VERSION ""

NS_ :

BS_:

BU_: BAP_Tester BedienDisp_vo BedienSG_hi CGS DDA Gateway Gateway_PAG GurtMikrofon OTA_FC ZR_High ZR_LIMU ZR_MIB_TOP_ab_Gen3 ZR_Standard

BO_ 981 Licht_Anf_01: 8 Gateway
 SG_ Licht_Anf_01_CRC : 0|8@1+ (1,0) [0|255] "" Vector__XXX
 SG_ Licht_Anf_01_BZ : 8|4@1+ (1,0) [0|15] "" Vector__XXX
 SG_ BCM1_Kurvenlicht_links_Anf : 12|1@1+ (1,0) [0|1] "" ZR_High
 SG_ BCM1_Kurvenlicht_rechts_Anf : 13|1@1+ (1,0) [0|1] "" ZR_High
 SG_ BCM1_Standlicht_Anf : 14|1@1+ (1,0) [0|1] "" ZR_High
 SG_ BCM1_Abblendlicht_Anf : 15|1@1+ (1,0) [0|1] "" OTA_FC,ZR_High
 SG_ BCM1_Fernlicht_Anf : 16|1@1+ (1,0) [0|1] "" ZR_High
 SG_ BCM1_Nebellicht_Anf : 17|1@1+ (1,0) [0|1] "" ZR_High
 SG_ BCM1_Parklicht_li_Anf : 18|1@1+ (1,0) [0|1] "" ZR_High
 SG_ BCM1_Parklicht_re_Anf : 19|1@1+ (1,0) [0|1] "" ZR_High
 SG_ BCM1_Nebelschluss_Ahg_Anf : 20|1@1+ (1,0) [0|1] "" ZR_High
 SG_ BCM1_Nebelschluss_Fzg_Anf : 21|1@1+ (1,0) [0|1] "" ZR_High
 SG_ BCM1_Schlusslicht_Anf : 22|1@1+ (1,0) [0|1] "" ZR_High
 SG_ BCM_Rueckfahrlicht_Anf : 23|1@1+ (1,0) [0|1] "" ZR_High,ZR_MIB_TOP_ab_Gen3,ZR_Standard
 SG_ BCM1_Signaturlicht_Anf : 24|1@1+ (1,0) [0|1] "" Vector__XXX
 SG_ BCM1_Umfeldleuchten_Anf : 25|1@1+ (1,0) [0|1] "" ZR_High
 SG_ BCM1_Tagfahrlicht_Anf : 26|1@1+ (1,0) [0|1] "" ZR_High
 SG_ BCM1_Regenlicht_Anf : 27|1@1+ (1,0) [0|1] "" ZR_High
 SG_ BCM1_Autobahnlicht_Anf : 28|1@1+ (1,0) [0|1] "" ZR_High
 SG_ BCM1_Touristen_Licht_Anf : 29|1@1+ (1,0) [0|1] "" ZR_High
 SG_ BCM1_CH_aktiv : 30|1@1+ (1,0) [0|1] "" ZR_High
 SG_ BCM1_LH_aktiv : 31|1@1+ (1,0) [0|1] "" ZR_High
 SG_ BCM1_Gleitende_Leuchtw_Anf : 32|1@1+ (1,0) [0|1] "" ZR_High
 SG_ BCM1_GLW_Fernlicht_Anf : 33|1@1+ (1,0) [0|1] "" ZR_High
 SG_ BCM1_Adaptive_Lichtvert_Anf : 34|1@1+ (1,0) [0|1] "" ZR_High
 SG_ BCM1_FoD_Sperrung_WiBli : 35|2@1+ (1,0) [0|3] "" Vector__XXX
 SG_ BCM1_FOD_Sperrung_Animationen_HL : 37|2@1+ (1,0) [0|3] "" Vector__XXX
 SG_ BCM1_Animationssperrung : 39|1@1+ (1,0) [0|1] "" Vector__XXX
 SG_ BCM1_CH_LH_aktiv : 40|1@1+ (1,0) [0|1] "" ZR_High
 SG_ BCM1_Allwetterlicht_Anf : 41|1@1+ (1,0) [0|1] "" ZR_High
 SG_ BCM1_Schlusslicht_Signatur : 60|4@1+ (1,0) [0|15] "" Vector__XXX

BO_ 982 Licht_hinten_01: 8 Gateway
 SG_ BCM2_Bremsl_durch_ECD : 5|1@1+ (1,0) [0|1] "" OTA_FC,ZR_High
 SG_ LH_Aussenlicht_def : 7|1@1+ (1,0) [0|1] "" ZR_High
 SG_ LH_Standlicht_H_aktiv : 8|1@1+ (1,0) [0|1] "" OTA_FC,ZR_High
 SG_ LH_Parklicht_HL_aktiv : 9|1@1+ (1,0) [0|1] "" OTA_FC,ZR_High
 SG_ LH_Parklicht_HR_aktiv : 10|1@1+ (1,0) [0|1] "" OTA_FC,ZR_High
 SG_ LH_Bremslicht_H_aktiv : 11|1@1+ (1,0) [0|1] "" OTA_FC,ZR_High
 SG_ LH_Nebelschluss_aktiv : 12|1@1+ (1,0) [0|1] "" OTA_FC,ZR_High
 SG_ LH_Rueckfahrlicht_aktiv : 13|1@1+ (1,0) [0|1] "" OTA_FC,ZR_High
 SG_ LH_Blinker_HL_akt : 14|1@1+ (1,0) [0|1] "" OTA_FC,ZR_High
 SG_ LH_Blinker_HR_akt : 15|1@1+ (1,0) [0|1] "" OTA_FC,ZR_High
 SG_ LH_Blinker_li_def : 16|1@1+ (1,0) [0|1] "" ZR_High
 SG_ LH_Bremsl_li_def : 17|1@1+ (1,0) [0|1] "" ZR_High
 SG_ LH_Schlusslicht_li_def : 18|1@1+ (1,0) [0|1] "" ZR_High
 SG_ LH_Rueckf_li_def : 19|1@1+ (1,0) [0|1] "" ZR_High
 SG_ LH_Nebel_li_def : 20|1@1+ (1,0) [0|1] "" ZR_High
 SG_ LH_Schluss_Brems_Nebel_li_def : 21|1@1+ (1,0) [0|1] "" ZR_High
 SG_ LH_Schluss_Brems_Nebel_re_def : 22|1@1+ (1,0) [0|1] "" ZR_High
 SG_ LH_Zusatzschlussl_def : 23|1@1+ (1,0) [0|1] "" Vector__XXX
 SG_ LH_Schluss_Brems_li_def : 24|1@1+ (1,0) [0|1] "" ZR_High
 SG_ LH_Schluss_Nebel_li_def : 25|1@1+ (1,0) [0|1] "" ZR_High
 SG_ LH_SL_BRL_BLK_li_def : 26|1@1+ (1,0) [0|1] "" ZR_High
 SG_ LH_Brems_Blk_li_def : 27|1@1+ (1,0) [0|1] "" Vector__XXX
 SG_ LH_Diag_Status_re_def : 28|1@1+ (1,0) [0|1] "" ZR_High
 SG_ LH_Diag_Status_li_def : 29|1@1+ (1,0) [0|1] "" ZR_High
 SG_ LH_Diag_LED_li_def : 30|1@1+ (1,0) [0|1] "" ZR_High
 SG_ LH_Diag_LED_re_def : 31|1@1+ (1,0) [0|1] "" ZR_High
 SG_ LH_Blinker_re_def : 32|1@1+ (1,0) [0|1] "" ZR_High
 SG_ LH_Bremsl_re_def : 33|1@1+ (1,0) [0|1] "" ZR_High
 SG_ LH_Schlusslicht_re_def : 34|1@1+ (1,0) [0|1] "" ZR_High
 SG_ LH_Rueckf_re_def : 35|1@1+ (1,0) [0|1] "" ZR_High
 SG_ LH_Nebel_re_def : 36|1@1+ (1,0) [0|1] "" ZR_High
 SG_ LH_Schluss_Brems_mi_def : 37|1@1+ (1,0) [0|1] "" Vector__XXX
 SG_ LH_Schluss_Brems_re_def : 40|1@1+ (1,0) [0|1] "" ZR_High
 SG_ LH_Schluss_Nebel_re_def : 41|1@1+ (1,0) [0|1] "" ZR_High
 SG_ LH_SL_BRL_BLK_re_def : 42|1@1+ (1,0) [0|1] "" ZR_High
 SG_ LH_Brems_Blk_re_def : 43|1@1+ (1,0) [0|1] "" ZR_High
 SG_ LH_Kennzl_def : 48|1@1+ (1,0) [0|1] "" ZR_High
 SG_ LH_3_Bremsl_def : 49|1@1+ (1,0) [0|1] "" ZR_High
 SG_ LH_Nebel_mi_def : 50|1@1+ (1,0) [0|1] "" ZR_High
 SG_ LH_Rueckf_mi_def : 51|1@1+ (1,0) [0|1] "" ZR_High
 SG_ LH_Schlusslicht_mi_def : 52|1@1+ (1,0) [0|1] "" Vector__XXX
 SG_ LH_Bremsl_mi_def : 53|1@1+ (1,0) [0|1] "" Vector__XXX
 SG_ LH_Bremsl_li_ges_def : 54|1@1+ (1,0) [0|1] "" ZR_High
 SG_ LH_Bremsl_re_ges_def : 55|1@1+ (1,0) [0|1] "" ZR_High

BO_ 987 Gateway_72: 8 Gateway_MQB
 SG_ BCM_01_alt : 0|1@1+ (1,0) [0|1] "" Airbag_MQB
 SG_ SMLS_01_alt : 1|1@1+ (1,0) [0|1] "" Motor_Diesel_MQB,Motor_Otto_MQB
 SG_ ZV_02_alt : 2|1@1+ (1,0) [0|1] "" Getriebe_DQ_Hybrid_MQB,Getriebe_DQ_MQB,Motor_Diesel_MQB,Motor_Hybrid_MQB,Motor_Otto_MQB
 SG_ Wischer_01_alt : 3|1@1+ (1,0) [0|1] "" Motor_Diesel_MQB,Motor_Hybrid_MQB,Motor_Otto_MQB
 SG_ Anhaenger_01_alt : 4|1@1+ (1,0) [0|1] "" Getriebe_DQ_Hybrid_MQB,Getriebe_DQ_MQB
 SG_ Klima_Sensor_02_alt : 5|1@1+ (1,0) [0|1] "" Getriebe_DQ_Hybrid_MQB,Getriebe_DQ_MQB,Motor_Diesel_MQB,Motor_Hybrid_MQB,Motor_Otto_MQB
 SG_ VSG_01_alt : 6|1@1+ (1,0) [0|1] "" Airbag_MQB
 SG_ Klima_01_alt : 7|1@1+ (1,0) [0|1] "" Vector__XXX
 SG_ WFS_01_alt : 8|1@1+ (1,0) [0|1] "" Vector__XXX
 SG_ Licht_Anf_01_alt : 9|1@1+ (1,0) [0|1] "" Vector__XXX
 SG_ ZV_HFS_offen : 20|1@1+ (1,0) [0|1] "" Vector__XXX
 SG_ ZV_HBFS_offen : 21|1@1+ (1,0) [0|1] "" Vector__XXX
 SG_ VS_VD_offen_ver : 22|1@1+ (1,0) [0|1] "" Airbag_MQB
 SG_ VS_VD_zu_ver : 23|1@1+ (1,0) [0|1] "" Vector__XXX
 SG_ ZV_BT_offen : 24|1@1+ (1,0) [0|1] "" Vector__XXX
 SG_ BCM1_Rueckfahrlicht_Schalter : 25|1@1+ (1,0) [0|1] "" Airbag_MQB
 SG_ ZV_FT_offen : 26|1@1+ (1,0) [0|1] "" Getriebe_DQ_Hybrid_MQB,Getriebe_DQ_MQB,Motor_Diesel_MQB,Motor_Hybrid_MQB,Motor_Otto_MQB
 SG_ Wischer_vorne_aktiv : 27|1@1+ (1,0) [0|1] "" Motor_Diesel_MQB,Motor_Hybrid_MQB,Motor_Otto_MQB
 SG_ AAG_Anhaenger_erkannt : 28|1@1+ (1,0) [0|1] "" Getriebe_DQ_Hybrid_MQB,Getriebe_DQ_MQB
 SG_ BCM1_MH_Schalter : 29|1@1+ (1,0) [0|1] "" Vector__XXX
 SG_ ZV_HD_offen : 30|1@1+ (1,0) [0|1] "" Vector__XXX
 SG_ Waschen_vorne_aktiv : 31|1@1+ (1,0) [0|1] "" Vector__XXX
 SG_ KL_Thermomanagement : 32|2@1+ (1,0) [0|3] "" Vector__XXX
 SG_ WFS_Schluessel_Fahrberecht : 34|4@1+ (1,0) [0|15] "" Vector__XXX
 SG_ BCM1_RFahrlicht_Fzg_Anf : 38|1@1+ (1,0) [0|1] "" Vector__XXX
 SG_ BCM1_RFahrlicht_Ahg_Anf : 39|1@1+ (1,0) [0|1] "" Vector__XXX
 SG_ BH_Fernlicht : 49|1@1+ (1,0) [0|1] "" Vector__XXX
 SG_ BH_Blinker_li : 50|1@1+ (1,0) [0|1] "" Motor_Diesel_MQB,Motor_Otto_MQB
 SG_ BH_Blinker_re : 51|1@1+ (1,0) [0|1] "" Motor_Diesel_MQB,Motor_Otto_MQB
 SG_ BCM1_OBD_FStatus_ATemp : 52|4@1+ (1,0) [0|15] "" Getriebe_DQ_Hybrid_MQB,Getriebe_DQ_MQB,Motor_Diesel_MQB,Motor_Hybrid_MQB,Motor_Otto_MQB
 SG_ BCM1_Aussen_Temp_ungef : 56|8@1+ (0.5,-50) [-50|76] "Unit_DegreCelsi" Getriebe_DQ_Hybrid_MQB,Getriebe_DQ_MQB,Motor_Diesel_MQB,Motor_Hybrid_MQB,Motor_Otto_MQB

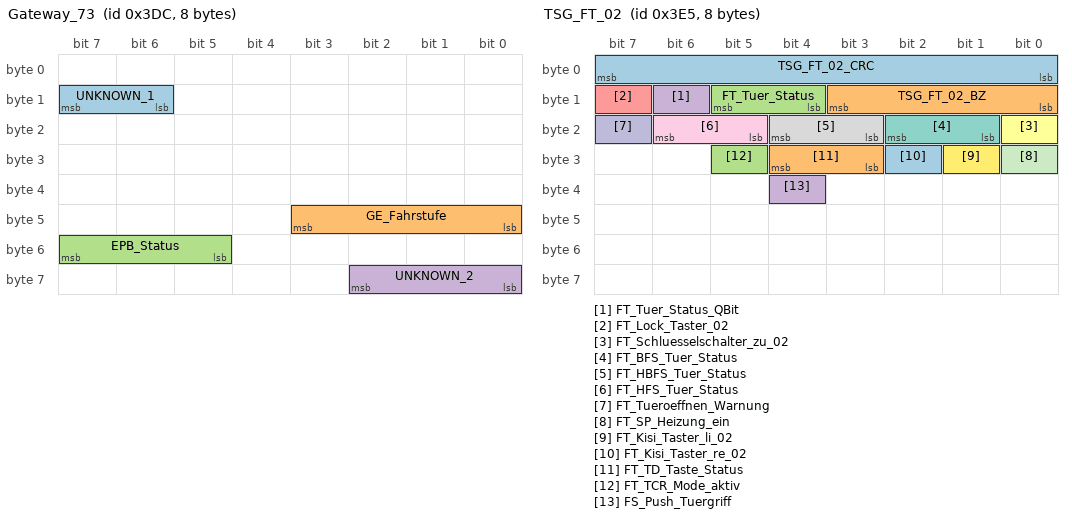
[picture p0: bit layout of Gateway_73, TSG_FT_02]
BO_ 988 Gateway_73: 8 XXX
 SG_ UNKNOWN_1 : 15|2@0+ (1,0) [0|3] "" XXX
 SG_ GE_Fahrstufe : 40|4@1+ (1,0) [0|15] "" XXX
 SG_ EPB_Status : 53|3@1+ (1,0) [0|7] "" XXX
 SG_ UNKNOWN_2 : 58|3@0+ (1,0) [0|7] "" XXX

BO_ 997 TSG_FT_02: 8 Gateway
 SG_ TSG_FT_02_CRC : 0|8@1+ (1,0) [0|255] "" Vector__XXX
 SG_ TSG_FT_02_BZ : 8|4@1+ (1,0) [0|15] "" Vector__XXX
 SG_ FT_Tuer_Status : 12|2@1+ (1,0) [0|3] "" OTA_FC,ZR_High
 SG_ FT_Tuer_Status_QBit : 14|1@1+ (1,0) [0|1] "" ZR_High
 SG_ FT_Lock_Taster_02 : 15|1@1+ (1,0) [0|1] "" ZR_High
 SG_ FT_Schluesselschalter_zu_02 : 16|1@1+ (1,0) [0|1] "" ZR_High
 SG_ FT_BFS_Tuer_Status : 17|2@1+ (1,0) [0|3] "" ZR_High
 SG_ FT_HBFS_Tuer_Status : 19|2@1+ (1,0) [0|3] "" ZR_High
 SG_ FT_HFS_Tuer_Status : 21|2@1+ (1,0) [0|3] "" ZR_High
 SG_ FT_Tueroeffnen_Warnung : 23|1@1+ (1,0) [0|1] "" Vector__XXX
 SG_ FT_SP_Heizung_ein : 24|1@1+ (1,0) [0|1] "" Vector__XXX
 SG_ FT_Kisi_Taster_li_02 : 25|1@1+ (1,0) [0|1] "" ZR_High
 SG_ FT_Kisi_Taster_re_02 : 26|1@1+ (1,0) [0|1] "" ZR_High
 SG_ FT_TD_Taste_Status : 27|2@1+ (1,0) [0|3] "" ZR_High
 SG_ FT_TCR_Mode_aktiv : 29|1@1+ (1,0) [0|1] "" Vector__XXX
 SG_ FS_Push_Tuergriff : 36|1@1+ (1,0) [0|1] "" Vector__XXX

BO_ 1004 MEB_TSK_01: 8 XXX
 SG_ TSK_State : 53|3@1+ (1,0) [0|7] "" XXX

BO_ 1031 PLA_04: 8 XXX

BO_ 1122 PSD_04: 8 ZR_High
 SG_ PSD_Segment_ID : 0|6@1+ (1,0) [2|63] "" Gateway,Gateway_PAG
 SG_ PSD_Vorgaenger_Segment_ID : 6|6@1+ (1,0) [2|63] "" Gateway,Gateway_PAG
 SG_ PSD_Segmentlaenge : 12|7@1+ (2,0) [0|254] "Unit_Meter" Gateway,Gateway_PAG,OTA_FC
 SG_ PSD_Strassenkategorie : 19|3@1+ (1,0) [0|7] "" Gateway,Gateway_PAG,OTA_FC
 SG_ PSD_Endkruemmung : 22|8@1+ (1,0) [0|254] "Unit_None" Gateway,Gateway_PAG
 SG_ PSD_Endkruemmung_Vorz : 30|1@1+ (1,0) [0|1] "" Gateway,Gateway_PAG
 SG_ PSD_Idenditaets_ID : 31|6@1+ (1,0) [2|63] "" Gateway,Gateway_PAG
 SG_ PSD_ADAS_Qualitaet : 37|1@1+ (1,0) [0|1] "" Gateway,Gateway_PAG
 SG_ PSD_wahrscheinlichster_Pfad : 38|1@1+ (1,0) [0|1] "" Gateway,Gateway_PAG
 SG_ PSD_Geradester_Pfad : 39|1@1+ (1,0) [0|1] "" Gateway,Gateway_PAG
 SG_ PSD_Fahrspuren_Anzahl : 40|3@1+ (1,0) [0|7] "" Gateway,Gateway_PAG,OTA_FC
 SG_ PSD_Bebauung : 43|1@1+ (1,0) [0|1] "" Gateway,Gateway_PAG
 SG_ PSD_Segment_Komplett : 44|1@1+ (1,0) [0|1] "" Gateway,Gateway_PAG
 SG_ PSD_Rampe : 45|2@1+ (1,0) [0|3] "" Gateway,Gateway_PAG
 SG_ PSD_Anfangskruemmung : 47|8@1+ (1,0) [0|254] "" Gateway,Gateway_PAG
 SG_ PSD_Anfangskruemmung_Vorz : 55|1@1+ (1,0) [0|1] "" Gateway,Gateway_PAG
 SG_ PSD_Abzweigerichtung : 56|1@1+ (1,0) [0|1] "" Gateway,Gateway_PAG
 SG_ PSD_Abzweigewinkel : 57|7@1+ (1.417323,0) [0|180.000021] "" Gateway,Gateway_PAG

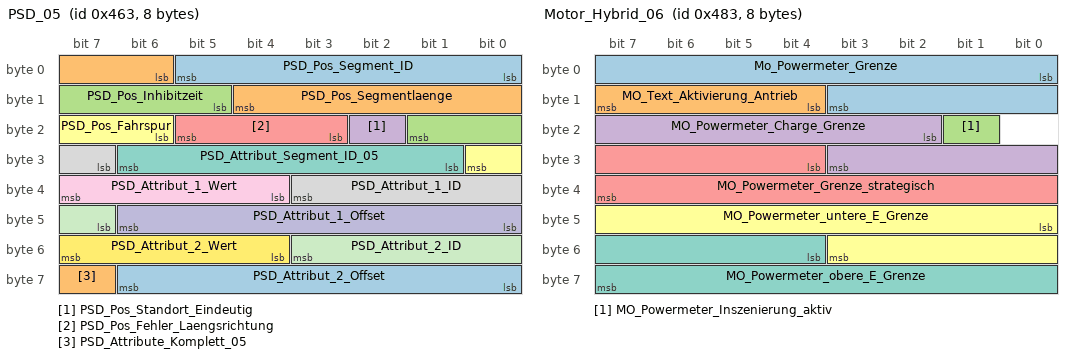
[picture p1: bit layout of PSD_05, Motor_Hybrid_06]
BO_ 1123 PSD_05: 8 ZR_High
 SG_ PSD_Pos_Segment_ID : 0|6@1+ (1,0) [2|63] "" Gateway,Gateway_PAG
 SG_ PSD_Pos_Segmentlaenge : 6|7@1+ (2,0) [0|254] "Unit_Meter" Gateway,Gateway_PAG
 SG_ PSD_Pos_Inhibitzeit : 13|5@1+ (10,0) [0|310] "Unit_MilliSecon" Gateway,Gateway_PAG
 SG_ PSD_Pos_Standort_Eindeutig : 18|1@1+ (1,0) [0|1] "" Gateway,Gateway_PAG
 SG_ PSD_Pos_Fehler_Laengsrichtung : 19|3@1+ (1,0) [0|7] "" Gateway,Gateway_PAG
 SG_ PSD_Pos_Fahrspur : 22|3@1+ (1,0) [0|7] "" Gateway,Gateway_PAG,OTA_FC
 SG_ PSD_Attribut_Segment_ID_05 : 25|6@1+ (1,0) [2|63] "" Gateway,Gateway_PAG
 SG_ PSD_Attribut_1_ID : 31|5@1+ (1,0) [1|31] "" Gateway,Gateway_PAG
 SG_ PSD_Attribut_1_Wert : 36|4@1+ (1,0) [0|15] "" Gateway,Gateway_PAG
 SG_ PSD_Attribut_1_Offset : 40|7@1+ (2,0) [0|254] "Unit_Meter" Gateway,Gateway_PAG
 SG_ PSD_Attribut_2_ID : 47|5@1+ (1,0) [1|31] "" Gateway,Gateway_PAG
 SG_ PSD_Attribut_2_Wert : 52|4@1+ (1,0) [0|15] "" Gateway,Gateway_PAG
 SG_ PSD_Attribut_2_Offset : 56|7@1+ (2,0) [0|254] "Unit_Meter" Gateway,Gateway_PAG
 SG_ PSD_Attribute_Komplett_05 : 63|1@1+ (1,0) [0|1] "" Gateway,Gateway_PAG

BO_ 1124 PSD_06: 8 ZR_High
 SG_ PSD_06_Mux M : 0|3@1+ (1,0) [0|7] "" Gateway,Gateway_PAG
 SG_ PSD_Sys_Segment_ID m0 : 3|6@1+ (1,0) [2|63] "" Gateway,Gateway_PAG
 SG_ PSD_Sys_Laendercode m0 : 9|8@1+ (1,0) [0|255] "" Gateway,Gateway_PAG
 SG_ PSD_Sys_Geschwindigkeit_Einheit m0 : 17|1@1+ (1,0) [0|1] "" Gateway,Gateway_PAG
 SG_ PSD_Sys_Verkehrsrichtung m0 : 18|1@1+ (1,0) [0|1] "" Gateway,Gateway_PAG
 SG_ PSD_Sys_Geometrieguete m0 : 19|2@1+ (1,0) [0|3] "" Gateway,Gateway_PAG
 SG_ PSD_Sys_Mapmatchingguete m0 : 21|2@1+ (1,0) [0|3] "" Gateway,Gateway_PAG
 SG_ PSD_Sys_Alter_Karte m0 : 23|3@1+ (1,0) [0|7] "" Gateway,Gateway_PAG
 SG_ PSD_Sys_Zielfuehrung m0 : 26|1@1+ (1,0) [0|1] "" Gateway,Gateway_PAG,OTA_FC
 SG_ PSD_Sys_US_State m0 : 27|6@1+ (1,0) [0|63] "" Gateway,Gateway_PAG
 SG_ PSD_Sys_Quali_Geometrien m0 : 33|3@1+ (1,0) [0|7] "Unit_None" Gateway,Gateway_PAG
 SG_ PSD_Sys_Quali_Ortsinfo m0 : 36|2@1+ (1,0) [0|3] "Unit_None" Gateway,Gateway_PAG
 SG_ PSD_Sys_Quali_verfuegbar m0 : 38|1@1+ (1,0) [0|1] "" Gateway,Gateway_PAG
 SG_ PSD_Sys_Zielfuehrung_geaendert m0 : 39|1@1+ (1,0) [0|1] "" Gateway,Gateway_PAG
 SG_ PSD_Sys_Geometrieguete_erweitert m0 : 40|8@1+ (1,0) [0|255] "" Gateway,Gateway_PAG
 SG_ PSD_Sys_Quali_sonstige_Attribute m0 : 48|3@1+ (1,0) [0|7] "Unit_None" Gateway,Gateway_PAG
 SG_ PSD_Sys_Quali_Steigungen m0 : 51|3@1+ (1,0) [0|7] "" Gateway,Gateway_PAG
 SG_ PSD_Sys_Quali_Strassenkennz m0 : 54|3@1+ (1,0) [0|7] "Unit_None" Gateway,Gateway_PAG
 SG_ PSD_Sys_Quali_Tempolimits m0 : 57|3@1+ (1,0) [0|7] "Unit_None" Gateway,Gateway_PAG
 SG_ PSD_Sys_Quali_Vorfahrtsregelung m0 : 60|3@1+ (1,0) [0|7] "Unit_None" Gateway,Gateway_PAG
 SG_ PSD_Attribut_Segment_ID m1 : 3|6@1+ (1,0) [2|63] "" Gateway,Gateway_PAG
 SG_ PSD_Attribut_3_ID m1 : 9|5@1+ (1,0) [1|31] "" Gateway,Gateway_PAG
 SG_ PSD_Attribut_3_Offset m1 : 14|7@1+ (2,0) [0|254] "Unit_Meter" Gateway,Gateway_PAG
 SG_ PSD_Attribut_3_Wert m1 : 21|4@1+ (1,0) [0|15] "" Gateway,Gateway_PAG
 SG_ PSD_Attribut_4_ID m1 : 25|5@1+ (1,0) [1|31] "" Gateway,Gateway_PAG
 SG_ PSD_Attribut_4_Wert m1 : 30|4@1+ (1,0) [0|15] "" Gateway,Gateway_PAG
 SG_ PSD_Attribut_4_Offset m1 : 34|7@1+ (2,0) [0|254] "Unit_Meter" Gateway,Gateway_PAG
 SG_ PSD_Attribut_5_ID m1 : 41|5@1+ (1,0) [1|31] "" Gateway,Gateway_PAG
 SG_ PSD_Attribut_5_Offset m1 : 46|7@1+ (2,0) [0|254] "Unit_Meter" Gateway,Gateway_PAG
 SG_ PSD_Attribut_5_Wert m1 : 53|4@1+ (1,0) [0|15] "" Gateway,Gateway_PAG
 SG_ PSD_Attribute_Komplett_06 m1 : 57|1@1+ (1,0) [0|1] "" Gateway,Gateway_PAG
 SG_ PSD_Ges_Segment_ID m2 : 3|6@1+ (1,0) [2|63] "" Gateway,Gateway_PAG
 SG_ PSD_Ges_Offset m2 : 9|7@1+ (2,0) [0|254] "Unit_Meter" Gateway,Gateway_PAG
 SG_ PSD_Ges_Geschwindigkeit m2 : 16|5@1+ (1,0) [0|31] "" Gateway,Gateway_PAG,OTA_FC
 SG_ PSD_Ges_Typ m2 : 21|2@1+ (1,0) [0|3] "" Gateway,Gateway_PAG
 SG_ PSD_Ges_Spur_Geschw_Begrenzung m2 : 23|6@1+ (1,0) [0|63] "" Gateway,Gateway_PAG
 SG_ PSD_Ges_Geschwindigkeit_Gespann m2 : 29|2@1+ (1,0) [0|3] "" Gateway,Gateway_PAG
 SG_ PSD_Ges_Geschwindigkeit_Witter m2 : 31|2@1+ (1,0) [0|3] "" Gateway,Gateway_PAG
 SG_ PSD_Ges_Geschwindigkeit_Tag_Anf m2 : 33|3@1+ (1,0) [0|7] "" Gateway,Gateway_PAG
 SG_ PSD_Ges_Geschwindigkeit_Tag_Ende m2 : 36|3@1+ (1,0) [0|7] "" Gateway,Gateway_PAG
 SG_ PSD_Ges_Geschwindigkeit_Std_Anf m2 : 39|5@1+ (1,0) [0|24] "Unit_Hours" Gateway,Gateway_PAG
 SG_ PSD_Ges_Geschwindigkeit_Std_Ende m2 : 44|5@1+ (1,0) [0|24] "Unit_Hours" Gateway,Gateway_PAG
 SG_ PSD_Ges_Ueberholverbot m2 : 49|2@1+ (1,0) [0|3] "" Gateway,Gateway_PAG
 SG_ PSD_Ges_Wechselverkehrszeichen m2 : 51|3@1+ (1,0) [0|7] "" Gateway,Gateway_PAG
 SG_ PSD_Wechselverkehrszeichen_Typ m2 : 54|2@1+ (1,0) [0|3] "" Gateway,Gateway_PAG
 SG_ PSD_Ges_Gesetzlich_Kategorie m2 : 56|3@1+ (1,0) [0|7] "" Gateway,Gateway_PAG
 SG_ PSD_Ges_Gesetzlich_Zusatz m2 : 59|2@1+ (1,0) [0|3] "" Gateway,Gateway_PAG
 SG_ PSD_Ges_Verkehrszeichen_Quelle m2 : 61|2@1+ (1,0) [0|3] "" Gateway,Gateway_PAG
 SG_ PSD_Ges_Attribute_Komplett m2 : 63|1@1+ (1,0) [0|1] "" Gateway,Gateway_PAG
 SG_ PSD_Baum_Laenge_VZ m3 : 3|1@1+ (1,0) [0|1] "" Gateway,Gateway_PAG
 SG_ PSD_Baum_Laenge m3 : 4|25@1+ (1e-05,0) [0|180] "Unit_DegreOfArc" Gateway,Gateway_PAG
 SG_ PSD_Baum_Breite_VZ m3 : 29|1@1+ (1,0) [0|1] "" Gateway,Gateway_PAG
 SG_ PSD_Baum_Breite m3 : 30|24@1+ (1e-05,0) [0|90] "Unit_DegreOfArc" Gateway,Gateway_PAG
 SG_ PSD_Baum_Ausrichtung m3 : 54|10@1+ (0.3515625,0) [0|359.6484375] "Unit_DegreOfArc" Gateway,Gateway_PAG
 SG_ PSD_Steigung_1_Segment_ID m4 : 3|6@1+ (1,0) [2|63] "" Gateway,Gateway_PAG
 SG_ PSD_Steigung_1_A_Steigung m4 : 9|7@1+ (0.12,0) [0|15] "Unit_PerCent" Gateway,Gateway_PAG
 SG_ PSD_Steigung_1_A_Vorz m4 : 16|1@1+ (1,0) [0|1] "" Gateway,Gateway_PAG
 SG_ PSD_Steigung_1_A_Offset m4 : 17|7@1+ (2,0) [0|254] "Unit_Meter" Gateway,Gateway_PAG
 SG_ PSD_Steigung_1_B_Steigung m4 : 24|7@1+ (0.12,0) [0|15] "Unit_PerCent" Gateway,Gateway_PAG
 SG_ PSD_Steigung_1_B_Vorz m4 : 31|1@1+ (1,0) [0|1] "" Gateway,Gateway_PAG
 SG_ PSD_Steigung_1_B_Offset m4 : 32|7@1+ (2,0) [0|254] "Unit_Meter" Gateway,Gateway_PAG
 SG_ PSD_Steigung_1_Attribute_kompl m4 : 39|1@1+ (1,0) [0|1] "" Gateway,Gateway_PAG
 SG_ PSD_Steigung_2_Segment_ID m4 : 40|6@1+ (1,0) [2|63] "" Gateway,Gateway_PAG
 SG_ PSD_Steigung_2_Steigung m4 : 46|7@1+ (0.12,0) [0|15] "Unit_PerCent" Gateway,Gateway_PAG
 SG_ PSD_Steigung_2_Vorz m4 : 53|1@1+ (1,0) [0|1] "" Gateway,Gateway_PAG
 SG_ PSD_Steigung_2_Offset m4 : 54|7@1+ (2,0) [0|254] "Unit_Meter" Gateway,Gateway_PAG
 SG_ PSD_Steigung_2_Attribute_kompl m4 : 61|1@1+ (1,0) [0|1] "" Gateway,Gateway_PAG

BO_ 1153 MainUnit_01: 8 ZR_High
 SG_ ZR_LoGeWa_Event_Kombiwarnung : 0|4@1+ (1,0) [0|15] "" Gateway,Gateway_PAG
 SG_ Nav_FoD_Status : 4|3@1+ (1,0) [0|7] "" Gateway,Gateway_PAG
 SG_ MIB_Tongenerator_PH_verfuegbar : 9|3@1+ (1,0) [0|7] "" Gateway,Gateway_PAG
 SG_ MMI_Counter_Bedienevent : 12|4@1+ (1,0) [0|15] "" Gateway,Gateway_PAG
 SG_ DSSS_Warning : 16|5@1+ (1,0) [0|31] "" Gateway,Gateway_PAG
 SG_ ZR_Kindersicherung_RSE : 21|1@1+ (1,0) [0|1] "" Gateway,Gateway_PAG
 SG_ ZR_RSE_aktivieren : 22|1@1+ (1,0) [0|1] "" Gateway,Gateway_PAG
 SG_ MMI_SDS_aktiv : 23|1@1+ (1,0) [0|1] "" Gateway,Gateway_PAG
 SG_ MU_SecondDisplay : 24|3@1+ (1,0) [0|7] "" Gateway,Gateway_PAG
 SG_ MMI_Telefon_aktiv : 27|1@1+ (1,0) [0|1] "" Gateway,Gateway_PAG
 SG_ MMI_Gurt_Mic_ref : 28|1@1+ (1,0) [0|1] "" Gateway,Gateway_PAG,GurtMikrofon
 SG_ ZR_Sta_Inszenierung : 29|2@1+ (1,0) [0|3] "" Gateway,Gateway_PAG
 SG_ MMI_Gauges_active : 31|1@1+ (1,0) [0|1] "" BedienDisp_vo,Gateway,Gateway_PAG
 SG_ MU_Update_Time : 32|8@1+ (0.1,0) [0|25.5] "Unit_Hours" Gateway,Gateway_PAG
 SG_ ZR_MXB_Manoever_Ansage : 42|2@1+ (1,0) [0|3] "" Gateway,Gateway_PAG
 SG_ ZR_LAPP_Sondermodus_Status : 44|2@1+ (1,0) [0|3] "" DDA,Gateway,Gateway_PAG
 SG_ MMI_StartStopp_Info : 46|2@1+ (1,0) [0|3] "" Gateway,Gateway_PAG
 SG_ ZR_Parken_Sondermodus : 48|4@1+ (1,0) [0|15] "" DDA,Gateway,Gateway_PAG
 SG_ ZR_Rundenbewertung : 52|4@1+ (1,0) [0|15] "" Gateway,Gateway_PAG
 SG_ ZR_Rundenfortschritt : 56|8@1+ (0.5,0) [0|100] "Unit_PerCent" Gateway,Gateway_PAG

BO_ 1155 Motor_Hybrid_06: 8 Gateway
 SG_ Mo_Powermeter_Grenze : 0|12@1+ (1,0) [0|4092] "" ZR_High,ZR_LIMU,ZR_MIB_TOP_ab_Gen3
 SG_ MO_Text_Aktivierung_Antrieb : 12|4@1+ (1,0) [0|15] "" Vector__XXX
 SG_ MO_Powermeter_Inszenierung_aktiv : 17|1@1+ (1,0) [0|1] "" Vector__XXX
 SG_ MO_Powermeter_Charge_Grenze : 18|10@1+ (1,0) [0|1021] "Unit_None" Vector__XXX
 SG_ MO_Powermeter_Grenze_strategisch : 28|12@1+ (1,0) [0|4093] "Unit_None" Vector__XXX
 SG_ MO_Powermeter_untere_E_Grenze : 40|12@1+ (1,0) [0|4093] "Unit_None" Vector__XXX
 SG_ MO_Powermeter_obere_E_Grenze : 52|12@1+ (1,0) [0|4093] "Unit_None" Vector__XXX

BO_ 1163 BEM_06: 8 XXX
 SG_ CRC : 0|8@1+ (1,0) [0|255] "" XXX
 SG_ CHK : 8|4@1+ (1,0) [0|15] "" XXX

BO_ 1175 Parkhilfe_01: 8 Gateway
 SG_ PH_Visualisierung : 0|3@1+ (1,0) [0|7] "" AWC
 SG_ PDC_Tonausgabe_Front : 4|4@1+ (1,0) [0|15] "" Vector__XXX
 SG_ PDC_Tonausgabe_Heck : 8|4@1+ (1,0) [0|15] "" Vector__XXX
 SG_ PH_nachtr_Stopp_Anf : 12|1@1+ (1,0) [0|1] "" Vector__XXX
 SG_ PH_Abschaltursache : 13|3@1+ (1,0) [0|7] "" AWC
 SG_ PH_Opt_Anzeige_V_ein : 16|1@1+ (1,0) [0|1] "" Vector__XXX
 SG_ PH_Opt_Anzeige_H_ein : 17|1@1+ (1,0) [0|1] "" Vector__XXX
 SG_ PH_Opt_Anz_V_Hindernis : 18|1@1+ (1,0) [0|1] "" Vector__XXX
 SG_ PH_Opt_Anz_H_Hindernis : 19|1@1+ (1,0) [0|1] "" Vector__XXX
 SG_ PH_Tongeber_V_aktiv : 20|1@1+ (1,0) [0|1] "" Vector__XXX
 SG_ PH_Tongeber_H_aktiv : 21|1@1+ (1,0) [0|1] "" Vector__XXX
 SG_ PH_Tongeber_mute : 22|1@1+ (1,0) [0|1] "" Vector__XXX
 SG_ PH_Anf_Audioabsenkung : 23|1@1+ (1,0) [0|1] "" Vector__XXX
 SG_ PH_Tongeber_H_verfuegbar : 24|1@1+ (1,0) [0|1] "" Vector__XXX
 SG_ PLA_Anf_Aufschaltung_RVC : 25|1@1+ (1,0) [0|1] "" Vector__XXX
 SG_ PH_Taster : 28|2@1+ (1,0) [0|3] "" Vector__XXX
 SG_ PH_Anf_Verdeck : 30|2@1+ (1,0) [0|3] "" Vector__XXX
 SG_ PH_Frequenz_hinten : 32|4@1+ (1,0) [0|15] "" Vector__XXX
 SG_ PH_Lautstaerke_hinten : 36|4@1+ (1,0) [0|15] "" Vector__XXX
 SG_ PH_Frequenz_vorn : 40|4@1+ (1,0) [0|15] "" Vector__XXX
 SG_ PH_Lautstaerke_vorn : 44|4@1+ (1,0) [0|15] "" Vector__XXX
 SG_ PH_StartStopp_Info : 49|2@1+ (1,0) [0|3] "" Vector__XXX
 SG_ PH_Stoermeldung : 52|4@1+ (1,0) [0|15] "" Vector__XXX
 SG_ PH_defekt : 56|1@1+ (1,0) [0|1] "" Vector__XXX
 SG_ PH_gestoert : 57|1@1+ (1,0) [0|1] "" Vector__XXX
 SG_ PH_Systemzustand : 58|3@1+ (1,0) [0|7] "" AWC
 SG_ PH_Display_Kundenwunsch : 61|2@1+ (1,0) [0|3] "" Vector__XXX

BO_ 1283 HVK_01: 8 Gateway
 SG_ HVK_01_CRC : 0|8@1+ (1,0) [0|255] "" BMC_MLBevo,DCDC_800V_PAG,DCDC_HV,DCDC_HV_02,FCU_MLBevo_FCEV,Ladegeraet_2,Ladegeraet_Konzern,LE1,LE2,LE_MLBevo,TME
 SG_ HVK_01_BZ : 8|4@1+ (1,0) [0|15] "" BMC_MLBevo,DCDC_800V_PAG,DCDC_HV,DCDC_HV_02,FCU_MLBevo_FCEV,Ladegeraet_2,Ladegeraet_Konzern,LE1,LE2,LE_MLBevo,TME
 SG_ HVK_Istmodus_Anf : 12|1@1+ (1,0) [0|1] "" BMC_MLBevo,DCDC_HV,FCU_MLBevo_FCEV,Ladegeraet_2,Ladegeraet_Konzern,LE1,LE2,LE_MLBevo
 SG_ HVK_TN1_Sollmodus : 13|2@1+ (1,0) [0|3] "" DCDC_HV_02,FCU_MLBevo_FCEV
 SG_ HVK_MO_EmSollzustand : 16|8@1+ (1,0) [0|255] "" FCU_MLBevo_FCEV
 SG_ HVK_BMS_Sollmodus : 24|3@1+ (1,0) [0|7] "" BMC_MLBevo,FCU_MLBevo_FCEV
 SG_ HVK_DCDC_Sollmodus : 27|3@1+ (1,0) [0|7] "" DCDC_800V_PAG,DCDC_HV,FCU_MLBevo_FCEV,LE_MLBevo
 SG_ HVK_EKK_Sollmodus : 30|3@1+ (1,0) [0|7] "" FCU_MLBevo_FCEV,TME
 SG_ HVK_HVPTC_Sollmodus : 33|3@1+ (1,0) [0|7] "" FCU_MLBevo_FCEV,TME
 SG_ HVK_HVLM_Sollmodus : 36|3@1+ (1,0) [0|7] "" DCDC_HV_02,FCU_MLBevo_FCEV,Ladegeraet_Konzern
 SG_ HVK_HV_Netz_Warnungen : 39|2@1+ (1,0) [0|3] "" FCU_MLBevo_FCEV
 SG_ HV_Bordnetz_aktiv : 41|1@1+ (1,0) [0|1] "" DCDC_HV_02,FCU_MLBevo_FCEV,Ladegeraet_Konzern,LE1,LE2,LE_MLBevo
 SG_ HV_Bordnetz_Fehler : 42|1@1+ (1,0) [0|1] "" FCU_MLBevo_FCEV,Ladegeraet_Konzern,TME
 SG_ HVK_Gesamtst_Spgfreiheit : 43|2@1+ (1,0) [0|3] "" FCU_MLBevo_FCEV
 SG_ HVK_AktiveEntladung_Anf : 45|1@1+ (1,0) [0|1] "" DCDC_800V_PAG,DCDC_HV,DCDC_HV_02,FCU_MLBevo_FCEV,LE1,LE2,LE_MLBevo
 SG_ HVK_Iso_Messung_Start : 50|3@1+ (1,0) [0|7] "" BMC_MLBevo,FCU_MLBevo_FCEV
 SG_ HVK_DCDC_EKK_Sollmodus : 62|2@1+ (1,0) [0|3] "" DCDC_800V_PAG,FCU_MLBevo_FCEV

BO_ 1312 Airbag_02: 8 Gateway
 SG_ LoGeWa_Event_Kombiwarnung : 12|4@1+ (1,0) [0|15] "" ZR_High
 SG_ AB_Anforderung_eCall : 16|1@1+ (1,0) [0|1] "" ZR_High
 SG_ AB_Anprall_Seite_Beifahrer : 17|1@1+ (1,0) [0|1] "" Vector__XXX
 SG_ AB_Anprall_Rollover : 18|1@1+ (1,0) [0|1] "" Vector__XXX
 SG_ AB_Anprall_FGS : 19|1@1+ (1,0) [0|1] "" Vector__XXX
 SG_ AB_Anprall_Front_Beifahrer : 20|1@1+ (1,0) [0|1] "" Vector__XXX
 SG_ AB_Anprall_Front_Fahrer : 21|1@1+ (1,0) [0|1] "" Vector__XXX
 SG_ AB_Anprall_Heck_Beifahrer : 22|1@1+ (1,0) [0|1] "" Vector__XXX
 SG_ AB_Anprall_Heck_Fahrer : 23|1@1+ (1,0) [0|1] "" Vector__XXX
 SG_ AB_Wickelklappung_Reihe2_MI : 24|2@1+ (1,0) [0|3] "" Vector__XXX
 SG_ AB_Belegung_VB : 26|2@1+ (1,0) [0|3] "" BedienSG_hi,GurtMikrofon,ZR_High,ZR_LIMU,ZR_MIB_TOP_ab_Gen3
 SG_ AB_Abschaltanf_SIH_BF : 28|1@1+ (1,0) [0|1] "" ZR_High
 SG_ AB_Anprall_Seite_Fahrer : 29|1@1+ (1,0) [0|1] "" Vector__XXX
 SG_ SC_PAO_Schriftzug_Anf : 30|2@1+ (1,0) [0|3] "" ZR_High
 SG_ SC_PAO_ON_Anf : 32|2@1+ (1,0) [0|3] "" ZR_High
 SG_ SC_PAO_OFF_Anf : 34|2@1+ (1,0) [0|3] "" ZR_High
 SG_ AB_Crashschwere : 36|3@1+ (1,0) [0|7] "" Vector__XXX
 SG_ AB_Anforderung_USM : 39|1@1+ (1,0) [0|1] "" ZR_Standard
 SG_ AB_Gurtschloss_FA : 40|2@1+ (1,0) [0|3] "" BedienSG_hi,GurtMikrofon,ZR_High
 SG_ AB_Gurtschloss_BF : 42|2@1+ (1,0) [0|3] "" BedienSG_hi,GurtMikrofon,ZR_High,ZR_LIMU,ZR_MIB_TOP_ab_Gen3
 SG_ AB_Gurtschloss_Reihe2_FA : 44|2@1+ (1,0) [0|3] "" BedienSG_hi,ZR_High,ZR_LIMU,ZR_MIB_TOP_ab_Gen3
 SG_ AB_Gurtschloss_Reihe2_MI : 46|2@1+ (1,0) [0|3] "" BedienSG_hi,ZR_High,ZR_LIMU,ZR_MIB_TOP_ab_Gen3
 SG_ AB_Gurtschloss_Reihe2_BF : 48|2@1+ (1,0) [0|3] "" BedienSG_hi,ZR_High,ZR_LIMU,ZR_MIB_TOP_ab_Gen3
 SG_ AB_Gurtschloss_Reihe3_FA : 50|2@1+ (1,0) [0|3] "" BedienSG_hi,ZR_High
 SG_ AB_Gurtschloss_Reihe3_MI : 52|2@1+ (1,0) [0|3] "" BedienSG_hi,ZR_High
 SG_ AB_Gurtschloss_Reihe3_BF : 54|2@1+ (1,0) [0|3] "" BedienSG_hi,ZR_High
 SG_ AB_Sitzpos_Sens_FA : 56|2@1+ (1,0) [0|3] "" ZR_High
 SG_ AB_Sitzpos_Sens_BF : 58|2@1+ (1,0) [0|3] "" ZR_High
 SG_ AB_Wickelklappung_Reihe2_BF : 60|2@1+ (1,0) [0|3] "" ZR_High
 SG_ AB_Wickelklappung_Reihe2_FA : 62|2@1+ (1,0) [0|3] "" ZR_High

BO_ 1349 Airbag_04: 8 Gateway
 SG_ AB_Gurtwarn_Reihe2_FA : 20|2@1+ (1,0) [0|3] "" Vector__XXX
 SG_ AB_Gurtwarn_Reihe2_BF : 22|2@1+ (1,0) [0|3] "" Vector__XXX
 SG_ AbstWarn_MV_FAS_Fkt_Status : 24|2@1+ (1,0) [0|3] "" ZR_High
 SG_ WarnBrems_Charisma_Status : 26|2@1+ (1,0) [0|3] "" Vector__XXX
 SG_ WarnBrems_Charisma_FahrPr : 28|4@1+ (1,0) [0|15] "" Vector__XXX
 SG_ AB_Gurtwarn_Reihe2_MI : 32|2@1+ (1,0) [0|3] "" Vector__XXX
 SG_ AB_Gurtwarn_Reihe3_FA : 34|2@1+ (1,0) [0|3] "" Vector__XXX
 SG_ AB_Gurtwarn_Reihe3_MI : 36|2@1+ (1,0) [0|3] "" Vector__XXX
 SG_ AB_Gurtwarn_Reihe3_BF : 38|2@1+ (1,0) [0|3] "" Vector__XXX
 SG_ LGI_FAS_Fkt_Status : 40|2@1+ (1,0) [0|3] "" ZR_High
 SG_ PreCrash_FAS_Fkt_Status : 42|3@1+ (1,0) [0|7] "" ZR_High
 SG_ AB_SBR_hinten_verbau : 48|2@1+ (1,0) [0|3] "" Vector__XXX
 SG_ AWV_Einstellung_System_ASG : 51|1@1+ (1,0) [0|1] "" Vector__XXX
 SG_ AWV_Einstellung_Warnung_ASG : 52|3@1+ (1,0) [0|7] "" Vector__XXX
 SG_ SC_PreSense_Modus_Warnung_NV : 55|3@1+ (1,0) [0|7] "" Vector__XXX
 SG_ SC_PreSense_Modus_Warnung_MV : 58|3@1+ (1,0) [0|7] "" Vector__XXX
 SG_ SC_PreSense_Modus_System_MV : 61|1@1+ (1,0) [0|1] "" Vector__XXX
 SG_ SC_PreSense_Modus_System_NV : 62|1@1+ (1,0) [0|1] "" Vector__XXX
 SG_ SC_PreSense_Modus_System_KAS : 63|1@1+ (1,0) [0|1] "" Vector__XXX

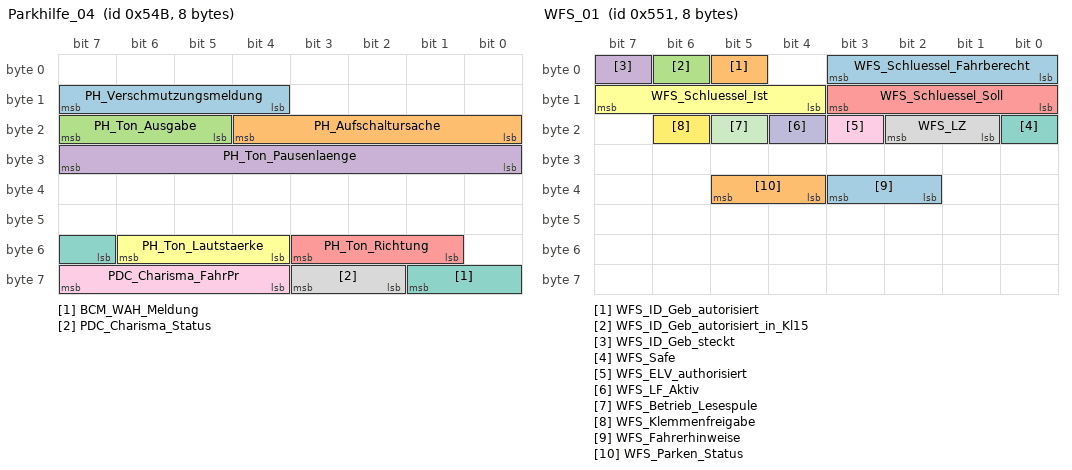
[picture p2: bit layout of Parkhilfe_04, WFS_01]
BO_ 1355 Parkhilfe_04: 8 Gateway
 SG_ PH_Verschmutzungsmeldung : 12|4@1+ (1,0) [0|15] "" Vector__XXX
 SG_ PH_Aufschaltursache : 16|5@1+ (1,0) [0|31] "" AWC
 SG_ PH_Ton_Ausgabe : 21|3@1+ (1,0) [0|7] "" Vector__XXX
 SG_ PH_Ton_Pausenlaenge : 24|8@1+ (1,0) [0|255] "" Vector__XXX
 SG_ PH_Ton_Richtung : 49|3@1+ (1,0) [0|7] "" Vector__XXX
 SG_ PH_Ton_Lautstaerke : 52|3@1+ (1,0) [0|7] "" Vector__XXX
 SG_ BCM_WAH_Meldung : 55|3@1+ (1,0) [0|7] "" Vector__XXX
 SG_ PDC_Charisma_Status : 58|2@1+ (1,0) [0|3] "" Vector__XXX
 SG_ PDC_Charisma_FahrPr : 60|4@1+ (1,0) [0|15] "" Vector__XXX

BO_ 1361 WFS_01: 8 Gateway
 SG_ WFS_Schluessel_Fahrberecht : 0|4@1+ (1,0) [0|15] "" ZR_High,ZR_LIMU,ZR_MIB_TOP_ab_Gen3,ZR_Standard
 SG_ WFS_ID_Geb_autorisiert : 5|1@1+ (1,0) [0|1] "" ZR_High
 SG_ WFS_ID_Geb_autorisiert_in_Kl15 : 6|1@1+ (1,0) [0|1] "" Vector__XXX
 SG_ WFS_ID_Geb_steckt : 7|1@1+ (1,0) [0|1] "" ZR_High
 SG_ WFS_Schluessel_Soll : 8|4@1+ (1,0) [0|15] "" ZR_High,ZR_LIMU,ZR_MIB_TOP_ab_Gen3,ZR_Standard
 SG_ WFS_Schluessel_Ist : 12|4@1+ (1,0) [0|15] "" ZR_High,ZR_LIMU,ZR_MIB_TOP_ab_Gen3,ZR_Standard
 SG_ WFS_Safe : 16|1@1+ (1,0) [0|1] "" Vector__XXX
 SG_ WFS_LZ : 17|2@1+ (1,0) [0|3] "" Vector__XXX
 SG_ WFS_ELV_authorisiert : 19|1@1+ (1,0) [0|1] "" Vector__XXX
 SG_ WFS_LF_Aktiv : 20|1@1+ (1,0) [0|1] "" Vector__XXX
 SG_ WFS_Betrieb_Lesespule : 21|1@1+ (1,0) [0|1] "" Vector__XXX
 SG_ WFS_Klemmenfreigabe : 22|1@1+ (1,0) [0|1] "" Vector__XXX
 SG_ WFS_Fahrerhinweise : 34|2@1+ (1,0) [0|3] "" Vector__XXX
 SG_ WFS_Parken_Status : 36|2@1+ (1,0) [0|3] "" Vector__XXX

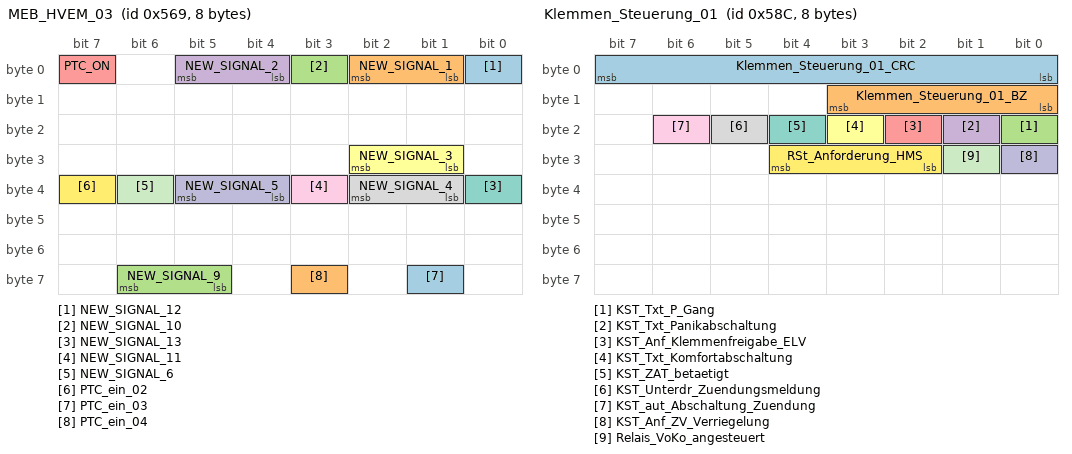
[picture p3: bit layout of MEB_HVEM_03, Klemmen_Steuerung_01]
BO_ 1385 MEB_HVEM_03: 8 XXX
 SG_ NEW_SIGNAL_12 : 0|1@0+ (1,0) [0|1] "" XXX
 SG_ NEW_SIGNAL_1 : 1|2@1+ (1,0) [0|3] "" XXX
 SG_ NEW_SIGNAL_10 : 3|1@0+ (1,0) [0|1] "" XXX
 SG_ NEW_SIGNAL_2 : 4|2@1+ (1,0) [0|3] "" XXX
 SG_ PTC_ON : 7|1@0+ (1,0) [0|1] "" XXX
 SG_ NEW_SIGNAL_3 : 25|2@1+ (1,0) [0|3] "" XXX
 SG_ NEW_SIGNAL_13 : 32|1@0+ (1,0) [0|1] "" XXX
 SG_ NEW_SIGNAL_4 : 33|2@1+ (1,0) [0|3] "" XXX
 SG_ NEW_SIGNAL_11 : 35|1@0+ (1,0) [0|1] "" XXX
 SG_ NEW_SIGNAL_5 : 36|2@1+ (1,0) [0|3] "" XXX
 SG_ NEW_SIGNAL_6 : 38|1@0+ (1,0) [0|1] "" XXX
 SG_ PTC_ein_02 : 39|1@0+ (1,0) [0|1] "" XXX
 SG_ PTC_ein_03 : 57|1@0+ (1,0) [0|1] "" XXX
 SG_ PTC_ein_04 : 59|1@0+ (1,0) [0|1] "" XXX
 SG_ NEW_SIGNAL_9 : 61|2@1+ (1,0) [0|3] "" XXX

BO_ 1411 ZV_02: 8 Gateway
 SG_ BCM_FH_Freigabe : 12|1@1+ (1,0) [0|1] "" BedienDisp_vo
 SG_ BCM_Komfortfkt_Freigabe : 13|1@1+ (1,0) [0|1] "" Vector__XXX
 SG_ BCM_HSK_Freigabe : 14|1@1+ (1,0) [0|1] "" Vector__XXX
 SG_ BCM_Verdeck_Freigabe : 15|1@1+ (1,0) [0|1] "" ZR_High
 SG_ ZV_verriegelt_intern_ist : 16|1@1+ (1,0) [0|1] "" DDA,OTA_FC,ZR_High
 SG_ ZV_verriegelt_extern_ist : 17|1@1+ (1,0) [0|1] "" DDA,OTA_FC,ZR_High
 SG_ ZV_verriegelt_intern_soll : 18|1@1+ (1,0) [0|1] "" ZR_High
 SG_ ZV_verriegelt_extern_soll : 19|1@1+ (1,0) [0|1] "" OTA_FC,ZR_High,ZR_LIMU,ZR_MIB_TOP_ab_Gen3,ZR_Standard
 SG_ ZV_gesafet_extern_ist : 20|1@1+ (1,0) [0|1] "" ZR_High
 SG_ ZV_gesafet_extern_soll : 21|1@1+ (1,0) [0|1] "" ZR_High,ZR_LIMU,ZR_MIB_TOP_ab_Gen3
 SG_ ZV_Einzeltuerentriegelung : 22|1@1+ (1,0) [0|1] "" Vector__XXX
 SG_ ZV_Heckeinzelentriegelung : 23|1@1+ (1,0) [0|1] "" Vector__XXX
 SG_ ZV_FT_offen : 24|1@1+ (1,0) [0|1] "" DDA,OTA_FC,ZR_High,ZR_LIMU,ZR_MIB_TOP_ab_Gen3,ZR_Standard
 SG_ ZV_BT_offen : 25|1@1+ (1,0) [0|1] "" DDA,OTA_FC,ZR_High,ZR_LIMU,ZR_MIB_TOP_ab_Gen3,ZR_Standard
 SG_ ZV_HFS_offen : 26|1@1+ (1,0) [0|1] "" DDA,OTA_FC,ZR_High,ZR_LIMU,ZR_MIB_TOP_ab_Gen3,ZR_Standard
 SG_ ZV_HBFS_offen : 27|1@1+ (1,0) [0|1] "" DDA,OTA_FC,ZR_High,ZR_LIMU,ZR_MIB_TOP_ab_Gen3,ZR_Standard
 SG_ ZV_HD_offen : 28|1@1+ (1,0) [0|1] "" DDA,OTA_FC,ZR_High,ZR_LIMU,ZR_MIB_TOP_ab_Gen3,ZR_Standard
 SG_ ZV_HS_offen : 29|1@1+ (1,0) [0|1] "" OTA_FC,ZR_High
 SG_ IRUE_aktiv : 30|1@1+ (1,0) [0|1] "" ZR_High
 SG_ DWA_aktiv : 31|1@1+ (1,0) [0|1] "" ZR_High
 SG_ HD_Hauptraste : 32|1@1+ (1,0) [0|1] "" OTA_FC,ZR_High
 SG_ HD_Vorraste : 33|1@1+ (1,0) [0|1] "" OTA_FC,ZR_High
 SG_ FFB_CarFinder : 38|1@1+ (1,0) [0|1] "" Vector__XXX
 SG_ FFB_Komfortoeffnen : 39|1@1+ (1,0) [0|1] "" Vector__XXX
 SG_ FFB_Komfortschliessen : 40|1@1+ (1,0) [0|1] "" Vector__XXX
 SG_ ZV_Schluessel_Zugang : 42|4@1+ (1,0) [0|15] "" ZR_High
 SG_ ZV_SafeFunktion_aktiv : 46|1@1+ (1,0) [0|1] "" ZR_High
 SG_ FBS_Warn_Schluessel_Batt : 47|1@1+ (1,0) [0|1] "" ZR_High
 SG_ ZV_Oeffnungsmodus : 48|2@1+ (1,0) [0|3] "" Vector__XXX
 SG_ HFS_verriegelt : 50|1@1+ (1,0) [0|1] "" OTA_FC
 SG_ HFS_gesafet : 51|1@1+ (1,0) [0|1] "" Vector__XXX
 SG_ HBFS_verriegelt : 52|1@1+ (1,0) [0|1] "" OTA_FC
 SG_ HBFS_gesafet : 53|1@1+ (1,0) [0|1] "" Vector__XXX
 SG_ ZV_ist_Zustand_verfuegbar : 54|1@1+ (1,0) [0|1] "" OTA_FC,ZR_High
 SG_ IRUE_Taster_Fkts_LED : 55|1@1+ (1,0) [0|1] "" ZR_High
 SG_ ZV_Tankklappe_offen : 56|1@1+ (1,0) [0|1] "" ZR_High
 SG_ ZV_Rollo_auf : 57|1@1+ (1,0) [0|1] "" ZR_High
 SG_ ZV_Rollo_zu : 58|1@1+ (1,0) [0|1] "" ZR_High
 SG_ ZV_SAD_auf : 59|1@1+ (1,0) [0|1] "" ZR_High
 SG_ ZV_SAD_zu : 60|1@1+ (1,0) [0|1] "" ZR_High
 SG_ BCM_Tankklappensteller_Fehler : 61|1@1+ (1,0) [0|1] "" ZR_High
 SG_ ZV_verriegelt_soll : 62|2@1+ (1,0) [0|3] "" Vector__XXX

BO_ 1413 Systeminfo_01: 8 Gateway
 SG_ SI_Sammel_SG_Fehler : 0|6@1+ (1,0) [0|60] "" ZR_High,ZR_LIMU,ZR_MIB_TOP_ab_Gen3,ZR_Standard
 SG_ SI_Diagnose_Aktiv : 7|1@1+ (1,0) [0|1] "" ZR_High,ZR_LIMU,ZR_MIB_TOP_ab_Gen3,ZR_Standard
 SG_ SI_QRS_Mode : 8|1@1+ (1,0) [0|1] "" BedienSG_hi,ZR_High,ZR_LIMU,ZR_MIB_TOP_ab_Gen3,ZR_Standard
 SG_ SI_T_Mode : 9|1@1+ (1,0) [0|1] "" BedienDisp_vo,BedienSG_hi,DDA,ZR_High,ZR_LIMU,ZR_MIB_TOP_ab_Gen3,ZR_Standard
 SG_ SI_NWDF : 10|1@1+ (1,0) [0|1] "" BedienDisp_vo,BedienSG_hi,DDA,ZR_High,ZR_LIMU,ZR_MIB_TOP_ab_Gen3,ZR_Standard
 SG_ SI_NWDF_gueltig : 11|1@1+ (1,0) [0|1] "" BedienDisp_vo,BedienSG_hi,DDA,ZR_High,ZR_LIMU,ZR_MIB_TOP_ab_Gen3,ZR_Standard
 SG_ SI_Sammelfehler : 12|1@1+ (1,0) [0|1] "" ZR_High,ZR_LIMU,ZR_MIB_TOP_ab_Gen3,ZR_Standard
 SG_ GW_KD_Fehler : 13|1@1+ (1,0) [0|1] "" ZR_High,ZR_MIB_TOP_ab_Gen3,ZR_Standard
 SG_ SI_T_Schutz : 14|1@1+ (1,0) [0|1] "" BedienSG_hi,ZR_High,ZR_LIMU,ZR_MIB_TOP_ab_Gen3,ZR_Standard
 SG_ SI_BUS_01 : 16|1@1+ (1,0) [0|1] "" ZR_High,ZR_LIMU,ZR_MIB_TOP_ab_Gen3,ZR_Standard
 SG_ SI_BUS_02 : 17|1@1+ (1,0) [0|1] "" ZR_High,ZR_LIMU,ZR_MIB_TOP_ab_Gen3,ZR_Standard
 SG_ SI_BUS_03 : 18|1@1+ (1,0) [0|1] "" BedienSG_hi,DDA,ZR_High,ZR_LIMU,ZR_MIB_TOP_ab_Gen3,ZR_Standard
 SG_ SI_BUS_04 : 19|1@1+ (1,0) [0|1] "" BedienSG_hi,ZR_High,ZR_LIMU,ZR_MIB_TOP_ab_Gen3,ZR_Standard
 SG_ SI_BUS_05 : 20|1@1+ (1,0) [0|1] "" ZR_High,ZR_LIMU,ZR_MIB_TOP_ab_Gen3,ZR_Standard
 SG_ SI_BUS_06 : 21|1@1+ (1,0) [0|1] "" ZR_High,ZR_LIMU,ZR_MIB_TOP_ab_Gen3,ZR_Standard
 SG_ SI_BUS_07 : 22|1@1+ (1,0) [0|1] "" ZR_High,ZR_LIMU,ZR_MIB_TOP_ab_Gen3,ZR_Standard
 SG_ SI_BUS_08 : 23|1@1+ (1,0) [0|1] "" ZR_High,ZR_LIMU,ZR_MIB_TOP_ab_Gen3,ZR_Standard
 SG_ SI_BUS_09 : 24|1@1+ (1,0) [0|1] "" ZR_High,ZR_LIMU,ZR_MIB_TOP_ab_Gen3,ZR_Standard
 SG_ SI_BUS_10 : 25|1@1+ (1,0) [0|1] "" BedienSG_hi,DDA,ZR_High,ZR_LIMU,ZR_MIB_TOP_ab_Gen3,ZR_Standard
 SG_ SI_BUS_11 : 26|1@1+ (1,0) [0|1] "" ZR_High,ZR_LIMU,ZR_MIB_TOP_ab_Gen3,ZR_Standard
 SG_ SI_BUS_12 : 27|1@1+ (1,0) [0|1] "" DDA,ZR_High,ZR_LIMU,ZR_MIB_TOP_ab_Gen3,ZR_Standard
 SG_ SI_BUS_13 : 28|1@1+ (1,0) [0|1] "" ZR_High,ZR_LIMU,ZR_MIB_TOP_ab_Gen3,ZR_Standard
 SG_ SI_BUS_14 : 29|1@1+ (1,0) [0|1] "" ZR_High,ZR_LIMU,ZR_MIB_TOP_ab_Gen3,ZR_Standard
 SG_ SI_BUS_15 : 30|1@1+ (1,0) [0|1] "" ZR_High,ZR_LIMU,ZR_MIB_TOP_ab_Gen3,ZR_Standard
 SG_ SI_Bus_Identifikation : 32|8@1+ (1,0) [0|255] "" OTA_FC,ZR_High,ZR_LIMU,ZR_MIB_TOP_ab_Gen3,ZR_Standard
 SG_ SI_CAB : 40|24@1+ (1,0) [0|16777215] "" BedienSG_hi,OTA_FC,ZR_High,ZR_LIMU,ZR_MIB_TOP_ab_Gen3,ZR_Standard

BO_ 1420 Klemmen_Steuerung_01: 8 Gateway
 SG_ Klemmen_Steuerung_01_CRC : 0|8@1+ (1,0) [0|255] "" Vector__XXX
 SG_ Klemmen_Steuerung_01_BZ : 8|4@1+ (1,0) [0|15] "" Vector__XXX
 SG_ KST_Txt_P_Gang : 16|1@1+ (1,0) [0|1] "" Vector__XXX
 SG_ KST_Txt_Panikabschaltung : 17|1@1+ (1,0) [0|1] "" Vector__XXX
 SG_ KST_Anf_Klemmenfreigabe_ELV : 18|1@1+ (1,0) [0|1] "" Vector__XXX
 SG_ KST_Txt_Komfortabschaltung : 19|1@1+ (1,0) [0|1] "" Vector__XXX
 SG_ KST_ZAT_betaetigt : 20|1@1+ (1,0) [0|1] "" ZR_High
 SG_ KST_Unterdr_Zuendungsmeldung : 21|1@1+ (1,0) [0|1] "" Vector__XXX
 SG_ KST_aut_Abschaltung_Zuendung : 22|1@1+ (1,0) [0|1] "" Vector__XXX
 SG_ KST_Anf_ZV_Verriegelung : 24|1@1+ (1,0) [0|1] "" Vector__XXX
 SG_ Relais_VoKo_angesteuert : 25|1@1+ (1,0) [0|1] "" Vector__XXX
 SG_ RSt_Anforderung_HMS : 26|3@1+ (1,0) [0|7] "" Vector__XXX

BO_ 1426 Kessy_04: 8 XXX

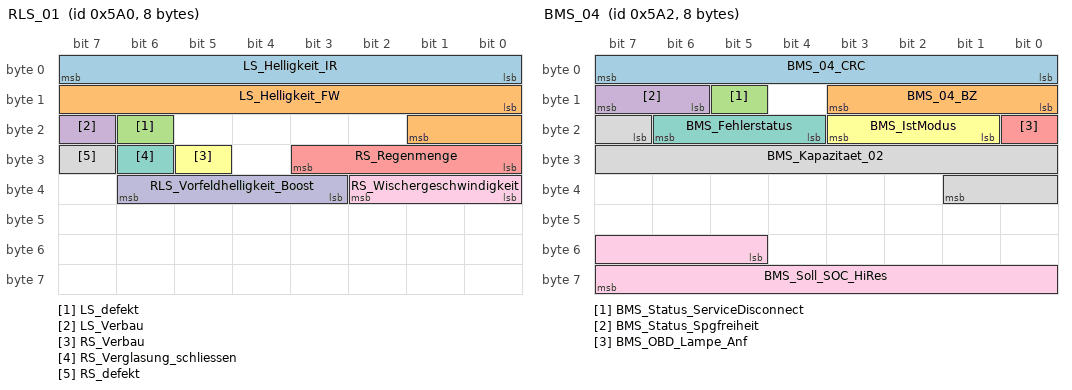
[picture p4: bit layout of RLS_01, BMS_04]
BO_ 1440 RLS_01: 8 Gateway
 SG_ LS_Helligkeit_IR : 0|8@1+ (400,0) [0|101200] "Unit_Lux" ZR_High
 SG_ LS_Helligkeit_FW : 8|10@1+ (6,0) [0|6126] "Unit_Lux" ZR_High
 SG_ LS_defekt : 22|1@1+ (1,0) [0|1] "" ZR_High
 SG_ LS_Verbau : 23|1@1+ (1,0) [0|1] "" ZR_High
 SG_ RS_Regenmenge : 24|4@1+ (10,0) [0|100] "Unit_PerCent" OTA_FC,ZR_High
 SG_ RS_Verbau : 29|1@1+ (1,0) [0|1] "" ZR_High
 SG_ RS_Verglasung_schliessen : 30|1@1+ (1,0) [0|1] "" ZR_High
 SG_ RS_defekt : 31|1@1+ (1,0) [0|1] "" ZR_High
 SG_ RS_Wischergeschwindigkeit : 32|3@1+ (1,0) [0|7] "" OTA_FC,ZR_High
 SG_ RLS_Vorfeldhelligkeit_Boost : 35|4@1+ (1,0) [0|15] "" ZR_High

BO_ 1442 BMS_04: 8 BMC_MLBevo
 SG_ BMS_04_CRC : 0|8@1+ (1,0) [0|255] "" Gateway,Gateway_PAG,Sub_Gateway
 SG_ BMS_04_BZ : 8|4@1+ (1,0) [0|15] "" Gateway,Gateway_PAG,Sub_Gateway
 SG_ BMS_Status_ServiceDisconnect : 13|1@1+ (1,0) [0|1] "" DCDC_800V_PAG,DCDC_HV,Gateway,Gateway_PAG,Sub_Gateway
 SG_ BMS_Status_Spgfreiheit : 14|2@1+ (1,0) [0|3] "" Gateway,Gateway_PAG,Sub_Gateway
 SG_ BMS_OBD_Lampe_Anf : 16|1@1+ (1,0) [0|1] "" Gateway,Gateway_PAG,Sub_Gateway
 SG_ BMS_IstModus : 17|3@1+ (1,0) [0|7] "" AWC,Gateway,Gateway_PAG,Ladegeraet_Konzern,LE1,LE2,LE2_3_MLBevo_LB,Sub_Gateway,TME
 SG_ BMS_Fehlerstatus : 20|3@1+ (1,0) [0|7] "" AWC,DCDC_800V_PAG,DCDC_HV,Gateway,Gateway_PAG,Ladegeraet_Konzern,Sub_Gateway
 SG_ BMS_Kapazitaet_02 : 23|11@1+ (0.2,0) [0|409.2] "Unit_AmperHour" Gateway,Gateway_PAG,Ladegeraet_Konzern,Sub_Gateway
 SG_ BMS_Soll_SOC_HiRes : 53|11@1+ (0.05,0) [0|100] "Unit_PerCent" Gateway,Gateway_PAG,Sub_Gateway

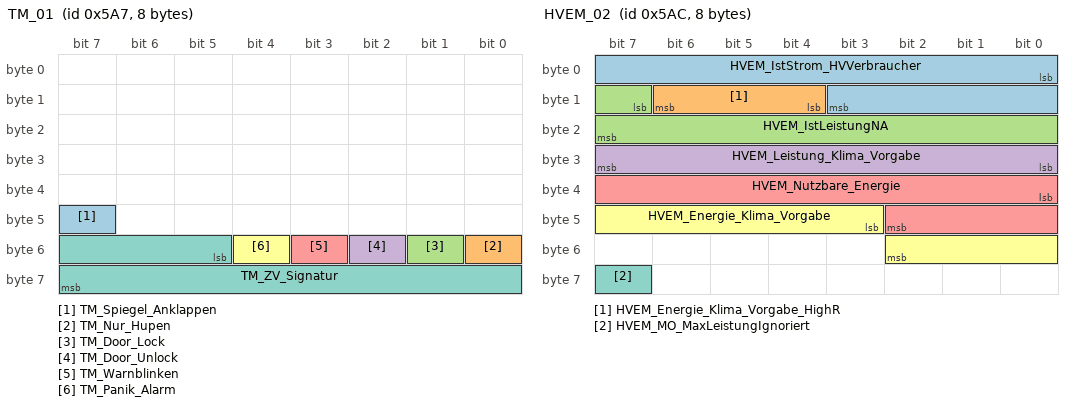
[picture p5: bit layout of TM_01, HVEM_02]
BO_ 1447 TM_01: 8 Gateway
 SG_ TM_Spiegel_Anklappen : 47|1@1+ (1,0) [0|1] "" ZR_High
 SG_ TM_Nur_Hupen : 48|1@1+ (1,0) [0|1] "" ZR_High
 SG_ TM_Door_Lock : 49|1@1+ (1,0) [0|1] "" Vector__XXX
 SG_ TM_Door_Unlock : 50|1@1+ (1,0) [0|1] "" Vector__XXX
 SG_ TM_Warnblinken : 51|1@1+ (1,0) [0|1] "" ZR_High
 SG_ TM_Panik_Alarm : 52|1@1+ (1,0) [0|1] "" ZR_High
 SG_ TM_ZV_Signatur : 53|11@1+ (1,0) [1|2047] "Unit_None" Vector__XXX

BO_ 1452 HVEM_02: 8 Gateway
 SG_ HVEM_IstStrom_HVVerbraucher : 0|12@1+ (0.1,-204.7) [-204.7|204.6] "Unit_Amper" Vector__XXX
 SG_ HVEM_Energie_Klima_Vorgabe_HighR : 12|3@1+ (10,0) [0|50] "Unit_WattHour" TME
 SG_ HVEM_IstLeistungNA : 15|9@1+ (50,0) [0|25450] "Unit_Watt" Vector__XXX
 SG_ HVEM_Leistung_Klima_Vorgabe : 24|8@1+ (50,0) [0|12650] "Unit_Watt" TME
 SG_ HVEM_Nutzbare_Energie : 32|11@1+ (50,0) [0|102200] "Unit_WattHour" Ladegeraet_Konzern
 SG_ HVEM_Energie_Klima_Vorgabe : 43|8@1+ (50,0) [0|12650] "Unit_WattHour" TME
 SG_ HVEM_MO_MaxLeistungIgnoriert : 63|1@1+ (1,0) [0|1] "" Vector__XXX

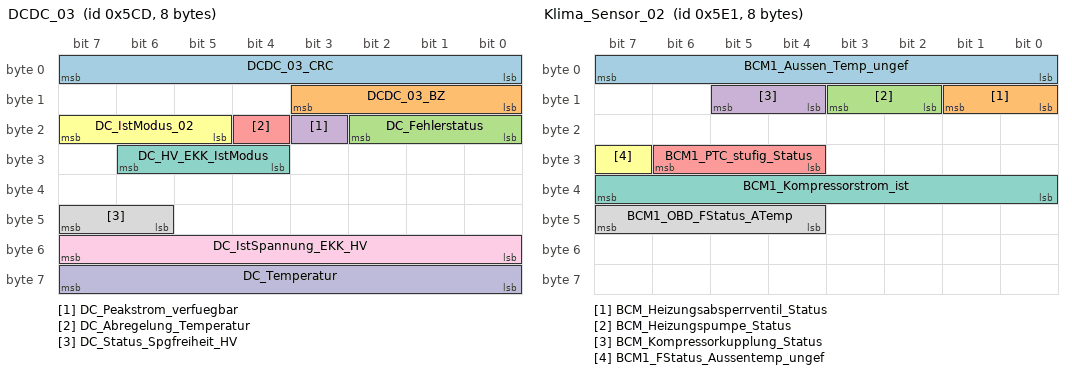
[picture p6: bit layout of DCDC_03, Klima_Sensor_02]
BO_ 1485 DCDC_03: 8 DCDC_800V_PAG
 SG_ DCDC_03_CRC : 0|8@1+ (1,0) [0|255] "" Gateway,Gateway_PAG,Sub_Gateway
 SG_ DCDC_03_BZ : 8|4@1+ (1,0) [0|15] "" Gateway,Gateway_PAG,Sub_Gateway
 SG_ DC_Fehlerstatus : 16|3@1+ (1,0) [0|7] "" Gateway,Gateway_PAG,Sub_Gateway
 SG_ DC_Peakstrom_verfuegbar : 19|1@1+ (1,0) [0|1] "" Gateway,Gateway_PAG,Sub_Gateway
 SG_ DC_Abregelung_Temperatur : 20|1@1+ (1,0) [0|1] "" Gateway_PAG,Sub_Gateway,TME
 SG_ DC_IstModus_02 : 21|3@1+ (1,0) [0|7] "" DCDC_HV_02,Gateway,Gateway_PAG,Ladegeraet_Konzern,Sub_Gateway,TME
 SG_ DC_HV_EKK_IstModus : 28|3@1+ (1,0) [0|7] "" Gateway,Gateway_PAG,Sub_Gateway,TME
 SG_ DC_Status_Spgfreiheit_HV : 46|2@1+ (1,0) [0|3] "" Gateway,Gateway_PAG,Sub_Gateway
 SG_ DC_IstSpannung_EKK_HV : 48|8@1+ (2,0) [0|508] "Unit_Volt" Gateway,Gateway_PAG,Sub_Gateway
 SG_ DC_Temperatur : 56|8@1+ (1,-40) [-40|213] "Unit_DegreCelsi" Gateway,Gateway_PAG,Sub_Gateway,TME

BO_ 1505 Klima_Sensor_02: 8 Gateway
 SG_ BCM1_Aussen_Temp_ungef : 0|8@1+ (0.5,-50) [-50|76] "Unit_DegreCelsi" BMC_MLBevo,BMS_NV,FCU_MLBevo_FCEV,Ladegeraet_Konzern,TME
 SG_ BCM_Heizungsabsperrventil_Status : 8|2@1+ (1,0) [0|3] "" Vector__XXX
 SG_ BCM_Heizungspumpe_Status : 10|2@1+ (1,0) [0|3] "" Vector__XXX
 SG_ BCM_Kompressorkupplung_Status : 12|2@1+ (1,0) [0|3] "" Vector__XXX
 SG_ BCM1_PTC_stufig_Status : 28|3@1+ (1,0) [0|7] "" Vector__XXX
 SG_ BCM1_FStatus_Aussentemp_ungef : 31|1@1+ (1,0) [0|1] "" TME
 SG_ BCM1_Kompressorstrom_ist : 32|8@1+ (4,0) [0|1000] "Unit_MilliAmper" Vector__XXX
 SG_ BCM1_OBD_FStatus_ATemp : 44|4@1+ (1,0) [0|15] "" BMC_MLBevo,Ladegeraet_Konzern,TME

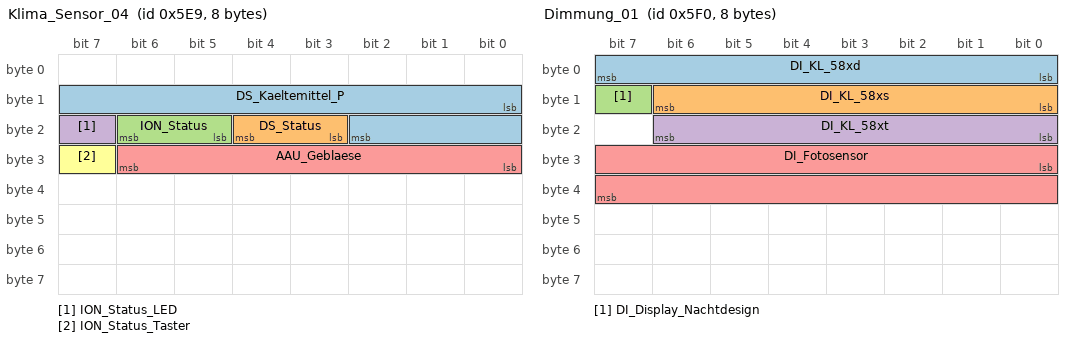
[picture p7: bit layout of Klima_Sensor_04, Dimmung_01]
BO_ 1513 Klima_Sensor_04: 8 Gateway
 SG_ DS_Kaeltemittel_P : 8|11@1+ (0.0161,0) [0|32.9245] "Unit_Bar" TME
 SG_ DS_Status : 19|2@1+ (1,0) [0|3] "" TME
 SG_ ION_Status : 21|2@1+ (1,0) [0|3] "" Vector__XXX
 SG_ ION_Status_LED : 23|1@1+ (1,0) [0|1] "" Vector__XXX
 SG_ AAU_Geblaese : 24|7@1+ (1,0) [0|100] "Unit_PerCent" Vector__XXX
 SG_ ION_Status_Taster : 31|1@1+ (1,0) [0|1] "" Vector__XXX

BO_ 1520 Dimmung_01: 8 Gateway_MQB
 SG_ DI_KL_58xd : 0|8@1+ (1,0) [0|253] "" Airbag_MQB
 SG_ DI_KL_58xs : 8|7@1+ (1,0) [0|100] "Unit_PerCent" Vector__XXX
 SG_ DI_Display_Nachtdesign : 15|1@1+ (1,0) [0|1] "" Vector__XXX
 SG_ DI_KL_58xt : 16|7@1+ (1,0) [0|100] "Unit_PerCent" Vector__XXX
 SG_ DI_Fotosensor : 24|16@1+ (1,0) [0|65535] "" Vector__XXX

BO_ 1524 Innenlicht_11: 8 Gateway
 SG_ IL_Dimmung_V_Tuerkontur : 0|8@1+ (1,0) [0|100] "Unit_PerCent" ZR_High
 SG_ IL_Dimmung_H_Tuerkontur : 8|8@1+ (1,0) [0|100] "Unit_PerCent" ZR_High
 SG_ IL_Dimmung_Tuerinnengriff : 16|8@1+ (1,0) [0|100] "Unit_PerCent" ZR_High
 SG_ IL_Dimmung_Umfeldbel : 24|8@1+ (1,0) [0|100] "Unit_PerCent" ZR_High
 SG_ IL_Bel_FS_Ausstieg : 32|1@1+ (1,0) [0|1] "" ZR_High
 SG_ IL_Bel_BFS_Ausstieg : 33|1@1+ (1,0) [0|1] "" ZR_High
 SG_ IL_Bel_HFS_Ausstieg : 34|1@1+ (1,0) [0|1] "" ZR_High
 SG_ IL_Bel_HBFS_Ausstieg : 35|1@1+ (1,0) [0|1] "" ZR_High
 SG_ BCM1_Innenlicht_gedimmt_V : 36|1@1+ (1,0) [0|1] "" ZR_High
 SG_ BCM1_Innenlicht_gedimmt_H : 37|1@1+ (1,0) [0|1] "" ZR_High
 SG_ IL_Innenlicht_aktiv : 38|1@1+ (1,0) [0|1] "" ZR_High
 SG_ IL_Klemme_30G_aktiv : 39|1@1+ (1,0) [0|1] "" Vector__XXX
 SG_ BCM1_DI_Rampe_Innenlicht : 40|1@1+ (1,0) [0|1] "" ZR_High
 SG_ BCM1_DI_Rampe_Leselicht : 41|1@1+ (1,0) [0|1] "" ZR_High
 SG_ BCM1_Innenlicht_H : 42|1@1+ (1,0) [0|1] "" ZR_High
 SG_ BCM1_Innenlicht_V : 43|1@1+ (1,0) [0|1] "" ZR_High
 SG_ BCM1_Leselicht_Anf_hl : 44|1@1+ (1,0) [0|1] "" ZR_High
 SG_ BCM1_Leselicht_Anf_hr : 45|1@1+ (1,0) [0|1] "" ZR_High
 SG_ BCM1_Leselicht_Anf_vl : 46|1@1+ (1,0) [0|1] "" ZR_High
 SG_ BCM1_Leselicht_Anf_vr : 47|1@1+ (1,0) [0|1] "" ZR_High
 SG_ BCM1_Leuchten_Aus : 48|1@1+ (1,0) [0|1] "" ZR_High
 SG_ AMB_Charisma_FahrPr : 49|4@1+ (1,0) [0|15] "" Vector__XXX
 SG_ AMB_Charisma_Status : 53|2@1+ (1,0) [0|3] "" Vector__XXX
 SG_ IL_Dimmung_Lautspr : 56|8@1+ (1,0) [0|100] "Unit_PerCent" ZR_High

BO_ 1600 Motor_07: 8 Motor_Diesel_MQB
 SG_ MO_QBit_Ansaugluft_Temp : 0|1@1+ (1,0) [0|1] "" Gateway_MQB
 SG_ MO_QBit_Oel_Temp : 1|1@1+ (1,0) [0|1] "" Gateway_MQB,Getriebe_DQ_Hybrid_MQB,Getriebe_DQ_MQB
 SG_ MO_QBit_Kuehlmittel_Temp : 2|1@1+ (1,0) [0|1] "" Gateway_MQB,Getriebe_DQ_Hybrid_MQB,Getriebe_DQ_MQB,LEH_MQB
 SG_ MO_Stellgliedtest_Soundaktuator : 3|1@1+ (1,0) [0|1] "" Gateway_MQB
 SG_ MO_HYB_Fehler_HV_Netz : 4|1@1+ (1,0) [0|1] "" Gateway_MQB
 SG_ MO_aktives_Getriebeheizen : 5|1@1+ (1,0) [0|1] "" Gateway_MQB,Getriebe_DQ_Hybrid_MQB,Getriebe_DQ_MQB
 SG_ MO_Absperrventil_oeffnen : 6|2@1+ (1,0) [0|3] "" Gateway_MQB
 SG_ MO_Ansaugluft_Temp : 8|8@1+ (0.75,-48) [-48|141.75] "Unit_DegreCelsi" Gateway_MQB
 SG_ MO_Oel_Temp : 16|8@1+ (1,-60) [-60|192] "Unit_DegreCelsi" Gateway_MQB,Getriebe_DQ_Hybrid_MQB,Getriebe_DQ_MQB
 SG_ MO_Kuehlmittel_Temp : 24|8@1+ (0.75,-48) [-48|141.75] "Unit_DegreCelsi" Gateway_MQB,Getriebe_DQ_Hybrid_MQB,Getriebe_DQ_MQB,LEH_MQB
 SG_ MO_Hoeheninfo : 32|8@1+ (0.00781,0) [0|1.98374] "" Gateway_MQB,Getriebe_DQ_Hybrid_MQB,Getriebe_DQ_MQB
 SG_ MO_Kennfeldk : 40|1@1+ (1,0) [0|1] "" Gateway_MQB
 SG_ MO_Versionsinfo : 41|6@1+ (1,0) [0|63] "" Gateway_MQB
 SG_ MO_Getriebe_kuehlen : 47|1@1+ (1,0) [0|1] "" Gateway_MQB,Getriebe_DQ_Hybrid_MQB,Getriebe_DQ_MQB
 SG_ MO_Mom_Traegheit_02 : 48|5@1+ (0.01,0) [0|0.31] "Unit_KiloGramMeterSquar" Gateway_MQB,Getriebe_DQ_Hybrid_MQB,Getriebe_DQ_MQB
 SG_ MO_Heizungspumpenansteuerung : 53|4@1+ (10,0) [0|100] "Unit_PerCent" Gateway_MQB
 SG_ MO_SpannungsAnf : 57|1@1+ (1,0) [0|1] "" Gateway_MQB
 SG_ MO_Nachlaufzeit_Heizungspumpe : 58|6@1+ (15,0) [0|945] "Unit_Secon" Gateway_MQB

BO_ 1601 Motor_Code_01: 8 Motor_Diesel_MQB
 SG_ Motor_Code_01_CRC : 0|8@1+ (1,0) [0|255] "" Gateway_MQB
 SG_ Motor_Code_01_BZ : 8|4@1+ (1,0) [0|15] "" Gateway_MQB
 SG_ MO_Faktor_Momente_02 : 12|2@1+ (1,0) [0|3] "" Gateway_MQB,Getriebe_DQ_Hybrid_MQB,Getriebe_DQ_MQB
 SG_ MO_Hybridfahrzeug : 14|2@1+ (1,0) [0|3] "" Gateway_MQB
 SG_ MO_Code : 16|8@1+ (1,0) [0|255] "" Gateway_MQB,SAK_MQB
 SG_ MO_Getriebe_Code : 24|6@1+ (1,0) [0|63] "" Gateway_MQB
 SG_ MO_StartStopp_Codiert : 30|1@1+ (1,0) [0|1] "" Gateway_MQB
 SG_ MO_Anzahl_Zyl : 32|4@1+ (1,0) [0|15] "" Gateway_MQB
 SG_ MO_Kraftstoffart : 36|4@1+ (1,0) [0|15] "" Gateway_MQB,Getriebe_DQ_Hybrid_MQB,Getriebe_DQ_MQB
 SG_ MO_Hubraum : 40|7@1+ (0.1,0) [0|12.7] "Unit_Liter" Gateway_MQB
 SG_ MO_Ansaugsystem : 47|1@1+ (1,0) [0|1] "" Gateway_MQB
 SG_ MO_Leistung : 48|9@1+ (1,0) [0|511] "Unit_KiloWatt" Gateway_MQB
 SG_ MO_Abgastyp_EOBD : 57|1@1+ (1,0) [0|1] "" BMS_MQB,Gateway_MQB,LEH_MQB
 SG_ MO_Abgastyp_OBD : 58|1@1+ (1,0) [0|1] "" BMS_MQB,Gateway_MQB,LEH_MQB
 SG_ MO_DPF_verbaut : 59|1@1+ (1,0) [0|1] "" Gateway_MQB
 SG_ TSK_Codierung : 60|3@1+ (1,0) [0|7] "" Gateway_MQB,Getriebe_DQ_Hybrid_MQB,Getriebe_DQ_MQB
 SG_ MO_Einspritzart : 63|1@1+ (1,0) [0|1] "" Gateway_MQB

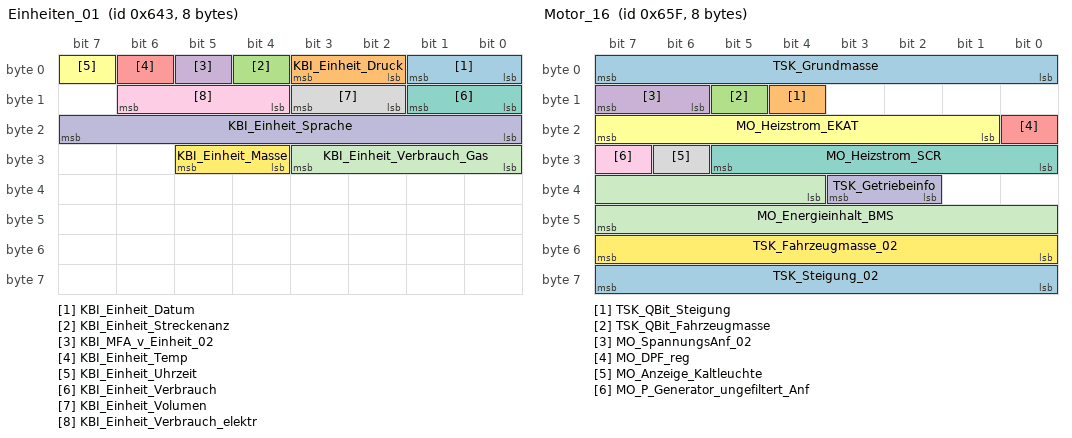
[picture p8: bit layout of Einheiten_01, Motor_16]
BO_ 1603 Einheiten_01: 8 Gateway
 SG_ KBI_Einheit_Datum : 0|2@1+ (1,0) [0|3] "" Vector__XXX
 SG_ KBI_Einheit_Druck : 2|2@1+ (1,0) [0|3] "" Vector__XXX
 SG_ KBI_Einheit_Streckenanz : 4|1@1+ (1,0) [0|1] "" Ladegeraet_Konzern
 SG_ KBI_MFA_v_Einheit_02 : 5|1@1+ (1,0) [0|1] "" Vector__XXX
 SG_ KBI_Einheit_Temp : 6|1@1+ (1,0) [0|1] "" TME
 SG_ KBI_Einheit_Uhrzeit : 7|1@1+ (1,0) [0|1] "" Ladegeraet_Konzern
 SG_ KBI_Einheit_Verbrauch : 8|2@1+ (1,0) [0|3] "" Vector__XXX
 SG_ KBI_Einheit_Volumen : 10|2@1+ (1,0) [0|3] "" Vector__XXX
 SG_ KBI_Einheit_Verbrauch_elektr : 12|3@1+ (1,0) [0|7] "" Vector__XXX
 SG_ KBI_Einheit_Sprache : 16|8@1+ (1,0) [0|255] "" Vector__XXX
 SG_ KBI_Einheit_Verbrauch_Gas : 24|4@1+ (1,0) [0|15] "" Vector__XXX
 SG_ KBI_Einheit_Masse : 28|2@1+ (1,0) [0|3] "" Vector__XXX

BO_ 1622 ELV_01: 8 Gateway
 SG_ ELV_01_CRC : 0|8@1+ (1,0) [0|255] "" Vector__XXX
 SG_ ELV_01_BZ : 8|4@1+ (1,0) [0|15] "" Vector__XXX
 SG_ ELV_Anf_Klemme_S : 12|1@1+ (1,0) [0|1] "" Vector__XXX
 SG_ ELV_Anf_Klemme_15 : 13|1@1+ (1,0) [0|1] "" Vector__XXX
 SG_ ELV_Anf_Klemme_50 : 14|1@1+ (1,0) [0|1] "" Vector__XXX
 SG_ ELV_01_Sendestatus : 15|1@1+ (1,0) [0|1] "" Vector__XXX
 SG_ ELV_Verriegelt : 16|1@1+ (1,0) [0|1] "" ZR_High
 SG_ ELV_Entriegelt : 17|1@1+ (1,0) [0|1] "" ZR_High
 SG_ ELV_ZAT_betaetigt : 18|1@1+ (1,0) [0|1] "" Vector__XXX
 SG_ ELV_Lebenszustand : 19|1@1+ (1,0) [0|1] "" Vector__XXX
 SG_ ELV_Anlernmodus : 20|1@1+ (1,0) [0|1] "" Vector__XXX
 SG_ ELV_Klemmenfreigabe : 22|1@1+ (1,0) [0|1] "" Vector__XXX
 SG_ ELV_Abbruch_Anf_Klemmenfreigabe : 23|1@1+ (1,0) [0|1] "" Vector__XXX
 SG_ ELV_LED_Rot : 24|1@1+ (1,0) [0|1] "" ZR_High
 SG_ ELV_LED_Gelb : 25|1@1+ (1,0) [0|1] "" Vector__XXX
 SG_ ELV_Txt_Panikabschaltung : 27|1@1+ (1,0) [0|1] "" Vector__XXX
 SG_ ELV_Txt_Lkg_Bewegen : 28|1@1+ (1,0) [0|1] "" ZR_High
 SG_ ELV_Txt_Werkstatt : 29|1@1+ (1,0) [0|1] "" ZR_High
 SG_ ELV_Txt_Defekt : 30|1@1+ (1,0) [0|1] "" ZR_High
 SG_ ELV_Txt_P_Gang : 31|1@1+ (1,0) [0|1] "" Vector__XXX
 SG_ ELV_Txt_PN_Gang : 32|1@1+ (1,0) [0|1] "" Vector__XXX
 SG_ ELV_Txt_Kupplung : 33|1@1+ (1,0) [0|1] "" Vector__XXX
 SG_ ELV_Txt_Bremse : 34|1@1+ (1,0) [0|1] "" Vector__XXX
 SG_ ELV_P_verriegelt : 35|1@1+ (1,0) [0|1] "" Vector__XXX

BO_ 1624 Licht_vorne_01: 8 Gateway
 SG_ Licht_Vorne_01_CRC : 0|8@1+ (1,0) [0|255] "" Vector__XXX
 SG_ Licht_Vorne_01_BZ : 8|4@1+ (1,0) [0|15] "" Vector__XXX
 SG_ LV_Standlicht_Anzeige : 12|1@1+ (1,0) [0|1] "" OTA_FC,ZR_High
 SG_ LV_Abblendlicht_Anzeige : 13|1@1+ (1,0) [0|1] "" OTA_FC,ZR_High
 SG_ LV_Fernlicht_Anzeige : 14|1@1+ (1,0) [0|1] "" OTA_FC,ZR_High
 SG_ LV_Nebellicht_Anzeige : 15|1@1+ (1,0) [0|1] "" OTA_FC,ZR_High
 SG_ LV_Nebelschlusslicht_Anzeige : 16|1@1+ (1,0) [0|1] "" OTA_FC,ZR_High
 SG_ LV_Tagfahrlicht_Anzeige : 17|1@1+ (1,0) [0|1] "" BedienSG_hi,OTA_FC,ZR_High
 SG_ LV_AFL_aktiv_Anzeige : 18|1@1+ (1,0) [0|1] "" BedienSG_hi,OTA_FC,ZR_High
 SG_ LV_AFL_defekt : 19|1@1+ (1,0) [0|1] "" ZR_High
 SG_ LV_Blinker_li_def : 20|1@1+ (1,0) [0|1] "" ZR_High
 SG_ LV_Standlicht_li_def : 21|1@1+ (1,0) [0|1] "" ZR_High
 SG_ LV_Abblendlicht_li_def : 22|1@1+ (1,0) [0|1] "" ZR_High
 SG_ LV_Fernlicht_li_def : 23|1@1+ (1,0) [0|1] "" ZR_High
 SG_ LV_Nebellicht_li_def : 24|1@1+ (1,0) [0|1] "" ZR_High
 SG_ LV_Blk_li_Seite_def : 25|1@1+ (1,0) [0|1] "" ZR_High
 SG_ LV_Tagfahrlicht_li_def : 26|1@1+ (1,0) [0|1] "" ZR_High
 SG_ LV_FLA_aktiv_Anzeige : 27|1@1+ (1,0) [0|1] "" OTA_FC,ZR_High
 SG_ LV_FLA_defekt : 28|1@1+ (1,0) [0|1] "" ZR_High
 SG_ LV_FLA_Sensor_blockiert : 29|1@1+ (1,0) [0|1] "" OTA_FC,ZR_High
 SG_ LV_Blinker_re_def : 30|1@1+ (1,0) [0|1] "" ZR_High
 SG_ LV_Standlicht_re_def : 31|1@1+ (1,0) [0|1] "" ZR_High
 SG_ LV_Abblendlicht_re_def : 32|1@1+ (1,0) [0|1] "" ZR_High
 SG_ LV_Fernlicht_re_def : 33|1@1+ (1,0) [0|1] "" ZR_High
 SG_ LV_Nebellicht_re_def : 34|1@1+ (1,0) [0|1] "" ZR_High
 SG_ LV_Blk_re_Seite_def : 35|1@1+ (1,0) [0|1] "" ZR_High
 SG_ LV_Tagfahrlicht_re_def : 36|1@1+ (1,0) [0|1] "" ZR_High
 SG_ LV_Aussenlicht_def : 37|1@1+ (1,0) [0|1] "" ZR_High
 SG_ LV_Abblendlicht_TFL_li_def : 38|1@1+ (1,0) [0|1] "" ZR_High
 SG_ LV_Nebellicht_TFL_li_def : 39|1@1+ (1,0) [0|1] "" ZR_High
 SG_ LV_Standlicht_TFL_li_def : 40|1@1+ (1,0) [0|1] "" ZR_High
 SG_ LV_Abblend_Fernlicht_li_def : 41|1@1+ (1,0) [0|1] "" ZR_High
 SG_ LV_Abblendlicht_TFL_re_def : 42|1@1+ (1,0) [0|1] "" ZR_High
 SG_ LV_Nebellicht_TFL_re_def : 43|1@1+ (1,0) [0|1] "" ZR_High
 SG_ LV_Standlicht_TFL_re_def : 44|1@1+ (1,0) [0|1] "" ZR_High
 SG_ LV_Abblend_Fernlicht_re_def : 45|1@1+ (1,0) [0|1] "" ZR_High
 SG_ LV_Abbiegelicht_li_def : 46|1@1+ (1,0) [0|1] "" Vector__XXX
 SG_ LV_Abbiegelicht_re_def : 47|1@1+ (1,0) [0|1] "" Vector__XXX
 SG_ BCM1_Linksverkehr : 48|1@1+ (1,0) [0|1] "" OTA_FC,ZR_High
 SG_ BCM1_Licht_Dunkelheit_aktiv : 49|1@1+ (1,0) [0|1] "" OTA_FC,ZR_High
 SG_ LV_LED_Scheinwerfer_li_def : 50|1@1+ (1,0) [0|1] "" Vector__XXX
 SG_ LV_LED_Scheinwerfer_re_def : 51|1@1+ (1,0) [0|1] "" Vector__XXX
 SG_ LV_Blinker_VL_aktiv : 52|1@1+ (1,0) [0|1] "" OTA_FC,ZR_High
 SG_ LV_Blinker_VR_aktiv : 53|1@1+ (1,0) [0|1] "" OTA_FC,ZR_High
 SG_ LV_MXB_Status_Anzeige : 54|2@1+ (1,0) [0|3] "" Vector__XXX

BO_ 1629 ESP_20: 8 Gateway
 SG_ ESP_20_CRC : 0|8@1+ (1,0) [0|255] "" Vector__XXX
 SG_ ESP_20_BZ : 8|4@1+ (1,0) [0|15] "" Vector__XXX
 SG_ BR_Systemart : 12|2@1+ (1,0) [0|3] "" Vector__XXX
 SG_ ESP_SpannungsAnf_02 : 14|2@1+ (1,0) [0|3] "" Vector__XXX
 SG_ ESP_Zaehnezahl : 16|8@1+ (1,0) [0|255] "" Vector__XXX
 SG_ ESP_Charisma_FahrPr : 24|4@1+ (1,0) [0|15] "" Vector__XXX
 SG_ ESP_Charisma_Status : 28|2@1+ (1,0) [0|3] "" Vector__XXX
 SG_ ESP_Wiederstart_Anz_01 : 30|1@1+ (1,0) [0|1] "" Vector__XXX
 SG_ ESP_Wiederstart_Anz_02 : 31|1@1+ (1,0) [0|1] "" Vector__XXX
 SG_ ESP_Wiederstart_Anz_03 : 32|1@1+ (1,0) [0|1] "" Vector__XXX
 SG_ ESP_Wiederstart_Anz_04 : 33|1@1+ (1,0) [0|1] "" Vector__XXX
 SG_ ESP_Stoppverbot_Anz_01 : 34|1@1+ (1,0) [0|1] "" Vector__XXX
 SG_ ESP_Stoppverbot_Anz_02 : 35|1@1+ (1,0) [0|1] "" Vector__XXX
 SG_ ESP_Stoppverbot_Anz_03 : 36|1@1+ (1,0) [0|1] "" Vector__XXX
 SG_ ESP_Stoppverbot_Anz_04 : 37|1@1+ (1,0) [0|1] "" Vector__XXX
 SG_ ESP_Stoppverbot_Anz_05 : 38|1@1+ (1,0) [0|1] "" Vector__XXX
 SG_ ESP_Stoppverbot_Anz_06 : 39|1@1+ (1,0) [0|1] "" Vector__XXX
 SG_ ESP_Stoppverbot_Anz_07 : 40|1@1+ (1,0) [0|1] "" Vector__XXX
 SG_ ESP_Stoppverbot_Anz_Std : 41|1@1+ (1,0) [0|1] "" Vector__XXX
 SG_ ESP_Dachrelingsensor : 42|2@1+ (1,0) [0|3] "" Vector__XXX
 SG_ ESP_Stoppverbot_Anz_08 : 44|1@1+ (1,0) [0|1] "" Vector__XXX
 SG_ HDC_Charisma_FahrPr : 45|4@1+ (1,0) [0|15] "" Vector__XXX
 SG_ HDC_Charisma_Status : 49|2@1+ (1,0) [0|3] "" Vector__XXX
 SG_ BR_QBit_Reifenumfang : 51|1@1+ (1,0) [0|1] "" AWC
 SG_ BR_Reifenumfang : 52|12@1+ (1,0) [0|4095] "Unit_MilliMeter" AWC

BO_ 1631 Motor_16: 8 Gateway
 SG_ TSK_Grundmasse : 0|8@1+ (32,0) [0|8128] "Unit_KiloGram" ZR_High
 SG_ TSK_QBit_Steigung : 12|1@1+ (1,0) [0|1] "" Vector__XXX
 SG_ TSK_QBit_Fahrzeugmasse : 13|1@1+ (1,0) [0|1] "" ZR_High
 SG_ MO_SpannungsAnf_02 : 14|2@1+ (1,0) [0|3] "" Vector__XXX
 SG_ MO_DPF_reg : 16|1@1+ (1,0) [0|1] "" ZR_High
 SG_ MO_Heizstrom_EKAT : 17|7@1+ (1,0) [0|126] "Unit_Amper" Vector__XXX
 SG_ MO_Heizstrom_SCR : 24|6@1+ (1,0) [0|62] "Unit_Amper" Vector__XXX
 SG_ MO_Anzeige_Kaltleuchte : 30|1@1+ (1,0) [0|1] "" Vector__XXX
 SG_ MO_P_Generator_ungefiltert_Anf : 31|1@1+ (1,0) [0|1] "" Vector__XXX
 SG_ TSK_Getriebeinfo : 34|2@1+ (1,0) [0|3] "" Vector__XXX
 SG_ MO_Energieinhalt_BMS : 36|12@1+ (25,0) [0|102325] "Unit_WattHour" Vector__XXX
 SG_ TSK_Fahrzeugmasse_02 : 48|8@1+ (32,0) [0|8128] "Unit_KiloGram" OTA_FC,ZR_High
 SG_ TSK_Steigung_02 : 56|8@1+ (0.8,-101.6) [-100.8|101.6] "Unit_PerCent" OTA_FC

BO_ 1640 Klima_12: 8 Gateway
 SG_ KL_LRH_Taster : 0|1@1+ (1,0) [0|1] "" Vector__XXX
 SG_ KL_LRH_Stufe : 1|2@1+ (1,0) [0|3] "" Vector__XXX
 SG_ HSH_Taster : 3|2@1+ (1,0) [0|3] "" Vector__XXX
 SG_ FSH_Taster : 5|1@1+ (1,0) [0|1] "" Vector__XXX
 SG_ KL_Zuheizer_Freigabe : 6|1@1+ (1,0) [0|1] "" TME
 SG_ KL_Beschlagsgefahr : 7|1@1+ (1,0) [0|1] "" TME
 SG_ KL_SIH_Soll_li : 8|3@1+ (1,0) [0|7] "" TME
 SG_ KL_SIH_Soll_re : 11|3@1+ (1,0) [0|7] "" TME
 SG_ KRH_Soll_li : 14|2@1+ (1,0) [0|3] "" Vector__XXX
 SG_ KL_SIL_Soll_li : 16|3@1+ (1,0) [0|7] "" TME
 SG_ KL_SIL_Soll_re : 19|3@1+ (1,0) [0|7] "" TME
 SG_ KRH_Soll_re : 22|2@1+ (1,0) [0|3] "" Vector__XXX
 SG_ KL_Geblspng_Soll : 24|8@1+ (0.05,1.45) [1.5|14] "Unit_Volt" Vector__XXX
 SG_ KL_Geblspng_Fond_Soll : 32|8@1+ (0.05,1.45) [1.5|14] "Unit_Volt" Vector__XXX
 SG_ KL_I_Geblaese : 40|8@1+ (0.25,0) [0|63.5] "Unit_Amper" Vector__XXX
 SG_ KL_Kompressorstrom_soll : 48|10@1+ (1,0) [0|1021] "" TME
 SG_ KL_Umluftklappe_Status : 58|4@1+ (1,0) [0|15] "" TME
 SG_ KL_PTC_Verbauinfo : 62|2@1+ (1,0) [0|3] "" Vector__XXX

BO_ 1648 Motor_18: 8 Gateway
 SG_ MO_max_Ladedruck : 0|6@1+ (0.1,0) [0|6.3] "Unit_Bar" Sub_Gateway
 SG_ MO_ANC_Kennfeld_Anf : 6|2@1+ (1,0) [0|3] "" Sub_Gateway
 SG_ MO_Bremslicht_Reku : 8|1@1+ (1,0) [0|1] "" Sub_Gateway
 SG_ MO_StartStopp_PopUp : 9|2@1+ (1,0) [0|3] "" Sub_Gateway
 SG_ MO1_Sperr_Info_WFS : 11|1@1+ (1,0) [0|1] "" Sub_Gateway
 SG_ MO1_Freigabe_Info_WFS : 12|1@1+ (1,0) [0|1] "" Sub_Gateway
 SG_ MO_EPCL : 13|3@1+ (1,0) [0|7] "" Sub_Gateway
 SG_ MO_Zylabsch_Texte_02 : 16|4@1+ (1,0) [0|15] "" Sub_Gateway
 SG_ MO_Fahrzeugtyp : 20|3@1+ (1,0) [0|7] "" BMS_NV,Sub_Gateway
 SG_ MO_NMAX_Schaltanzeige : 23|9@1+ (25,0) [0|12775] "Unit_MinutInver" Sub_Gateway
 SG_ MO_Abstellzeit : 32|8@1+ (8,0) [0|2024] "Unit_Minut" BMS_NV,Sub_Gateway,TME
 SG_ MO_Abstellzeit_Status : 40|2@1+ (1,0) [0|3] "" BMS_NV,Sub_Gateway,TME
 SG_ MO1_Freigabe_Verfallsinfo_WFS : 42|1@1+ (1,0) [0|1] "" Sub_Gateway
 SG_ MO_Hybrid_StartStopp_LED : 43|2@1+ (1,0) [0|3] "" Sub_Gateway
 SG_ MO_Fehler_Zylabsch : 45|2@1+ (1,0) [0|3] "" Sub_Gateway
 SG_ MO_Anzahl_Abgesch_Zyl : 47|3@1+ (1,0) [0|7] "" Sub_Gateway
 SG_ MO_Zylabsch_Texte : 50|2@1+ (1,0) [0|3] "" Sub_Gateway
 SG_ MO_Ethanol_BS_Texte : 52|3@1+ (1,0) [0|7] "" Sub_Gateway
 SG_ MO_Drehzahl_Warnung : 55|1@1+ (1,0) [0|1] "" Sub_Gateway
 SG_ MO_obere_Drehzahlgrenze : 56|8@1+ (50,0) [50|12750] "Unit_MinutInver" Sub_Gateway

BO_ 1710 Spiegel_01: 8 Gateway
 SG_ SP_FT_oben : 0|1@1+ (1,0) [0|1] "" OTA_FC,ZR_High
 SG_ SP_FT_unten : 1|1@1+ (1,0) [0|1] "" OTA_FC,ZR_High
 SG_ SP_FT_links : 2|1@1+ (1,0) [0|1] "" OTA_FC,ZR_High
 SG_ SP_FT_rechts : 3|1@1+ (1,0) [0|1] "" OTA_FC,ZR_High
 SG_ SP_BT_oben : 4|1@1+ (1,0) [0|1] "" OTA_FC,ZR_High
 SG_ SP_BT_unten : 5|1@1+ (1,0) [0|1] "" OTA_FC,ZR_High
 SG_ SP_BT_links : 6|1@1+ (1,0) [0|1] "" OTA_FC,ZR_High
 SG_ SP_BT_rechts : 7|1@1+ (1,0) [0|1] "" OTA_FC,ZR_High
 SG_ SP_abklappen : 8|1@1+ (1,0) [0|1] "" OTA_FC,ZR_High
 SG_ SP_anklappen : 9|1@1+ (1,0) [0|1] "" OTA_FC,ZR_High
 SG_ SP_normieren : 10|1@1+ (1,0) [0|1] "" OTA_FC,ZR_High
 SG_ SP_Hzg_Taster : 12|1@1+ (1,0) [0|1] "" OTA_FC,ZR_High
 SG_ SP_S_oben : 16|1@1+ (1,0) [0|1] "" ZR_High
 SG_ SP_S_unten : 17|1@1+ (1,0) [0|1] "" ZR_High
 SG_ SP_S_links : 18|1@1+ (1,0) [0|1] "" ZR_High
 SG_ SP_S_rechts : 19|1@1+ (1,0) [0|1] "" ZR_High
 SG_ SP_Auswahl_li : 20|1@1+ (1,0) [0|1] "" ZR_High
 SG_ SP_Auswahl_re : 21|1@1+ (1,0) [0|1] "" ZR_High
 SG_ SP_ARA_Status : 22|1@1+ (1,0) [0|1] "" ZR_High
 SG_ SP_S_Klappen : 23|1@1+ (1,0) [0|1] "" ZR_High
 SG_ SP_Verstellschalter_Fehler : 24|1@1+ (1,0) [0|1] "" ZR_High

BO_ 1711 Rear_View_01: 8 Gateway
 SG_ RV_Video_on : 0|1@1+ (1,0) [0|1] "" ZR_High,ZR_Standard
 SG_ RV_Dark_Screen : 1|1@1+ (1,0) [0|1] "" ZR_High,ZR_Standard
 SG_ RV_HMI_Mode : 2|2@1+ (1,0) [0|3] "" ZR_High,ZR_Standard
 SG_ RV_GL_side : 4|2@1+ (1,0) [0|3] "" ZR_High,ZR_Standard
 SG_ RV_System_aktiv : 6|1@1+ (1,0) [0|1] "" ZR_High,ZR_Standard
 SG_ RV_Reinigung_Anf : 7|1@1+ (1,0) [0|1] "" OTA_FC,ZR_High
 SG_ RV_Settings_enabled : 8|1@1+ (1,0) [0|1] "" ZR_High
 SG_ RV_Menu_Item : 9|2@1+ (1,0) [0|3] "" ZR_High
 SG_ SV_Video_on : 11|1@1+ (1,0) [0|1] "" ZR_High,ZR_Standard
 SG_ RV_Calib_Fehler : 12|1@1+ (1,0) [0|1] "" ZR_High
 SG_ RV_GL_Trailer_connect : 13|1@1+ (1,0) [0|1] "" ZR_High,ZR_Standard
 SG_ RV_GL_Trunk_open : 14|1@1+ (1,0) [0|1] "" ZR_High,ZR_Standard
 SG_ RV_GL_LWS_Fehler : 15|1@1+ (1,0) [0|1] "" ZR_High
 SG_ RV_Helligkeit : 16|7@1+ (1,0) [0|100] "Unit_PerCent" ZR_High,ZR_Standard
 SG_ ZFAS_Umfeldbeleuchtung_Anf : 23|1@1+ (1,0) [0|1] "" Vector__XXX
 SG_ RV_Kontrast : 24|7@1+ (1,0) [0|100] "Unit_PerCent" ZR_High,ZR_Standard
 SG_ RV_Farbe : 32|7@1+ (1,0) [0|100] "Unit_PerCent" ZR_High,ZR_Standard

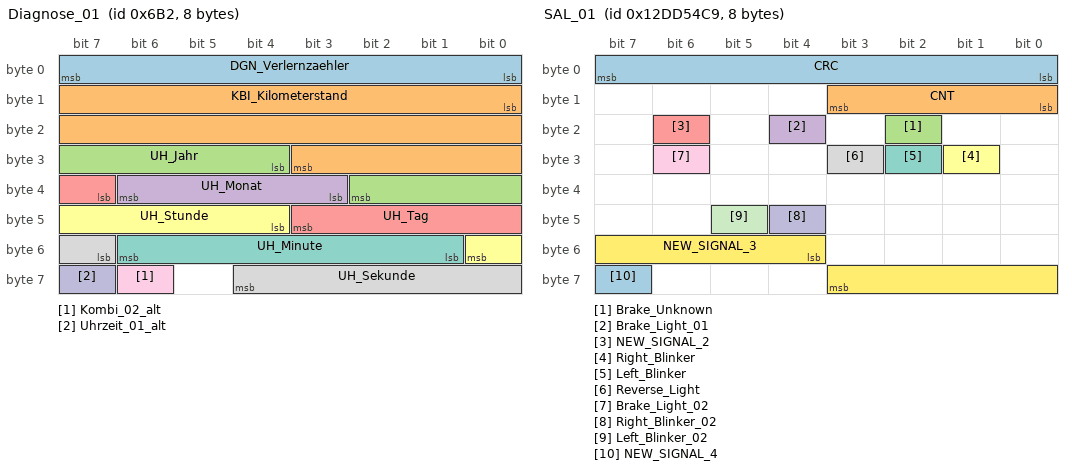
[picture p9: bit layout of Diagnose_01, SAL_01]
BO_ 1714 Diagnose_01: 8 Gateway_MQB
 SG_ DGN_Verlernzaehler : 0|8@1+ (1,0) [0|254] "" Airbag_MQB,BMS_MQB,Getriebe_DQ_Hybrid_MQB,Getriebe_DQ_MQB,LEH_MQB,SAK_MQB
 SG_ KBI_Kilometerstand : 8|20@1+ (1,0) [0|1048573] "Unit_KiloMeter" Airbag_MQB,BMS_MQB,Getriebe_DQ_Hybrid_MQB,Getriebe_DQ_MQB,LEH_MQB,Motor_Diesel_MQB,Motor_Hybrid_MQB,Motor_Otto_MQB,SAK_MQB
 SG_ UH_Jahr : 28|7@1+ (1,2000) [2000|2127] "Unit_Year" Airbag_MQB,BMS_MQB,Getriebe_DQ_Hybrid_MQB,Getriebe_DQ_MQB,LEH_MQB,Motor_Diesel_MQB,Motor_Hybrid_MQB,Motor_Otto_MQB,SAK_MQB
 SG_ UH_Monat : 35|4@1+ (1,0) [1|12] "Unit_Month" Airbag_MQB,BMS_MQB,Getriebe_DQ_Hybrid_MQB,Getriebe_DQ_MQB,LEH_MQB,Motor_Diesel_MQB,Motor_Hybrid_MQB,Motor_Otto_MQB,SAK_MQB
 SG_ UH_Tag : 39|5@1+ (1,0) [1|31] "Unit_Day" Airbag_MQB,BMS_MQB,Getriebe_DQ_Hybrid_MQB,Getriebe_DQ_MQB,LEH_MQB,Motor_Diesel_MQB,Motor_Hybrid_MQB,Motor_Otto_MQB,SAK_MQB
 SG_ UH_Stunde : 44|5@1+ (1,0) [0|23] "Unit_Hours" Airbag_MQB,BMS_MQB,Getriebe_DQ_Hybrid_MQB,Getriebe_DQ_MQB,LEH_MQB,Motor_Diesel_MQB,Motor_Hybrid_MQB,Motor_Otto_MQB,SAK_MQB
 SG_ UH_Minute : 49|6@1+ (1,0) [0|59] "Unit_Minut" Airbag_MQB,BMS_MQB,Getriebe_DQ_Hybrid_MQB,Getriebe_DQ_MQB,LEH_MQB,Motor_Diesel_MQB,Motor_Hybrid_MQB,Motor_Otto_MQB,SAK_MQB
 SG_ UH_Sekunde : 55|6@1+ (1,0) [0|59] "Unit_Secon" Airbag_MQB,BMS_MQB,Getriebe_DQ_Hybrid_MQB,Getriebe_DQ_MQB,LEH_MQB,Motor_Diesel_MQB,Motor_Hybrid_MQB,Motor_Otto_MQB,SAK_MQB
 SG_ Kombi_02_alt : 62|1@1+ (1,0) [0|1] "" Airbag_MQB,BMS_MQB,LEH_MQB
 SG_ Uhrzeit_01_alt : 63|1@1+ (1,0) [0|1] "" Airbag_MQB,BMS_MQB,LEH_MQB

BO_ 1716 VIN_01: 8 Gateway_MQB
 SG_ VIN_01_MUX M : 0|2@1+ (1,0) [0|3] "" Airbag_MQB
 SG_ KS_Geheimnis_1 m0 : 8|8@1+ (1,0) [0|255] "" Vector__XXX
 SG_ KS_Geheimnis_2 m0 : 16|8@1+ (1,0) [0|255] "" Vector__XXX
 SG_ KS_Geheimnis_3 m0 : 24|8@1+ (1,0) [0|255] "" Vector__XXX
 SG_ KS_Geheimnis_4 m0 : 32|8@1+ (1,0) [0|255] "" Vector__XXX
 SG_ VIN_1 m0 : 40|8@1+ (1,0) [0|255] "" Airbag_MQB
 SG_ VIN_2 m0 : 48|8@1+ (1,0) [0|255] "" Airbag_MQB
 SG_ VIN_3 m0 : 56|8@1+ (1,0) [0|255] "" Airbag_MQB
 SG_ VIN_4 m1 : 8|8@1+ (1,0) [0|255] "" Airbag_MQB
 SG_ VIN_5 m1 : 16|8@1+ (1,0) [0|255] "" Airbag_MQB
 SG_ VIN_6 m1 : 24|8@1+ (1,0) [0|255] "" Airbag_MQB
 SG_ VIN_7 m1 : 32|8@1+ (1,0) [0|255] "" Airbag_MQB
 SG_ VIN_8 m1 : 40|8@1+ (1,0) [0|255] "" Airbag_MQB
 SG_ VIN_9 m1 : 48|8@1+ (1,0) [0|255] "" Airbag_MQB
 SG_ VIN_10 m1 : 56|8@1+ (1,0) [0|255] "" Airbag_MQB
 SG_ VIN_11 m2 : 8|8@1+ (1,0) [0|255] "" Airbag_MQB
 SG_ VIN_12 m2 : 16|8@1+ (1,0) [0|255] "" Airbag_MQB
 SG_ VIN_13 m2 : 24|8@1+ (1,0) [0|255] "" Airbag_MQB
 SG_ VIN_14 m2 : 32|8@1+ (1,0) [0|255] "" Airbag_MQB
 SG_ VIN_15 m2 : 40|8@1+ (1,0) [0|255] "" Airbag_MQB
 SG_ VIN_16 m2 : 48|8@1+ (1,0) [0|255] "" Airbag_MQB
 SG_ VIN_17 m2 : 56|8@1+ (1,0) [0|255] "" Airbag_MQB

BO_ 316495015 VZE_04: 32 XXX
 SG_ VZE_Anzeigemodus : 0|2@1+ (1,0) [0|3] "" ZR_High,ZR_LIMU,ZR_MIB_TOP_ab_Gen3
 SG_ Detected_01 : 8|1@0+ (1,0) [0|1] "" XXX
 SG_ VZE_Anzeigeunterdrueck_Zeichen_3 : 9|1@1+ (1,0) [0|1] "" Vector__XXX
 SG_ VZE_Anzeigeunterdrueck_Zeichen_2 : 10|1@1+ (1,0) [0|1] "" Vector__XXX
 SG_ VZE_Verkehrszeichen_1 : 11|8@1+ (5,0) [1|520] "" OTA_FC,ZR_High,ZR_LIMU,ZR_MIB_TOP_ab_Gen3
 SG_ VZE_Verkehrszeichen_2 : 19|8@1+ (5,0) [1|255] "" OTA_FC,ZR_High,ZR_LIMU,ZR_MIB_TOP_ab_Gen3
 SG_ VZE_Verkehrszeichen_3 : 27|8@1+ (5,0) [1|255] "" OTA_FC,ZR_High,ZR_LIMU,ZR_MIB_TOP_ab_Gen3
 SG_ VZE_Warnung_Verkehrszeichen_1 : 35|1@1+ (1,0) [0|1] "" ZR_High,ZR_LIMU,ZR_MIB_TOP_ab_Gen3
 SG_ VZE_Warnung_Verkehrszeichen_2 : 36|1@1+ (1,0) [0|1] "" ZR_High,ZR_LIMU,ZR_MIB_TOP_ab_Gen3
 SG_ VZE_Warnung_Verkehrszeichen_3 : 37|1@1+ (1,0) [0|1] "" ZR_High,ZR_LIMU,ZR_MIB_TOP_ab_Gen3
 SG_ VZE_Zusatzschild_1 : 38|4@1+ (1,0) [1|15] "" ZR_High,ZR_LIMU,ZR_MIB_TOP_ab_Gen3
 SG_ VZE_Zusatzschild_2 : 42|4@1+ (1,0) [1|15] "" ZR_High,ZR_LIMU,ZR_MIB_TOP_ab_Gen3
 SG_ VZE_Zusatzschild_3 : 46|4@1+ (1,0) [1|15] "" ZR_High,ZR_LIMU,ZR_MIB_TOP_ab_Gen3
 SG_ VZE_Anzeigeunterdrueck_Zeichen_1 : 50|1@1+ (1,0) [0|1] "" Vector__XXX
 SG_ VZE_Zeichen_01_KameraWied : 51|1@1+ (1,0) [0|1] "" ZR_High,ZR_LIMU,ZR_MIB_TOP_ab_Gen3
 SG_ VZE_Zeichen_02_KameraWied : 52|1@1+ (1,0) [0|1] "" ZR_High,ZR_LIMU,ZR_MIB_TOP_ab_Gen3
 SG_ VZE_Zeichen_03_KameraWied : 53|1@1+ (1,0) [0|1] "" ZR_High,ZR_LIMU,ZR_MIB_TOP_ab_Gen3
 SG_ VZE_Zeichen_01_Kamera : 54|1@1+ (1,0) [0|1] "" ZR_High,ZR_LIMU,ZR_MIB_TOP_ab_Gen3
 SG_ VZE_Zeichen_01_Karte : 55|1@1+ (1,0) [0|1] "" ZR_High,ZR_LIMU,ZR_MIB_TOP_ab_Gen3
 SG_ VZE_Zeichen_01_Gesetz : 56|1@1+ (1,0) [0|1] "" ZR_High,ZR_LIMU,ZR_MIB_TOP_ab_Gen3
 SG_ VZE_Zeichen_02_Kamera : 57|1@1+ (1,0) [0|1] "" ZR_High,ZR_LIMU,ZR_MIB_TOP_ab_Gen3
 SG_ VZE_Zeichen_02_Karte : 58|1@1+ (1,0) [0|1] "" ZR_High,ZR_LIMU,ZR_MIB_TOP_ab_Gen3
 SG_ VZE_Zeichen_02_Gesetz : 59|1@1+ (1,0) [0|1] "" ZR_High,ZR_LIMU,ZR_MIB_TOP_ab_Gen3
 SG_ VZE_Zeichen_03_Kamera : 60|1@1+ (1,0) [0|1] "" ZR_High,ZR_LIMU,ZR_MIB_TOP_ab_Gen3
 SG_ VZE_Zeichen_03_Karte : 61|1@1+ (1,0) [0|1] "" ZR_High,ZR_LIMU,ZR_MIB_TOP_ab_Gen3
 SG_ VZE_Zeichen_03_Gesetz : 62|1@1+ (1,0) [0|1] "" ZR_High,ZR_LIMU,ZR_MIB_TOP_ab_Gen3
 SG_ VZE_Gong : 63|1@1+ (1,0) [0|1] "" ZR_High,ZR_LIMU,ZR_MIB_TOP_ab_Gen3
 SG_ VZE_Verkehrszeichen_4 : 75|8@1+ (1,0) [0|31] "" XXX
 SG_ VZE_Verkehrszeichen_6 : 92|7@1+ (1,0) [0|7] "" XXX
 SG_ VZE_Baustelle : 110|1@0+ (1,0) [0|1] "" XXX
 SG_ Zeichen_Unknown : 129|4@1+ (1,0) [0|15] "" XXX
 SG_ Zeichen_Unknown_Entfernung : 140|6@1+ (1,0) [0|15] "" XXX
 SG_ Zusatzschild_Unknown : 147|2@1+ (1,0) [0|3] "" XXX
 SG_ Unknown_02 : 167|4@1+ (1,0) [0|3] "" XXX
 SG_ Unknown_01 : 207|1@0+ (1,0) [0|1] "" XXX

BO_ 316495049 SAL_01: 8 XXX
 SG_ CRC : 0|8@1+ (1,0) [0|255] "" XXX
 SG_ CNT : 8|4@1+ (1,0) [0|15] "" XXX
 SG_ Brake_Unknown : 18|1@0+ (1,0) [0|1] "" XXX
 SG_ Brake_Light_01 : 20|1@0+ (1,0) [0|1] "" XXX
 SG_ NEW_SIGNAL_2 : 22|1@0+ (1,0) [0|1] "" XXX
 SG_ Right_Blinker : 25|1@0+ (1,0) [0|1] "" XXX
 SG_ Left_Blinker : 26|1@1+ (1,0) [0|3] "" XXX
 SG_ Reverse_Light : 27|1@0+ (1,0) [0|1] "" XXX
 SG_ Brake_Light_02 : 30|1@0+ (1,0) [0|1] "" XXX
 SG_ Right_Blinker_02 : 44|1@1+ (1,0) [0|3] "" XXX
 SG_ Left_Blinker_02 : 45|1@0+ (1,0) [0|1] "" XXX
 SG_ NEW_SIGNAL_3 : 52|8@1+ (1,0) [0|15] "" XXX
 SG_ NEW_SIGNAL_4 : 63|1@0+ (1,0) [0|1] "" XXX

BO_ 316495081 MEB_Camera_05: 8 XXX

BO_ 316495106 AAA_01: 8 XXX
 SG_ CRC : 0|8@1+ (1,0) [0|255] "" XXX
 SG_ CHK : 8|4@1+ (1,0) [0|15] "" XXX

BO_ 316495140 MEB_Camera_06: 64 XXX

BO_ 316495165 HVL_01: 8 XXX
 SG_ CRC : 0|8@1+ (1,0) [0|255] "" XXX
 SG_ CHK : 8|4@1+ (1,0) [0|15] "" XXX

BO_ 380195935 IPA_02: 8 XXX

BO_ 380196019 MEB_Camera_07: 16 XXX

BO_ 380196034 MEB_Radar_Unknown_01: 8 XXX

BO_ 380196036 MEB_Camera_08: 8 XXX

BO_ 389241617 MEB_Camera_10: 8 XXX

BO_ 401604687 MEB_Camera_11: 8 XXX

BO_ 402522959 MEB_Camera_14: 8 XXX

BO_ 441800001 EML_02: 8 XXX
 SG_ CRC : 0|8@1+ (1,0) [0|255] "" XXX
 SG_ CHK : 8|4@1+ (1,0) [0|15] "" XXX

BO_ 441800082 MEB_Camera_12: 8 XXX

BO_ 452984911 MEB_Camera_13: 8 XXX

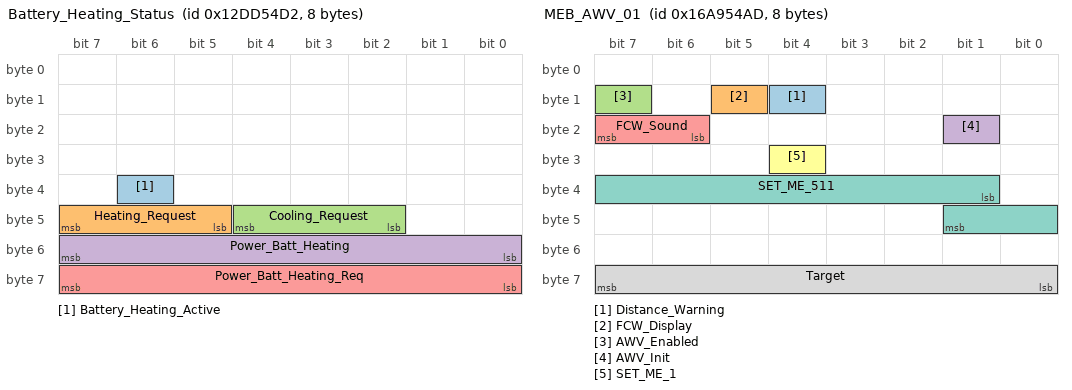
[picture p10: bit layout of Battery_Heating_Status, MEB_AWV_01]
BO_ 316495058 Battery_Heating_Status: 8 XXX
 SG_ Battery_Heating_Active : 38|1@1+ (1,0) [0|1] "" XXX
 SG_ Heating_Request : 45|3@1+ (1,0) [0|7] "" XXX
 SG_ Cooling_Request : 42|3@1+ (1,0) [0|7] "" XXX
 SG_ Power_Batt_Heating : 48|8@1+ (1,0) [0|255] "W" XXX
 SG_ Power_Batt_Heating_Req : 56|8@1+ (1,0) [0|255] "W" XXX

BO_ 441800114 Charging_Optimization: 8 XXX
 SG_ Temperature_Status_Charge : 15|3@1+ (1,0) [0|7] "" XXX

BO_ 316495056 Charging_Dynamics: 8 XXX
 SG_ Max_Charge_Power : 51|13@1+ (0.1,0) [0|819.1] "kW" XXX
 SG_ Max_Charge_Current : 25|13@1+ (0.2,0) [0|1638.2] "A" XXX

BO_ 380196006 Battery_Temperatures: 8 XXX
 SG_ Battery_Max_Temp : 24|8@1+ (0.5,-40) [-40|87.5] "degC" XXX
 SG_ Battery_Min_Temp : 32|8@1+ (0.5,-40) [-40|87.5] "degC" XXX

BO_ 380196013 MEB_AWV_01: 8 XXX
 SG_ Distance_Warning : 12|1@0+ (1,0) [0|1] "" XXX
 SG_ FCW_Display : 13|1@0+ (1,0) [0|1] "" XXX
 SG_ AWV_Enabled : 15|1@0+ (1,0) [0|1] "" XXX
 SG_ AWV_Init : 17|1@0+ (1,0) [0|1] "" XXX
 SG_ FCW_Sound : 22|2@1+ (1,0) [0|3] "" XXX
 SG_ SET_ME_1 : 28|1@0+ (1,0) [0|1] "" XXX
 SG_ SET_ME_511 : 33|9@1+ (1,0) [0|127] "" XXX
 SG_ Target : 56|8@1+ (1,0) [0|255] "" XXX

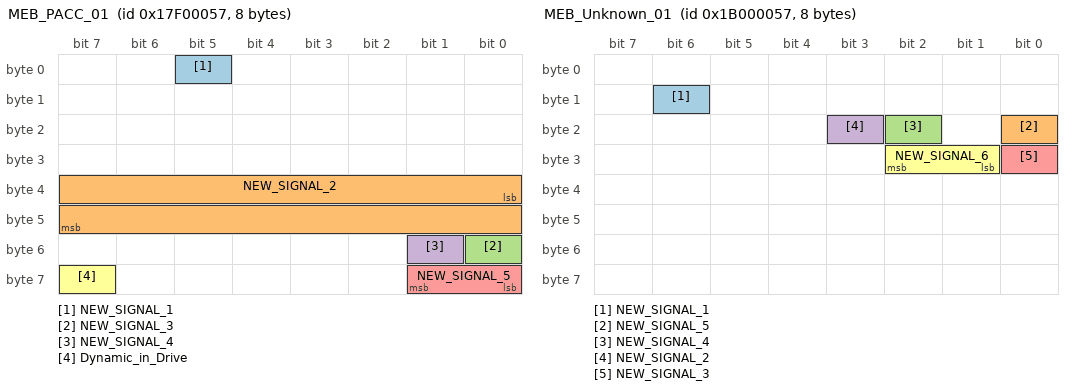
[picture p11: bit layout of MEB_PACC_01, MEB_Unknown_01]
BO_ 401604695 MEB_PACC_01: 8 XXX
 SG_ NEW_SIGNAL_1 : 5|1@0+ (1,0) [0|1] "" XXX
 SG_ NEW_SIGNAL_2 : 32|16@1+ (1,0) [0|255] "" XXX
 SG_ NEW_SIGNAL_3 : 48|1@0+ (1,0) [0|1] "" XXX
 SG_ NEW_SIGNAL_4 : 49|1@0+ (1,0) [0|1] "" XXX
 SG_ NEW_SIGNAL_5 : 56|2@1+ (1,0) [0|3] "" XXX
 SG_ Dynamic_in_Drive : 63|1@0+ (1,0) [0|1] "" XXX

BO_ 452984919 MEB_Unknown_01: 8 XXX
 SG_ NEW_SIGNAL_1 : 14|1@0+ (1,0) [0|1] "" XXX
 SG_ NEW_SIGNAL_5 : 16|1@0+ (1,0) [0|1] "" XXX
 SG_ NEW_SIGNAL_4 : 18|1@0+ (1,0) [0|1] "" XXX
 SG_ NEW_SIGNAL_2 : 19|1@0+ (1,0) [0|1] "" XXX
 SG_ NEW_SIGNAL_3 : 24|1@0+ (1,0) [0|1] "" XXX
 SG_ NEW_SIGNAL_6 : 25|2@1+ (1,0) [0|3] "" XXX

CM_ BO_ 317 "Lenkungssteuergerät";
CM_ BO_ 1622 "Steuergerät für Lenkungsverriegelung";
CM_ BO_ 316495165 "Steuergerät ICAS1";
CM_ BO_ 441800001 "Steuergerät für Fahrzeugbewegung";
VAL_ 981 BCM1_Kurvenlicht_links_Anf 0 "linkes_Kurvenlicht/Abbiegelicht_durch_BCM1_nicht_angesteuert" 1 "linkes_Kurven/Abbiegelicht_durch_BCM1_angesteuert";
VAL_ 981 BCM1_Kurvenlicht_rechts_Anf 0 "rechtes_Kurvenlicht/Abbiegelicht_durch_BCM1_nicht_angesteuert" 1 "rechtes_Kurvenlicht/Abbiegelicht_durch_BCM1_angesteuert";
VAL_ 981 BCM1_Standlicht_Anf 0 "Licht_nicht_angefordert" 1 "Licht ist einzuschalten";
VAL_ 981 BCM1_Abblendlicht_Anf 0 "Licht_nicht_angefordert" 1 "Licht ist einzuschalten";
VAL_ 981 BCM1_Fernlicht_Anf 0 "Licht_nicht_angefordert" 1 "Licht ist einzuschalten";
VAL_ 981 BCM1_Nebellicht_Anf 0 "Licht_nicht_angefordert" 1 "Licht ist einzuschalten";
VAL_ 981 BCM1_Parklicht_li_Anf 0 "Licht_nicht_angefordert" 1 "Licht ist einzuschalten";
VAL_ 981 BCM1_Parklicht_re_Anf 0 "Licht_nicht_angefordert" 1 "Licht ist einzuschalten";
VAL_ 981 BCM1_Nebelschluss_Ahg_Anf 0 "Licht_nicht_angefordert" 1 "Licht ist einzuschalten";
VAL_ 981 BCM1_Nebelschluss_Fzg_Anf 0 "Licht_nicht_angefordert" 1 "Licht ist einzuschalten";
VAL_ 981 BCM1_Schlusslicht_Anf 0 "Licht_nicht_angefordert" 1 "Licht ist einzuschalten";
VAL_ 981 BCM_Rueckfahrlicht_Anf 0 "Licht_nicht_angefordert" 1 "Licht_angefordert";
VAL_ 981 BCM1_Signaturlicht_Anf 0 "Licht_nicht_angefordert" 1 "Licht_ist_einzuschalten";
VAL_ 981 BCM1_Umfeldleuchten_Anf 0 "Licht_nicht_angefordert" 1 "Licht_ist_einzuschalten";
VAL_ 981 BCM1_Tagfahrlicht_Anf 0 "Licht_nicht_angefordert" 1 "Licht ist einzuschalten";
VAL_ 981 BCM1_Regenlicht_Anf 0 "Licht_nicht_angefordert" 1 "Licht ist einzuschalten";
VAL_ 981 BCM1_Autobahnlicht_Anf 0 "Licht_nicht_angefordert" 1 "Licht ist einzuschalten";
VAL_ 981 BCM1_Touristen_Licht_Anf 0 "Licht_nicht_angefordert" 1 "Anforderung von Touristenlicht";
VAL_ 981 BCM1_CH_aktiv 0 "Inaktiv" 1 "Aktiv";
VAL_ 981 BCM1_LH_aktiv 0 "Inaktiv" 1 "Aktiv";
VAL_ 981 BCM1_Gleitende_Leuchtw_Anf 0 "Aus" 1 "Ein";
VAL_ 981 BCM1_GLW_Fernlicht_Anf 0 "Aus" 1 "Ein";
VAL_ 981 BCM1_Adaptive_Lichtvert_Anf 0 "Aus" 1 "Ein";
VAL_ 981 BCM1_FoD_Sperrung_WiBli 0 "Freigabe_WiBli" 1 "Sperrung_WiBli" 2 "Init";
VAL_ 981 BCM1_FOD_Sperrung_Animationen_HL 0 "Freigabe_Animationen" 1 "Sperrung_Animationen" 2 "Init";
VAL_ 981 BCM1_Animationssperrung 0 "keine_Sperrung" 1 "Sperrung";
VAL_ 981 BCM1_CH_LH_aktiv 0 "Comming_Home_Bzw._Leaving_Home_nicht_aktiv" 1 "Comming Home bzw. Leaving Home aktiv";
VAL_ 981 BCM1_Allwetterlicht_Anf 0 "Licht_nicht_angefordert" 1 "Licht_ist_einzuschalten";
VAL_ 981 BCM1_Schlusslicht_Signatur 0 "keine_Signatur" 1 "Signatur_1" 2 "Signatur_2" 3 "Signatur_3" 4 "Signatur_4" 5 "Signatur_5" 6 "Signatur_6" 7 "Signatur_7" 8 "Signatur_8" 9 "Signatur_9" 10 "Signatur_10" 11 "Signatur_11" 12 "Signatur_12" 13 "Signatur_13" 14 "Signatur_14" 15 "Signatur_15";
VAL_ 982 BCM2_Bremsl_durch_ECD 0 "Bremslicht_ist_aus" 1 "Bremslicht_durch_ECD_aktiv";
VAL_ 982 LH_Aussenlicht_def 0 "OK" 1 "defekt";
VAL_ 982 LH_Standlicht_H_aktiv 1 "Standlicht hinten aktiv";
VAL_ 982 LH_Parklicht_HL_aktiv 0 "nicht aktiv" 1 "Parklicht hinten links aktiv";
VAL_ 982 LH_Parklicht_HR_aktiv 0 "nicht aktiv" 1 "Parklicht hinten rechts aktiv";
VAL_ 982 LH_Bremslicht_H_aktiv 1 "Bremslicht hinten aktiv";
VAL_ 982 LH_Nebelschluss_aktiv 0 "nicht aktiv" 1 "aktiv";
VAL_ 982 LH_Rueckfahrlicht_aktiv 0 "nicht aktiv" 1 "aktiv";
VAL_ 982 LH_Blinker_HL_akt 1 "Blinker hinten links aktiv";
VAL_ 982 LH_Blinker_HR_akt 1 "Blinker hinten rechts aktiv";
VAL_ 982 LH_Blinker_li_def 0 "OK" 1 "Blinker hinten links defekt";
VAL_ 982 LH_Bremsl_li_def 0 "OK" 1 "mindestens ein Bremslicht hinten links defekt";
VAL_ 982 LH_Schlusslicht_li_def 0 "OK" 1 "mindestens ein Schlusslicht hinten links defekt";
VAL_ 982 LH_Rueckf_li_def 0 "OK" 1 "Rückfahrlicht hinten links defekt";
VAL_ 982 LH_Nebel_li_def 0 "OK" 1 "Nebelschlusslicht hinten links defekt";
VAL_ 982 LH_Schluss_Brems_Nebel_li_def 0 "iO" 1 "defekt";
VAL_ 982 LH_Schluss_Brems_Nebel_re_def 0 "iO" 1 "defekt";
VAL_ 982 LH_Zusatzschlussl_def 0 "OK" 1 "mindestens_ein_Zusatzschlusslicht_defekt";
VAL_ 982 LH_Schluss_Brems_li_def 0 "OK" 1 "defekt";
VAL_ 982 LH_Schluss_Nebel_li_def 0 "OK" 1 "defekt";
VAL_ 982 LH_SL_BRL_BLK_li_def 0 "OK" 1 "defekt";
VAL_ 982 LH_Brems_Blk_li_def 0 "OK" 1 "defekt";
VAL_ 982 LH_Diag_Status_re_def 0 "OK" 1 "Aussenlict_Diagnose_Systemstoerung_rechts";
VAL_ 982 LH_Diag_Status_li_def 0 "OK" 1 "Aussenlicht_Diagnose_Systemstoerung_links";
VAL_ 982 LH_Diag_LED_li_def 0 "OK" 1 "Heckleuchte_links_defekt";
VAL_ 982 LH_Diag_LED_re_def 0 "OK" 1 "Heckleuchte_rechts_defekt";
VAL_ 982 LH_Blinker_re_def 0 "OK" 1 "Blinker hinten rechts defekt";
VAL_ 982 LH_Bremsl_re_def 0 "OK" 1 "mindestens ein Bremslicht hinten rechts defekt";
VAL_ 982 LH_Schlusslicht_re_def 0 "OK" 1 "mindestens ein Schlusslicht hinten rechts defekt";
VAL_ 982 LH_Rueckf_re_def 0 "OK" 1 "Rückfahrlicht hinten rechts defekt";
VAL_ 982 LH_Nebel_re_def 0 "OK" 1 "Nebelschlusslicht hinten rechts defekt";
VAL_ 982 LH_Schluss_Brems_mi_def 0 "OK" 1 "Defekt";
VAL_ 982 LH_Schluss_Brems_re_def 0 "OK" 1 "defekt";
VAL_ 982 LH_Schluss_Nebel_re_def 0 "OK" 1 "defekt";
VAL_ 982 LH_SL_BRL_BLK_re_def 0 "OK" 1 "defekt";
VAL_ 982 LH_Brems_Blk_re_def 0 "OK" 1 "defekt";
VAL_ 982 LH_Kennzl_def 0 "OK" 1 "Kennzeichenbeleuchtung hinten defekt";
VAL_ 982 LH_3_Bremsl_def 0 "OK" 1 "hochgesetzte  Bremsleuchte defekt";
VAL_ 982 LH_Nebel_mi_def 0 "OK" 1 "Nebelschlusslicht hinten Mitte defekt";
VAL_ 982 LH_Rueckf_mi_def 0 "OK" 1 "Rückfahllicht Mitte defekt";
VAL_ 982 LH_Schlusslicht_mi_def 0 "OK" 1 "defekt";
VAL_ 982 LH_Bremsl_mi_def 0 "OK" 1 "defekt";
VAL_ 982 LH_Bremsl_li_ges_def 0 "OK" 1 "Alle Bremslichter hinten links defekt";
VAL_ 982 LH_Bremsl_re_ges_def 0 "OK" 1 "Alle Bremslichter hinten rechts defekt";
VAL_ 988 EPB_Status 0 "offen" 1 "geschlossen_Parken" 2 "teilgespannt_Halten" 3 "im_Lauf_oeffnen" 4 "im_Lauf_schliessen" 5 "tbd" 6 "Init" 7 "unbekannt";
VAL_ 988 GE_Fahrstufe 0 "Zwischenstellung" 1 "Init" 5 "P" 6 "R" 7 "N" 8 "D" 9 "D" 10 "E" 13 "T" 14 "T" 15 "Fehler";
VAL_ 997 FT_Tuer_Status 0 "Init" 1 "Tuer_geschlossen" 2 "Tuer_offen" 3 "Fehler";
VAL_ 997 FT_Tuer_Status_QBit 0 "Status_Tuerkontakt_sicher" 1 "Status_Tuerkontakt_unsicher";
VAL_ 997 FT_Lock_Taster_02 0 "nicht_betaetigt" 1 "betaetigt";
VAL_ 997 FT_Schluesselschalter_zu_02 0 "nicht_betaetigt" 1 "betaetigt";
VAL_ 997 FT_BFS_Tuer_Status 0 "Init" 1 "Tuer_geschlossen" 2 "Tuer_offen" 3 "Fehler";
VAL_ 997 FT_HBFS_Tuer_Status 0 "Init" 1 "Tuer_geschlossen" 2 "Tuer_offen" 3 "Fehler";
VAL_ 997 FT_HFS_Tuer_Status 0 "Init" 1 "Tuer_geschlossen" 2 "Tuer_offen" 3 "Fehler";
VAL_ 997 FT_Tueroeffnen_Warnung 0 "Tuerwarnung_nicht_aktiv" 1 "Tuerwarnung_aktiv";
VAL_ 997 FT_SP_Heizung_ein 0 "Aus" 1 "Ein";
VAL_ 997 FT_Kisi_Taster_li_02 0 "nicht_betaetigt" 1 "betaetigt";
VAL_ 997 FT_Kisi_Taster_re_02 0 "nicht_betaetigt" 1 "betaetigt";
VAL_ 997 FT_TD_Taste_Status 0 "kein_Fehler" 1 "Kurzschluss_nach_Minus" 2 "Kurzschluss_nach_Plus" 3 "Leitungsunterbrechung";
VAL_ 997 FT_TCR_Mode_aktiv 0 "TCR_Mode_deaktiv" 1 "TCR_Mode_aktiv";
VAL_ 997 FS_Push_Tuergriff 0 "nicht_erkannt" 1 "erkannt";
VAL_ 1004 TSK_State 0 "init" 1 "disabled" 2 "enabled" 3 "regulating" 4 "accel_pedal_override" 5 "brake_only" 6 "temp_fault" 7 "perm_fault";
VAL_ 1122 PSD_Segment_ID 0 "keine Segmentinformationen vorhanden" 1 "Fehlerwert";
VAL_ 1122 PSD_Vorgaenger_Segment_ID 0 "keine Segmentinformation vorhanden" 1 "Fehlerwert";
VAL_ 1122 PSD_Strassenkategorie 0 "Rest_Feldweg_Schotterweg_Privatweg" 1 "Ortsstraߥ" 2 "Kreisstraߥ" 3 "Landstraߥ" 4 "Bundesstraߥ" 5 "Autobahn" 7 "Init";
VAL_ 1122 PSD_Endkruemmung 255 "Gerade";
VAL_ 1122 PSD_Endkruemmung_Vorz 0 "Kruemmung_positiv" 1 "Kruemmung_negativ";
VAL_ 1122 PSD_Idenditaets_ID 0 "keine_Segment_Informationen_vorhanden" 1 "Fehler";
VAL_ 1122 PSD_ADAS_Qualitaet 0 "keine_ADAS_Qualitaet" 1 "ADAS_Qualitaet";
VAL_ 1122 PSD_wahrscheinlichster_Pfad 0 "Pfad_mit_geringer_Wahrscheinlichkeit" 1 "wahrscheinlichster_Pfad";
VAL_ 1122 PSD_Geradester_Pfad 0 "nicht_geradester_PFad" 1 "geradester_Pfad";
VAL_ 1122 PSD_Fahrspuren_Anzahl 0 "Einbahnstrasse_in_falsche_Richtung" 1 "eine_Fahrspur" 2 "zwei_Fahrspuren" 3 "drei_Fahrspuren" 4 "vier_Fahrspuren" 5 "fuenf_Fahrspuren" 6 "sechs_Fahrspuren" 7 "mehr_als_sechs_Fahrspuren";
VAL_ 1122 PSD_Bebauung 0 "ausserhalb_bebauten_Gebietes" 1 "innerhalb_bebauten_Gebietes";
VAL_ 1122 PSD_Segment_Komplett 0 "Segment_Attribute_nicht_komplett" 1 "Segment_Attribute_komplett";
VAL_ 1122 PSD_Rampe 0 "Strasse_mit_Gegenverkehr" 1 "Auffahrt_Einbahnstr" 2 "Abfahrt_Einbahnstr" 3 "Einbahnstrasse";
VAL_ 1122 PSD_Anfangskruemmung 255 "Gerade";
VAL_ 1122 PSD_Anfangskruemmung_Vorz 0 "positiv" 1 "negativ";
VAL_ 1122 PSD_Abzweigerichtung 0 "rects_abzweigende_Strasse" 1 "links_abzweigende_Strasse";
VAL_ 1123 PSD_Pos_Segment_ID 0 "keine Position gegeben" 1 "Fehlerwert";
VAL_ 1123 PSD_Pos_Standort_Eindeutig 0 "mehrdeutiger_Standort" 1 "eindeutiger_Standort";
VAL_ 1123 PSD_Pos_Fehler_Laengsrichtung 0 "Init" 1 "< 2m" 2 "< 5m" 3 "< 10m" 4 "< 20m" 5 "< 50m" 6 "> 50m" 7 "Off-Road";
VAL_ 1123 PSD_Pos_Fahrspur 0 "unbekannt" 1 "Erste_Spur_von_rechts" 2 "Zweite_Spur_von_rechts" 3 "Dritte_Spur_von_rechts" 4 "Vierte_Spur_von_rechts" 5 "Fuenfte_Spur_von_rechts" 6 "Sechte_Spur_von_rechts" 7 "Siebte_oder_weitere_Spur_von_rechts";
VAL_ 1123 PSD_Attribut_Segment_ID_05 0 "keine_Segment_Information" 1 "Fehler";
VAL_ 1123 PSD_Attribut_1_ID 0 "keine_Information";
VAL_ 1123 PSD_Attribut_2_ID 0 "keine_Information";
VAL_ 1123 PSD_Attribute_Komplett_05 0 "Attribute_nicht_komplett" 1 "Attribute_komplett";
VAL_ 1124 PSD_06_Mux 0 "Init";
VAL_ 1124 PSD_Sys_Segment_ID 0 "keine Segmentinformationen vorhanden" 1 "nicht zulaessig";
VAL_ 1124 PSD_Sys_Geschwindigkeit_Einheit 0 "km/h" 1 "mph";
VAL_ 1124 PSD_Sys_Verkehrsrichtung 0 "Rechtsverkehr" 1 "Linksverkehr";
VAL_ 1124 PSD_Sys_Geometrieguete 0 "Geringe_Guete" 1 "tbd" 2 "tbd" 3 "Hohe_Guete";
VAL_ 1124 PSD_Sys_Mapmatchingguete 0 "geringe_Guete" 1 "res" 2 "res" 3 "hohe_Guete";
VAL_ 1124 PSD_Sys_Alter_Karte 0 "kleiner_1_Jahr" 1 "1_Jahr" 2 "2_Jahre" 3 "3_Jahre" 4 "4_Jahre" 5 "5_Jahre" 6 "6_Jahre" 7 "groesser_7_Jahre";
VAL_ 1124 PSD_Sys_Zielfuehrung 0 "Zielfuehrung nicht aktiv" 1 "Zielfuehrung aktiv";
VAL_ 1124 PSD_Sys_US_State 0 "kein_US_State" 1 "Alabama" 2 "Alaska" 3 "Arkansas" 4 "Arizona" 5 "California" 6 "Colorado" 7 "Conneticut" 8 "District_of_Columbia" 9 "Delaware" 10 "Florida" 11 "Georgia" 12 "Hawaii" 13 "Idaho" 14 "Illinois" 15 "Iowa" 16 "Indiana" 17 "Kansas" 18 "Kentucky" 19 "Louisiana" 20 "Massachusetts" 21 "Maryland" 22 "Maine" 23 "Michigan" 24 "Minnesota" 25 "Missouri" 26 "Mississippi" 27 "Montana" 28 "North_Carolina" 29 "North_Dakota" 30 "Nebraska" 31 "Nevada" 32 "New_Hampshire" 33 "New_Jersey" 34 "New_Mexico" 35 "New_York" 36 "Ohio" 37 "Oklahoma" 38 "Oregon" 39 "Pennsylvania" 40 "Puerto_Rico" 41 "Rhode_Island" 42 "South_Carolina" 43 "South_Dakota" 44 "Tennessee" 45 "Texas" 46 "Utah" 47 "Virginia" 48 "Virgin_Islands" 49 "Vermont" 50 "Washington" 51 "Wisconsin" 52 "West_Virginia" 53 "Wyoming";
VAL_ 1124 PSD_Sys_Quali_verfuegbar 0 "Qualitaetskriterien_nicht_verfuegbar" 1 "Qualitaetskriterien_verfuegbar";
VAL_ 1124 PSD_Sys_Zielfuehrung_geaendert 0 "Zielfuehrung_nicht_geaendert" 1 "Zielfuehrung_geaendert";
VAL_ 1124 PSD_Sys_Geometrieguete_erweitert 0 "Init";
VAL_ 1124 PSD_Attribut_Segment_ID 0 "keine_Segment_Information_vorhanden" 1 "Fehler";
VAL_ 1124 PSD_Attribut_3_ID 0 "keine_Information";
VAL_ 1124 PSD_Attribut_4_ID 0 "keine_Information";
VAL_ 1124 PSD_Attribut_5_ID 0 "keine_Information";
VAL_ 1124 PSD_Attribute_Komplett_06 0 "Attribute_nicht_komplett" 1 "Attribute_komplett";
VAL_ 1124 PSD_Ges_Segment_ID 0 "keine Segmentinformationen vorhanden" 1 "nicht zulaessig";
VAL_ 1124 PSD_Ges_Geschwindigkeit 0 "Kein Geschwindigkeitsgebot" 1 "0 km/h < v_max <  5 km/h" 2 "5 km/h < v_max < 10km/h" 3 "10 km/h < v_max < 15 km/h" 4 "15 km/h < v_max < 20 km/h" 5 "20 km/h < v_max < 25 km/h" 6 "25 km/h < v_max < 30 km/h" 7 "30 km/h < v_max < 35 km/h" 8 "35 km/h < v_max < 40 km/h" 9 "40 km/h < v_max < 45 km/h" 10 "45 km/h < v_max < 50 km/h" 11 "50 km/h < v_max < 60 km/h" 12 "60 km/h < v_max < 70 km/h" 13 "70 km/h < v_max < 80 km/h" 14 "80 km/h < v_max < 90 km/h" 15 "90 km/h < v_max < 100 km/h" 16 "100 km/h < v_max < 110 km/h" 17 "110 km/h < v_max < 120 km/h" 18 "120 km/h < v_max < 130 km/h" 19 "130 km/h < v_max < 140 km/h" 20 "140 km/h < v_max < 150 km/h" 21 "150 km/h < v_max < 160 km/h" 22 "160 km/h < v_max" 23 "Geschwindigkeitsgebot aufgehoben" 24 "..0x1F ungültig";
VAL_ 1124 PSD_Ges_Typ 0 "Geschw_Klasse_des_Kartendatensuppliers" 1 "Explizit_abgeleiteten_Begrenzung" 2 "Durch_Gesetzg_vorgeg_allgem_Gebot_fuer_uebertr_Rahmenbed" 3 "Init";
VAL_ 1124 PSD_Ges_Spur_Geschw_Begrenzung 0 "Gebot_fuer_alle_spuren_gueltig";
VAL_ 1124 PSD_Ges_Geschwindigkeit_Gespann 0 "alle Fahrzeuge" 1 "PKW mit Gespann" 2 "LKW, Busse, etc.";
VAL_ 1124 PSD_Ges_Geschwindigkeit_Witter 0 "Witterungsunabh䮧ig" 1 "N䳳e, Regen, Niederschlag" 2 "Gl䴴e" 3 "Nebel";
VAL_ 1124 PSD_Ges_Geschwindigkeit_Tag_Anf 0 "kein Beginn definiert" 1 "Montag" 2 "Dienstag" 3 "Mittwoch" 4 "Donnerstag" 5 "Freitag" 6 "Samstag" 7 "Sonntag";
VAL_ 1124 PSD_Ges_Geschwindigkeit_Tag_Ende 0 "kein Ende definiert" 1 "Montag" 2 "Dienstag" 3 "Mittwoch" 4 "Donnerstag" 5 "Freitag" 6 "Samstag" 7 "Sonntag";
VAL_ 1124 PSD_Ges_Geschwindigkeit_Std_Anf 25 "kein Beginn für stundenweise Einschr䮫ungen";
VAL_ 1124 PSD_Ges_Geschwindigkeit_Std_Ende 25 "kein Ende für stundenweise Einschr䮫ungen";
VAL_ 1124 PSD_Ges_Ueberholverbot 0 "kein ܢerholverbot" 1 "alle Fahrzeuge" 2 "ܢerholverbot für PKW mit Gespann" 3 "ܢerholverbot für LKW, Busse, etc.";
VAL_ 1124 PSD_Ges_Wechselverkehrszeichen 0 "Kein Wechselverkehrszeichen" 1 "Wechselverkehrszeichen links" 2 "Wechselverkehrszeichen rechts" 3 "Wechselverkehrszeichen links und rechts" 4 "Wechselverkerhszeichen über der Fahrbahn";
VAL_ 1124 PSD_Wechselverkehrszeichen_Typ 0 "kein_Wechselverkehrszeichen" 1 "LED_Wechselverkehrszeichen" 2 "nicht_LED_Wechselverkehrszeichen";
VAL_ 1124 PSD_Ges_Gesetzlich_Kategorie 0 "kein_legales_Verbot" 1 "innerorts" 2 "ausserorts" 3 "Autobahn";
VAL_ 1124 PSD_Ges_Gesetzlich_Zusatz 0 "kein_Zusatz_zu_legalem_Gebot" 1 "Anhaenger_Klasse_1" 2 "Anhaenger_Klasse_2";
VAL_ 1124 PSD_Ges_Verkehrszeichen_Quelle 0 "VZA_kein_Onlinedienst" 1 "nur_VZA" 2 "nur_VZO" 3 "VZA_und_VZO";
VAL_ 1124 PSD_Ges_Attribute_Komplett 0 "Attribute_nicht_komplett" 1 "Attribute_komplett";
VAL_ 1124 PSD_Baum_Laenge_VZ 0 "Ost" 1 "West";
VAL_ 1124 PSD_Baum_Breite_VZ 0 "Nord" 1 "Sued";
VAL_ 1124 PSD_Steigung_1_Segment_ID 0 "keine_Segment_Information_vorhanden" 1 "Fehler";
VAL_ 1124 PSD_Steigung_1_A_Steigung 126 "mehr_als_15_Prozent" 127 "Steigung_unbekannt";
VAL_ 1124 PSD_Steigung_1_A_Vorz 0 "Gefaelle" 1 "Steigung";
VAL_ 1124 PSD_Steigung_1_B_Steigung 126 "mehr_als_15_Prozent" 127 "Steigung_unbekannt";
VAL_ 1124 PSD_Steigung_1_B_Vorz 0 "Gefaelle" 1 "Steigung";
VAL_ 1124 PSD_Steigung_1_Attribute_kompl 0 "Steigungen_nicht_komplett" 1 "Steigungen_komplett";
VAL_ 1124 PSD_Steigung_2_Segment_ID 0 "keine_Segment_Information_vorhanden" 1 "Fehler";
VAL_ 1124 PSD_Steigung_2_Steigung 126 "mehr_als_15_Prozent" 127 "Steigung_unbekannt";
VAL_ 1124 PSD_Steigung_2_Vorz 0 "Gefaelle" 1 "Steigung";
VAL_ 1124 PSD_Steigung_2_Attribute_kompl 0 "Steigungen_nicht_komplett" 1 "Steigungen_komplett";
VAL_ 1153 ZR_LoGeWa_Event_Kombiwarnung 0 "Init" 1 "Unfall" 2 "Traktionsverlust" 3 "Panne" 4 "Sichtbehinderung" 5 "Aquaplaning" 6 "EEBL" 7 "SEF_stat" 8 "SEF_dyn_allgemein" 9 "SEF_dyn_vorne" 10 "SEF_dyn_hinten" 11 "SEF_dyn_links" 12 "SEF_dyn_rechts" 13 "Stauende";
VAL_ 1153 Nav_FoD_Status 0 "Init" 1 "Nav_permanently_available" 2 "FoD_Nav_not_activated" 3 "FoD_Nav_activated" 4 "R4N_Nav_not_activated";
VAL_ 1153 MIB_Tongenerator_PH_verfuegbar 0 "Tongenerator_nicht_verfuegbar" 1 "Tongenerator_vorne_verfuegbar" 2 "Tongenerator_hinten_verfuegbar" 3 "Tongenerator_gesamt_verfuegbar" 4 "Tongenerator_im_AMP";
VAL_ 1153 DSSS_Warning 0 "No_Warning" 1 "Red_traffic_light_guidance" 2 "Stop_sign_warning" 3 "Rear_end_collision_avoidance_warning" 4 "Intersection_collision_avoidance_warning_right" 5 "Intersection_collision_avoidance_warning_left" 6 "turn_right_collision_avoidance" 7 "turn_left_collision_avoidance" 8 "pedestrian_crossing_right" 9 "pedestrian_crossing_left" 10 "bicycle_collision_right" 11 "bicycle_collision_left";
VAL_ 1153 ZR_Kindersicherung_RSE 0 "inaktiv" 1 "aktiv";
VAL_ 1153 ZR_RSE_aktivieren 0 "inaktiv" 1 "aktiv";
VAL_ 1153 MMI_SDS_aktiv 0 "inaktiv" 1 "aktiv";
VAL_ 1153 MU_SecondDisplay 0 "Init" 1 "gueltige_Karte" 2 "ungueltiges_Signal" 3 "Nicht_Verbaut";
VAL_ 1153 MMI_Telefon_aktiv 0 "Telefongespraech_nicht_aktiv" 1 "Telefongespraech_aktiv";
VAL_ 1153 MMI_Gurt_Mic_ref 0 "Downlink_inaktiv" 1 "Downlink_aktiv";
VAL_ 1153 ZR_Sta_Inszenierung 0 "Init" 1 "Inszenierung_deaktiviert" 2 "Inszenierung_Start" 3 "Inszenierung_Stop";
VAL_ 1153 MMI_Gauges_active 0 "gauges_inactive" 1 "gauges_active";
VAL_ 1153 ZR_MXB_Manoever_Ansage 0 "keine_Ansage" 1 "Ansage_ohne_Richtung" 2 "Ansage_rechte_Richtung" 3 "Ansage_linke_Richtung";
VAL_ 1153 ZR_LAPP_Sondermodus_Status 0 "keine_Anforderung" 1 "Sondermodus_aktiv" 2 "Aktivierung_nicht_moeglich";
VAL_ 1153 MMI_StartStopp_Info 0 "Stoppfreigabe" 1 "Stoppverbot" 2 "Startanforderung" 3 "Fehler";
VAL_ 1153 ZR_Parken_Sondermodus 0 "Init" 1 "Sondermodus_aktiv" 2 "Sondermodus_nicht_verfuegbar" 3 "WLAN_aus" 4 "WLAN_auscodiert" 15 "keine_WLAN_HW";
VAL_ 1153 ZR_Rundenbewertung 0 "Bewertung_nicht_aktiv" 1 "langsamer" 2 "gleich_schnell" 3 "schneller" 4 "reserviert" 5 "reserviert" 6 "reserviert" 7 "reserviert" 8 "reserviert" 9 "reserviert" 10 "reserviert" 11 "reserviert" 12 "reserviert" 13 "reserviert" 14 "Init" 15 "Funktion_nicht_verbaut";
VAL_ 1153 ZR_Rundenfortschritt 254 "Init" 255 "Funktion_nicht_verbaut";
VAL_ 1155 Mo_Powermeter_Grenze 4093 "OFF";
VAL_ 1155 MO_Text_Aktivierung_Antrieb 0 "keine_Anzeige" 1 "Ladestecker_nicht_fahrbereit" 2 "erneute_Aktivierung_erforderlich" 3 "Warten_Antrieb_wird_aktiviert" 4 "zum_Fahren_Bremse_und_Fahrstufe" 5 "h2_Tankklappe_nicht_fahrbereit" 6 "zum_Starten_Bremse_treten" 7 "zum_Starten_Kupplung_treten" 15 "Init";
VAL_ 1155 MO_Powermeter_Inszenierung_aktiv 0 "keine_Anzeige" 1 "Inszenierung_aktiv";
VAL_ 1155 MO_Powermeter_Charge_Grenze 1022 "Init" 1023 "Fehler";
VAL_ 1155 MO_Powermeter_Grenze_strategisch 4094 "Init" 4095 "Fehler";
VAL_ 1155 MO_Powermeter_untere_E_Grenze 4094 "Init" 4095 "Fehler";
VAL_ 1155 MO_Powermeter_obere_E_Grenze 4094 "Init" 4095 "Fehler";
VAL_ 1175 PH_Visualisierung 0 "Aus" 1 "Angefragt" 2 "InAnzeige" 3 "Abgefordert" 6 "Init" 7 "Fehler";
VAL_ 1175 PDC_Tonausgabe_Front 0 "kein_Ton" 1 "Intervallton_1" 2 "Intervallton_2" 3 "Intervallton_3" 4 "Intervallton_4" 5 "Intervallton_5" 6 "Dauerton" 7 "Fehlerton" 8 "RCTATon";
VAL_ 1175 PDC_Tonausgabe_Heck 0 "kein_Ton" 1 "Intervallton_1" 2 "Intervallton_2" 3 "Intervallton_3" 4 "Intervallton_4" 5 "Intervallton_5" 6 "Dauerton" 7 "Fehlerton" 8 "Erstwarnton_hinten" 9 "RCTATon";
VAL_ 1175 PH_nachtr_Stopp_Anf 0 "nicht_angefordert" 1 "angefordert";
VAL_ 1175 PH_Abschaltursache 0 "keine, bzw. System aktiv" 1 "Abschaltung durch Herausnahme R-Gang" 2 "Abschaltung ueber Geschwindigkeit" 3 "Abschaltung ueber PDC-Taster" 4 "Abschaltung wegen PLA" 5 "Abschaltung durch KL 15 Bit = 0" 6 "tbd." 7 "Fehler-/gestört Zustand, System noch aktiv";
VAL_ 1175 PH_Opt_Anzeige_V_ein 0 "optische Anzeige vorne nicht aktiv" 1 "optische Anzeige vorne aktiviert";
VAL_ 1175 PH_Opt_Anzeige_H_ein 0 "Optische Anzeige aus" 1 "optische Anzeige hinten aktiviert";
VAL_ 1175 PH_Opt_Anz_V_Hindernis 0 "optische Anzeige vorne meldet kein Hindernis" 1 "optische Anzeige vorne meldet Hindernis im Warnbereich";
VAL_ 1175 PH_Opt_Anz_H_Hindernis 0 "optische Anzeige hinten meldet kein Hindernis" 1 "optische Anzeige hinten meldet Hindernis im Warnbereich";
VAL_ 1175 PH_Tongeber_V_aktiv 0 "Tongeber vorne nicht aktiv" 1 "Tongeber vorne  aktiv";
VAL_ 1175 PH_Tongeber_H_aktiv 0 "Tongeber hinten nicht aktiv" 1 "Tongeber hinten aktiv";
VAL_ 1175 PH_Tongeber_mute 0 "Tongeber nicht stummgeschaltet" 1 "Tongeber stummgeschaltet";
VAL_ 1175 PH_Anf_Audioabsenkung 0 "Keine_Audioabsenkung" 1 "Anforderung_Audioabsenkung";
VAL_ 1175 PH_Tongeber_H_verfuegbar 0 "nicht verfügbar" 1 "verfügbar";
VAL_ 1175 PLA_Anf_Aufschaltung_RVC 0 "Keine_RVC_Aufschalteanf" 1 "RVC_Aufschalteanforderung";
VAL_ 1175 PH_Taster 0 "Taster_nicht_gedrueckt" 1 "Taster_gedrueckt" 2 "reserviert" 3 "Fehler";
VAL_ 1175 PH_Anf_Verdeck 0 "Verdeckbetrieb_freigegeben" 1 "Verdeckbetrieb_sperren" 2 "reserviert" 3 "reserviert";
VAL_ 1175 PH_StartStopp_Info 0 "Motorlauf_nicht_notwendig_(Stoppfreigabe)" 1 "Motoranlauf_nicht_zwingend_notwendig_(Stoppverbot,keine_Startanforderung)" 2 "Motoranlauf_zwingend_notwendig_(Startanforderung)" 3 "Systemfehler";
VAL_ 1175 PH_Stoermeldung 0 "keine_Anzeige_kein_Gong" 1 "Textmeldung_PDC_hinten_gestoert_mit_Gong" 2 "Textmeldung_PDC_hinten_gestoert_ohne_Gong" 3 "Textmeldung_PDC_vorn_gestoert_mit_Gong" 4 "Textmeldung_PDC_vorn_gestoert_ohne_Gong" 5 "Textmeldung_PDC_gestoert_mit_Gong" 6 "Textmeldung_PDC_gestoert_ohne_Gong" 7 "Textmeldung_PDC_seitlich_gestoert_mit_Gong" 8 "Textmeldung_PDC_seitlich_gestoert_ohne_Gong";
VAL_ 1175 PH_defekt 0 "PH aktiv" 1 "PH wurde aufgrund eines Defektes deaktiviert";
VAL_ 1175 PH_gestoert 0 "PH aktiv" 1 "PH wurde auf Grund einer Stoerung tempraer deaktiviert";
VAL_ 1175 PH_Systemzustand 0 "Anlage aus" 1 "Anlage durch einlegen R-Gang aktiviert" 2 "Anlage manuell durch Taster aktiviert" 3 "Anlage automatisch aktiviert" 4 "Anlage durch ARA aktiviert" 6 "Init - Initialisierungsphase nach Kl. 15 ein / Reset" 7 "Fehler-/gestört Zustand, System noch aktiv";
VAL_ 1175 PH_Display_Kundenwunsch 0 "Anzeige aus" 1 "Grafik" 2 "Rear View" 3 "automatisch";
VAL_ 1283 HVK_Istmodus_Anf 0 "nicht_angefordert" 1 "angefordert";
VAL_ 1283 HVK_TN1_Sollmodus 0 "HV_Off" 1 "HV_On" 2 "reserviert" 3 "Initialisierung";
VAL_ 1283 HVK_MO_EmSollzustand 0 "HvOff" 1 "HvStbyReq" 2 "HvStbyWait" 3 "HvBattOnReq" 4 "HvBattOnWait" 10 "HvOnIdle" 18 "HvOnDrvReq" 19 "HvOnDrvWait" 20 "HvOnDrvRdy" 28 "HvStepUpReq" 29 "HvStepUpWait" 30 "HvStepUp" 38 "HvStepDownReq" 39 "HvStepDownWait" 40 "HvStepDown" 46 "HvAcChPreReq" 47 "HvAcChPreWait" 48 "HvAcChReq" 49 "HvAcChWait" 50 "HvAcCh" 56 "HvDcChPreReq" 57 "HvDcChPreWait" 58 "HvDcChReq" 59 "HvDcChWait" 60 "HvDcCh" 67 "HvChOffReq" 68 "HvChOffWait" 69 "HvOnIdleReq" 70 "HvOnIdleWait" 96 "HvCpntOffReq" 97 "HvCpntOffWait" 98 "HvBattOffReq" 99 "HvBattOffWait" 109 "HvDcDcFailOffReq" 110 "HvDcDcFail" 119 "HvElmOffReq" 120 "HvElmOff" 126 "HvFailCpntOffReq" 127 "HvFailCpntOffWait" 128 "HvFailBattOffReq" 129 "HvFailBattOffWait" 130 "HvFailBattOff" 138 "HvFailUCtlReq" 139 "HvFailUCtlWait" 140 "HvFailUCtl" 150 "HvEmgcyOff" 255 "Init";
VAL_ 1283 HVK_BMS_Sollmodus 0 "HV_Off" 1 "HV_On" 3 "AC_Laden_erw" 4 "AC_Laden" 6 "DC_Laden" 7 "Init";
VAL_ 1283 HVK_DCDC_Sollmodus 0 "Standby" 1 "HV_On_Vorladen" 2 "Tiefsetzen" 3 "Hochsetzen" 4 "Pruefpuls_12V" 7 "Initialisierung";
VAL_ 1283 HVK_EKK_Sollmodus 0 "Keine_Freigabe" 1 "Freigabe" 2 "Freigabe_ausgesetzt" 7 "Init";
VAL_ 1283 HVK_HVPTC_Sollmodus 0 "Keine_Freigabe" 1 "Freigabe" 2 "Freigabe_ausgesetzt" 7 "Init";
VAL_ 1283 HVK_HVLM_Sollmodus 0 "keine_Freigabe" 1 "Freigabe_Lademanager" 2 "Vorladung_AC_Pfad" 7 "Init";
VAL_ 1283 HVK_HV_Netz_Warnungen 0 "Keine_Warnung" 1 "Warntext_HV_Netz_Anf" 2 "Fehlertext_HV_Netz_Anf" 3 "Warnung_Kein_Wiederstart_moeglich";
VAL_ 1283 HV_Bordnetz_aktiv 0 "inaktiv" 1 "aktiv";
VAL_ 1283 HV_Bordnetz_Fehler 0 "kein_Fehler" 1 "Fehler";
VAL_ 1283 HVK_Gesamtst_Spgfreiheit 0 "Funktion_Init__ohne_Funktion" 1 "HV_System_spannungsfrei" 2 "HV_System_nicht_spannungsfrei" 3 "Fehler";
VAL_ 1283 HVK_AktiveEntladung_Anf 0 "nicht_angefordert" 1 "angefordert";
VAL_ 1283 HVK_Iso_Messung_Start 0 "keine_Messung" 1 "Messung_HV_Netz_1" 2 "Messung_HV_Netz_2" 4 "deaktiviert";
VAL_ 1283 HVK_DCDC_EKK_Sollmodus 0 "aus" 1 "ein" 2 "reserviert" 3 "Init";
VAL_ 1312 LoGeWa_Event_Kombiwarnung 0 "Init" 1 "Unfall" 2 "Traktionsverlust" 3 "Panne" 4 "Sichtbehinderung" 5 "Aquaplaning";
VAL_ 1312 AB_Anforderung_eCall 0 "keine_Anforderung" 1 "Anforderung";
VAL_ 1312 AB_Anprall_Seite_Beifahrer 0 "kein_Anprall" 1 "Anprall_erkannt";
VAL_ 1312 AB_Anprall_Rollover 0 "kein_Anprall" 1 "Anprall_erkannt";
VAL_ 1312 AB_Anprall_FGS 0 "kein_Anprall" 1 "Anprall_erkannt";
VAL_ 1312 AB_Anprall_Front_Beifahrer 0 "kein_Anprall" 1 "Anprall_erkannt";
VAL_ 1312 AB_Anprall_Front_Fahrer 0 "kein_Anprall" 1 "Anprall_erkannt";
VAL_ 1312 AB_Anprall_Heck_Beifahrer 0 "kein_Anprall" 1 "Anprall_erkannt";
VAL_ 1312 AB_Anprall_Heck_Fahrer 0 "kein_Anprall" 1 "Anprall_erkannt";
VAL_ 1312 AB_Wickelklappung_Reihe2_MI 0 "nicht_verbaut" 1 "nicht_verfuegbar__Fehler_oder_Init" 2 "nicht_verriegelt" 3 "verriegelt";
VAL_ 1312 AB_Belegung_VB 0 "nicht_verfuegbar" 1 "Fehler" 2 "nicht_belegt" 3 "belegt";
VAL_ 1312 AB_Abschaltanf_SIH_BF 0 "Normalbetrieb" 1 "Abschaltung_angefordert";
VAL_ 1312 AB_Anprall_Seite_Fahrer 0 "kein_Anprall" 1 "Anprall_erkannt";
VAL_ 1312 SC_PAO_Schriftzug_Anf 0 "LED aus" 1 "LED an" 2 "LED blinken" 3 "reserviert";
VAL_ 1312 SC_PAO_ON_Anf 0 "LED aus" 1 "LED an" 2 "LED blinken" 3 "reserviert";
VAL_ 1312 SC_PAO_OFF_Anf 0 "LED aus" 1 "LED an" 2 "LED blinken" 3 "reserviert";
VAL_ 1312 AB_Crashschwere 0 "kein_Ereignis" 1 "Crashschwere_1" 2 "Crashschwere_2" 3 "Crashschwere_3" 4 "Crashschwere_4" 5 "Crashschwere_5" 6 "Crashschwere_2_bis_5" 7 "Fehler";
VAL_ 1312 AB_Anforderung_USM 0 "keine_Anforderung" 1 "Anforderung";
VAL_ 1312 AB_Gurtschloss_FA 0 "nicht_verbaut" 1 "nicht_verfügbar (Fehler oder Init)" 2 "nicht_gesteckt" 3 "gesteckt";
VAL_ 1312 AB_Gurtschloss_BF 0 "nicht_verbaut" 1 "nicht_verfügbar (Fehler oder Init)" 2 "nicht_gesteckt" 3 "gesteckt";
VAL_ 1312 AB_Gurtschloss_Reihe2_FA 0 "nicht_verbaut" 1 "nicht_verfügbar (Fehler oder Init)" 2 "nicht_gesteckt" 3 "gesteckt";
VAL_ 1312 AB_Gurtschloss_Reihe2_MI 0 "nicht_verbaut" 1 "nicht_verfügbar (Fehler oder Init)" 2 "nicht_gesteckt" 3 "gesteckt";
VAL_ 1312 AB_Gurtschloss_Reihe2_BF 0 "nicht_verbaut" 1 "nicht_verfügbar (Fehler oder Init)" 2 "nicht_gesteckt" 3 "gesteckt";
VAL_ 1312 AB_Gurtschloss_Reihe3_FA 0 "nicht_verbaut" 1 "nicht_verfügbar (Fehler oder Init)" 2 "nicht_gesteckt" 3 "gesteckt";
VAL_ 1312 AB_Gurtschloss_Reihe3_MI 0 "nicht_verbaut" 1 "nicht_verfügbar (Fehler oder Init)" 2 "nicht_gesteckt" 3 "gesteckt";
VAL_ 1312 AB_Gurtschloss_Reihe3_BF 0 "nicht_verbaut" 1 "nicht_verfügbar (Fehler oder Init)" 2 "nicht_gesteckt" 3 "gesteckt";
VAL_ 1312 AB_Sitzpos_Sens_FA 0 "nicht verfügbar" 1 "Fehler" 2 "Sitz nicht vorne" 3 "Sitz vorne";
VAL_ 1312 AB_Sitzpos_Sens_BF 0 "nicht verfügbar" 1 "Fehler" 2 "Sitz nicht vorne" 3 "Sitz vorne";
VAL_ 1312 AB_Wickelklappung_Reihe2_BF 0 "nicht_verbaut" 1 "nicht_verfuegbar__Fehler_oder_Init" 2 "nicht_verriegelt" 3 "verriegelt";
VAL_ 1312 AB_Wickelklappung_Reihe2_FA 0 "nicht_verbaut" 1 "nicht_verfuegbar__Fehler_oder_Init" 2 "nicht_verriegelt" 3 "verriegelt";
VAL_ 1349 AB_Gurtwarn_Reihe2_FA 0 "nicht_verbaut" 1 "keine_Gurtwarnung_Sitz_leer" 2 "keine_Gurtwarnung_Sitz_belegt" 3 "Gurtwarnung_Sitz_belegt";
VAL_ 1349 AB_Gurtwarn_Reihe2_BF 0 "nicht_verbaut" 1 "keine_Gurtwarnung_Sitz_leer" 2 "keine_Gurtwarnung_Sitz_belegt" 3 "Gurtwarnung_Sitz_belegt";
VAL_ 1349 AbstWarn_MV_FAS_Fkt_Status 0 "Init" 1 "Funktion_Ist_Ein" 2 "Funktion_Ist_Aus" 3 "Fehler";
VAL_ 1349 WarnBrems_Charisma_Status 0 "Init" 1 "verfügbar" 2 "nicht verfügbar" 3 "asynchron durch Fahrerwunsch";
VAL_ 1349 WarnBrems_Charisma_FahrPr 0 "keine_Funktion" 1 "Programm_1" 2 "Programm_2" 3 "Programm_3" 4 "Programm_4" 5 "Programm_5" 6 "Programm_6" 7 "Programm_7" 8 "Programm_8" 9 "Programm_9" 10 "Programm_10" 11 "Programm_11" 12 "Programm_12" 13 "Programm_13" 14 "Programm_14" 15 "Programm_15";
VAL_ 1349 AB_Gurtwarn_Reihe2_MI 0 "nicht_verbaut" 1 "keine_Gurtwarnung_Sitz_leer" 2 "keine_Gurtwarnung_Sitz_belegt" 3 "Gurtwarnung_Sitz_belegt";
VAL_ 1349 AB_Gurtwarn_Reihe3_FA 0 "nicht_verbaut" 1 "keine_Gurtwarnung_Sitz_leer" 2 "keine_Gurtwarnung_Sitz_belegt" 3 "Gurtwarnung_Sitz_belegt";
VAL_ 1349 AB_Gurtwarn_Reihe3_MI 0 "nicht_verbaut" 1 "keine_Gurtwarnung_Sitz_leer" 2 "keine_Gurtwarnung_Sitz_belegt" 3 "Gurtwarnung_Sitz_belegt";
VAL_ 1349 AB_Gurtwarn_Reihe3_BF 0 "nicht_verbaut" 1 "keine_Gurtwarnung_Sitz_leer" 2 "keine_Gurtwarnung_Sitz_belegt" 3 "Gurtwarnung_Sitz_belegt";
VAL_ 1349 LGI_FAS_Fkt_Status 0 "Init" 1 "Funktion_Ist_Ein" 2 "Funktion_Ist_Aus" 3 "Fehler";
VAL_ 1349 PreCrash_FAS_Fkt_Status 0 "Init" 1 "Funktion_Ist_Ein" 2 "Funktion_Ist_Aus" 3 "Fehler";
VAL_ 1349 AB_SBR_hinten_verbau 0 "ohne_SBR_hinten" 1 "mit_SBR_hinten" 2 "nicht_definiert" 3 "Init";
VAL_ 1349 AWV_Einstellung_System_ASG 0 "deaktiviert" 1 "aktiviert";
VAL_ 1349 AWV_Einstellung_Warnung_ASG 0 "Aus" 1 "Setting_2" 2 "Setting_3" 3 "Setting_4" 4 "Setting_5" 5 "Ein";
VAL_ 1349 SC_PreSense_Modus_Warnung_NV 0 "Aus" 1 "Setting_2" 2 "Setting_3" 3 "Setting_4" 4 "Setting_5" 5 "Ein";
VAL_ 1349 SC_PreSense_Modus_Warnung_MV 0 "Aus" 1 "Setting_2" 2 "Setting_3" 3 "Setting_4" 4 "Setting_5" 5 "Ein";
VAL_ 1349 SC_PreSense_Modus_System_MV 0 "deaktiviert" 1 "aktiviert";
VAL_ 1349 SC_PreSense_Modus_System_NV 0 "deaktiviert" 1 "aktiviert";
VAL_ 1349 SC_PreSense_Modus_System_KAS 0 "deaktiviert" 1 "aktiviert";
VAL_ 1355 PH_Verschmutzungsmeldung 0 "keine_Anzeige_kein_Gong" 1 "Textmeldung_PDC_hinten_verschmutzt_mit_Gong" 2 "Textmeldung_PDC_hinten_verschmutzt_ohne_Gong" 3 "Textmeldung_PDC_vorn_verschmutzt_mit_Gong" 4 "Textmeldung_PDC_vorn_verschmutzt_ohne_Gong" 5 "Textmeldung_PDC_verschmutzt_mit_Gong" 6 "Textmeldung_PDC_verschmutzt_ohne_Gong" 7 "Textmeldung_PDC_seitlich_verschmutzt_mit_Gong" 8 "Textmeldung_PDC_seitlich_verschmutzt_ohne_Gong";
VAL_ 1355 PH_Aufschaltursache 0 "Anlage aus" 1 "Anlage durch einlegen R-Gang aktiviert" 2 "Anlage manuell durch Taster aktiviert" 3 "Anlage automatisch aktiviert" 4 "Anlage durch ARA aktiviert" 5 "Rueckwaertsrollen" 6 "Anlage_durch_PLA_aktiviert" 7 "Anlage_durch_IPA_aktiviert" 8 "Anlage_durch_FA_aktiviert" 9 "Anlage_durch_RBF_oder_MA_aktiviert" 10 "Anlage_durch_Smartphone_aktiviert" 11 "Anlage_durch_Jokertaste_aktiviert" 12 "Anlage_durch_Favoritentasten_aktiviert" 13 "Anlage_durch_SideViewTaster_aktiviert" 14 "Anlage_durch_RCTA_aktiviert" 15 "Anlage_durch_KAS_aktiviert" 16 "Anlage_durch_AWC_aktiviert" 30 "Init_Initialisierungsphase_nach_Kl_15_ein_oder_Reset" 31 "Fehler_gestoerter_Zustand_System_noch_aktiv";
VAL_ 1355 PH_Ton_Ausgabe 0 "Init" 1 "Intervallton_vorne" 2 "Intervallton_hinten" 3 "Dauerton_vorne" 4 "Dauerton_hinten" 5 "Quittierungston" 6 "Reserviert" 7 "Fehler";
VAL_ 1355 PH_Ton_Pausenlaenge 0 "Init" 1 "Pause_5ms" 2 "Pause_10ms" 3 "Pause_15ms" 100 "Pause_500ms" 101 "Reserviert" 126 "Reserviert" 127 "Fehler";
VAL_ 1355 PH_Ton_Richtung 0 "vorne" 1 "vorne_rechts" 2 "rechts" 3 "rechts_hinten" 4 "hinten" 5 "hinten_links" 6 "links" 7 "vorne_links";
VAL_ 1355 PH_Ton_Lautstaerke 0 "Minimallautstaerke" 1 "Lautstaerke_1" 2 "Lautstaerke_2" 3 "Lautstaerke_3" 4 "Lautstaerke_4" 5 "Lautstaerke_5" 6 "Lautstaerke_6" 7 "Maximallautstaerke";
VAL_ 1355 BCM_WAH_Meldung 0 "Init" 1 "Fehlermeldung_bei_Nichtverfuegbarkeit_mit_Gong" 2 "Fehlermeldung_bei_Nichtverfuegbarkeit_ohne_Gong" 3 "Anzeige_dass_Fahrzeug_erkannt_wurde_und_Funktion_aktiv_ist" 4 "Wiederanfahrhinweis_mit_Gong" 5 "Wiederanfahrhinweis_ohne_Gong";
VAL_ 1355 PDC_Charisma_Status 0 "Init" 1 "verfuegbar" 2 "nicht_verfuegbar" 3 "asynchron_durch_Fahrerwunsch";
VAL_ 1355 PDC_Charisma_FahrPr 0 "keine_Funktion" 1 "Programm_1" 2 "Programm_2" 3 "Programm_3" 4 "Programm_4" 5 "Programm_5" 6 "Programm_6" 7 "Programm_7" 8 "Programm_8" 9 "Programm_9" 10 "Programm_10" 11 "Programm_11" 12 "Programm_12" 13 "Programm_13" 14 "Programm_14" 15 "Programm_15";
VAL_ 1361 WFS_Schluessel_Fahrberecht 0 "kein authorisierter Schluessel erkannt" 1 "aktive_Funkschluessel_Nr_01" 2 "aktive_Funkschluessel_Nr_02" 3 "aktive_Funkschluessel_Nr_03" 4 "aktive_Funkschluessel_Nr_04" 5 "aktive_Funkschluessel_Nr_05" 6 "aktive_Funkschluessel_Nr_06" 7 "aktive_Funkschluessel_Nr_07" 8 "aktive_Funkschluessel_Nr_08" 9 "ungueltig_09" 10 "ungueltig_10" 11 "ungueltig_11" 12 "ungueltig_12" 13 "ungueltig_13" 14 "ungueltig_14" 15 "digitaler_Schluessel_aktiv";
VAL_ 1361 WFS_ID_Geb_autorisiert 0 "Schluessel_nicht_authorisiert" 1 "Schluessel authorisiert";
VAL_ 1361 WFS_ID_Geb_autorisiert_in_Kl15 0 "nicht_authorisiert_in_Kl15" 1 "authorisiert_in_Kl15";
VAL_ 1361 WFS_ID_Geb_steckt 0 "kein_Schluessel_im_Zuendschloss" 1 "Schluessel steckt im Zuendschloss";
VAL_ 1361 WFS_Schluessel_Soll 0 "Init";
VAL_ 1361 WFS_Schluessel_Ist 0 "Init";
VAL_ 1361 WFS_Safe 0 "Init" 1 "WFS nicht deaktiviert";
VAL_ 1361 WFS_LZ 0 "nicht def." 1 "LZ 1" 2 "LZ 2" 3 "LZ 3";
VAL_ 1361 WFS_ELV_authorisiert 0 "ELV_nicht_authorisiert" 1 "ELV_authorisiert";
VAL_ 1361 WFS_LF_Aktiv 0 "Funktempfang_nicht_aktiv" 1 "LF_Funkempfang_aktiv";
VAL_ 1361 WFS_Betrieb_Lesespule 0 "keine_Schluesselkomm_Lesespule" 1 "Schluesselkomm_Lesespule";
VAL_ 1361 WFS_Klemmenfreigabe 0 "keine_Freigabe" 1 "Freigabe";
VAL_ 1361 WFS_Fahrerhinweise 0 "Keine_Anzeigeanforderung" 1 "Schuessel_Auth_niO" 2 "Notlauf_aktiv" 3 "Schluessel_Kessy_nicht_gefunden";
VAL_ 1361 WFS_Parken_Status 0 "Limitierung_inaktiv" 1 "Limitierung_aktiv" 2 "Abbruch";
VAL_ 1411 BCM_FH_Freigabe 1 "Funktionsfreigabe Fensterheber";
VAL_ 1411 BCM_Komfortfkt_Freigabe 0 "Komfortfunktion gesperrt" 1 "globale Freigabe der Komfortfunktion erteilt";
VAL_ 1411 BCM_HSK_Freigabe 0 "erlauben" 1 "sperren";
VAL_ 1411 BCM_Verdeck_Freigabe 0 "Verdeckbetrieb nicht erlaubt" 1 "Verdeckbetrieb erlaubt";
VAL_ 1411 ZV_verriegelt_intern_ist 1 "Fahrzeug innen verriegelt; Istzustand";
VAL_ 1411 ZV_verriegelt_extern_ist 1 "Fahrzeug_aussen_verriegelt_Istzustand";
VAL_ 1411 ZV_verriegelt_intern_soll 1 "Fahrzeug verriegelt intern; Sollzusstand";
VAL_ 1411 ZV_verriegelt_extern_soll 1 "Fahrzeug verriegelt extern; Sollzusstand";
VAL_ 1411 ZV_gesafet_extern_ist 1 "Fahrzeug aussen gesafet; Istzustand";
VAL_ 1411 ZV_gesafet_extern_soll 1 "Fahrzeug_aussen_gesafet_Sollzustand";
VAL_ 1411 ZV_Einzeltuerentriegelung 1 "Fahrzeug an Einzeltuer entriegelt";
VAL_ 1411 ZV_Heckeinzelentriegelung 1 "Heckdeckeleinzelentriegelung";
VAL_ 1411 ZV_FT_offen 0 "FT_geschlossen" 1 "FT_geoeffnet";
VAL_ 1411 ZV_BT_offen 0 "BT_geschlossen" 1 "BT_geoeffnet";
VAL_ 1411 ZV_HFS_offen 0 "geschlossen" 1 "offen";
VAL_ 1411 ZV_HBFS_offen 0 "geschlossen" 1 "offen";
VAL_ 1411 ZV_HD_offen 1 "Heckdeckel_auf";
VAL_ 1411 ZV_HS_offen 0 "Heckscheibe_geschlossen" 1 "Heckscheibe auf";
VAL_ 1411 IRUE_aktiv 0 "unscharf" 1 "scharf";
VAL_ 1411 DWA_aktiv 0 "unscharf" 1 "scharf";
VAL_ 1411 HD_Hauptraste 0 "geschlossen" 1 "offen";
VAL_ 1411 HD_Vorraste 0 "geschlossen" 1 "offen";
VAL_ 1411 FFB_CarFinder 0 "nicht aktiv" 1 "aktiv";
VAL_ 1411 FFB_Komfortoeffnen 0 "kein_Komfortoeffnen_empfangen" 1 "Komfortoeffnen ueber Funk empfangen";
VAL_ 1411 FFB_Komfortschliessen 0 "kein_Komfortschliessen_empfangen" 1 "Komfortschliessen ueber Funk empfangen";
VAL_ 1411 ZV_Schluessel_Zugang 0 "kein_auth_Schluessel_erkannt" 1 "aktive_Funkschluessel_Nr_01" 2 "aktive_Funkschluessel_Nr_02" 3 "aktive_Funkschluessel_Nr_03" 4 "aktive_Funkschluessel_Nr_04" 5 "aktive_Funkschluessel_Nr_05" 6 "aktive_Funkschluessel_Nr_06" 7 "aktive_Funkschluessel_Nr_07" 8 "aktive_Funkschluessel_Nr_08" 9 "ungueltig_09" 10 "ungueltig_10" 11 "ungueltig_11" 12 "ungueltig_12" 13 "ungueltig_13" 14 "ungueltig_14" 15 "ungueltig_15";
VAL_ 1411 ZV_SafeFunktion_aktiv 0 "inaktiv" 1 "aktiv";
VAL_ 1411 FBS_Warn_Schluessel_Batt 0 "i.O." 1 "defekt";
VAL_ 1411 ZV_Oeffnungsmodus 0 "globale_Oeffnung" 1 "ZV_mit_Einzeltuerentr" 2 "ZV_individuell_selektiv" 3 "ZV_seitenselektiv";
VAL_ 1411 HFS_verriegelt 0 "nicht_verriegelt" 1 "verriegelt";
VAL_ 1411 HFS_gesafet 0 "nicht_gesafet" 1 "gesafet";
VAL_ 1411 HBFS_verriegelt 0 "nicht_verriegelt" 1 "verriegelt";
VAL_ 1411 HBFS_gesafet 0 "nicht_gesafet" 1 "gesafet";
VAL_ 1411 ZV_ist_Zustand_verfuegbar 0 "nicht_verfuegbar" 1 "verfuegbar_alle_TSGs_am_Bus";
VAL_ 1411 IRUE_Taster_Fkts_LED 0 "LED_aus" 1 "LED_ein";
VAL_ 1411 ZV_Tankklappe_offen 0 "Tankklappe_geschlossen" 1 "Tankklappe_offen";
VAL_ 1411 ZV_Rollo_auf 0 "inaktiv" 1 "aktiv";
VAL_ 1411 ZV_Rollo_zu 0 "inaktiv" 1 "aktiv";
VAL_ 1411 ZV_SAD_auf 0 "inaktiv" 1 "aktiv";
VAL_ 1411 ZV_SAD_zu 0 "inaktiv" 1 "aktiv";
VAL_ 1411 BCM_Tankklappensteller_Fehler 0 "kein_Fehler" 1 "Fehler";
VAL_ 1411 ZV_verriegelt_soll 0 "Init" 1 "nicht_verriegelt" 2 "verriegelt";
VAL_ 1413 SI_Sammel_SG_Fehler 61 "Reserviert" 62 "Overflow" 63 "ungueltig";
VAL_ 1413 SI_Diagnose_Aktiv 0 "inaktiv" 1 "aktiv";
VAL_ 1413 SI_QRS_Mode 0 "QRS_Messmodus_nicht_aktiv" 1 "QRS_Messmodus_aktiv";
VAL_ 1413 SI_T_Mode 0 "Transportmodus_nicht_aktiv" 1 "Transportmodus_aktiv";
VAL_ 1413 SI_NWDF 0 "Ueberwachung_nicht_freigegeben" 1 "Ueberwachung_freigegeben";
VAL_ 1413 SI_NWDF_gueltig 0 "NWDF_wird_nicht_unterstuetzt" 1 "NWDF_wird_unterstuetzt";
VAL_ 1413 SI_Sammelfehler 0 "kein_Sammelfehler" 1 "Sammelfehler";
VAL_ 1413 GW_KD_Fehler 0 "kein_KD_Fehler" 1 "KD_Fehler";
VAL_ 1413 SI_T_Schutz 0 "Transportschutz_nicht_aktiv" 1 "Transportschutz_aktiv";
VAL_ 1413 SI_BUS_01 0 "keine_Busruhe" 1 "Busruhe";
VAL_ 1413 SI_BUS_02 0 "keine_Busruhe" 1 "Busruhe";
VAL_ 1413 SI_BUS_03 0 "keine_Busruhe" 1 "Busruhe";
VAL_ 1413 SI_BUS_04 0 "keine_Busruhe" 1 "Busruhe";
VAL_ 1413 SI_BUS_05 0 "keine_Busruhe" 1 "Busruhe";
VAL_ 1413 SI_BUS_06 0 "keine_Busruhe" 1 "Busruhe";
VAL_ 1413 SI_BUS_07 0 "keine_Busruhe" 1 "Busruhe";
VAL_ 1413 SI_BUS_08 0 "keine_Busruhe" 1 "Busruhe";
VAL_ 1413 SI_BUS_09 0 "keine_Busruhe" 1 "Busruhe";
VAL_ 1413 SI_BUS_10 0 "keine_Busruhe" 1 "Busruhe";
VAL_ 1413 SI_BUS_11 0 "keine_Busruhe" 1 "Busruhe";
VAL_ 1413 SI_BUS_12 0 "keine_Busruhe" 1 "Busruhe";
VAL_ 1413 SI_BUS_13 0 "keine_Busruhe" 1 "Busruhe";
VAL_ 1413 SI_BUS_14 0 "keine_Busruhe" 1 "Busruhe";
VAL_ 1413 SI_BUS_15 0 "keine_Busruhe" 1 "Busruhe";
VAL_ 1413 SI_Bus_Identifikation 16 "CAN_Diagnose" 17 "CAN_Antrieb" 18 "CAN_Komfort" 19 "CAN_Infotainment" 20 "CAN_Fahrwerk" 21 "CAN_Extended" 22 "CAN_Hybrid" 23 "CAN_Lade" 24 "CAN_Kombi" 25 "CAN_Komfort_2" 26 "CAN_AFS" 33 "CAN_FahrerAssistenzSysteme" 34 "CAN_Migration" 35 "CAN_Connect" 36 "CAN_AnzeigeBedienung" 37 "CAN_ElectricalVehicle" 40 "CAN_Telematik" 41 "CAN_MFL" 42 "CAN_FahrerAssistenzSysteme_2" 48 "FlexRay_A" 49 "FlexRay_B" 97 "VLAN_FAS" 98 "VLAN_Infotainment" 99 "VLAN_Connect" 100 "VLAN_Komfort" 101 "VLAN_Antrieb" 102 "VLAN_Diagnose" 103 "VLAN_Internet" 104 "VLAN_Gateway" 105 "VLAN_Remote_FC" 106 "VLAN_Connect_2" 107 "VLAN_Licht" 108 "VLAN_Charge" 109 "VLAN_Cockpit" 176 "HCP1_CANFD01" 177 "HCP1_CANFD02" 178 "HCP1_CANFD03" 179 "HCP1_CANFD04" 180 "HCP1_CANFD05" 181 "HCP1_CANFD06" 182 "HCP1_CANFD07" 183 "HCP1_CANFD08" 186 "HCP4_CANFD03" 187 "HCP4_CANFD04" 188 "HCP1_CANFD09" 189 "HCP4_CANFD06" 190 "HCP4_CANFD07" 191 "HCP4_CANFD08" 192 "HCP4_CANFD09" 193 "HCP4_CANFD10" 194 "HCP1_CANFD10" 195 "ICAS1_CANFD2_HCP5_CANFD02" 196 "HCP1_CANFD11" 197 "WU_HCP1_CANFD" 198 "WU_HCP2_1_CANFD" 199 "WU_HCP_2_CANFD" 200 "WU_HCP_3_CANFD" 201 "WU_HCP4_CANFD" 202 "WU_HCP3_CANFD02" 204 "ESC_CANFD" 205 "HCP4_CANFD11" 206 "HCP4_CANFD12" 207 "HCP5_CANFD04" 208 "HCP5_CANFD05" 212 "WU_ConMod_CANFD" 213 "WU_PASD_CANFD";
VAL_ 1413 SI_CAB 0 "inaktiv" 1 "CAB_01__Tueren" 2 "CAB_02__Anhaenger" 4 "CAB_03__Nightvision" 8 "CAB_04__Sitzverstellung" 16 "CAB_05__Klappen" 32 "CAB_06__Infotainment" 64 "CAB_07__Sub_Infotainment" 128 "CAB_08__Anzeige" 256 "CAB_09__Laden" 512 "CAB_10__Klima" 1024 "CAB_11__FlexRay" 262144 "CAB_19_VLAN_Remote_FC" 524288 "CAB_20_VLAN_Komfort";
VAL_ 1420 KST_Txt_P_Gang 0 "Aus" 1 "Ein";
VAL_ 1420 KST_Txt_Panikabschaltung 0 "Aus" 1 "Ein";
VAL_ 1420 KST_Anf_Klemmenfreigabe_ELV 0 "nicht_angefordert" 1 "angefordert";
VAL_ 1420 KST_Txt_Komfortabschaltung 0 "inaktiv" 1 "aktiv";
VAL_ 1420 KST_ZAT_betaetigt 0 "Aus" 1 "Ein";
VAL_ 1420 KST_Unterdr_Zuendungsmeldung 0 "keine_Unterdr_der_Zuendungsmeldung" 1 "Unterdr_der_Zuendungsmeldung_aktiv";
VAL_ 1420 KST_aut_Abschaltung_Zuendung 0 "Zuendung_wird_bei_Verl_nicht_deaktiviert" 1 "Zuendung_wird_bei_Verl_deaktiviert";
VAL_ 1420 KST_Anf_ZV_Verriegelung 0 "inaktiv" 1 "aktiv";
VAL_ 1420 Relais_VoKo_angesteuert 0 "nicht_angesteuert" 1 "angesteuert";
VAL_ 1420 RSt_Anforderung_HMS 0 "keine_Anforderung" 1 "halten" 2 "parken" 3 "halten_Standby" 4 "anfahren" 5 "Loesen_ueber_Rampe" 6 "Parken_mit_P";
VAL_ 1440 LS_Helligkeit_IR 254 "Init" 255 "Fehler";
VAL_ 1440 LS_Helligkeit_FW 1022 "Init" 1023 "Fehler";
VAL_ 1440 LS_defekt 0 "OK" 1 "defekt";
VAL_ 1440 LS_Verbau 0 "Init" 1 "Lichtsensor_verbaut";
VAL_ 1440 RS_Regenmenge 14 "Init" 15 "Fehler";
VAL_ 1440 RS_Verbau 0 "Init" 1 "Regensensor verbaut";
VAL_ 1440 RS_Verglasung_schliessen 0 "Verglasung nicht schliessen" 1 "Verglasung schliessen";
VAL_ 1440 RS_defekt 0 "OK" 1 "defekt";
VAL_ 1440 RS_Wischergeschwindigkeit 0 "kein Wischen" 1 "42 Huebe/min" 2 "45 Huebe/min" 3 "48 Huebe/min" 4 "51 Huebe/min" 5 "54 Huebe/min" 6 "57 Huebe/min" 7 "60 Huebe/min";
VAL_ 1440 RLS_Vorfeldhelligkeit_Boost 0 "groesser_24413_Lux" 1 "bis_24413_Lux" 2 "bis_22193_Lux" 3 "bis_20176_Lux" 4 "bis_18342_Lux" 5 "bis_16647_Lux" 6 "bis_15158_Lux" 7 "bis_13780_Lux" 8 "bis_12527_Lux" 9 "bis_11388_Lux" 10 "bis_10353_Lux" 11 "bis_9412_Lux" 12 "bis_8556_Lux" 13 "bis_7778_Lux" 14 "bis_7071_Lux" 15 "bis_6428_Lux";
VAL_ 1442 BMS_Status_ServiceDisconnect 0 "gesteckt" 1 "gezogen";
VAL_ 1442 BMS_Status_Spgfreiheit 0 "Init" 1 "HV_Komponente_spannungsfrei" 2 "HV_Komp_nicht_spannungsfrei" 3 "Fehler_nicht_spannungsfrei";
VAL_ 1442 BMS_OBD_Lampe_Anf 0 "kein_MIL_Request" 1 "MIL_Request";
VAL_ 1442 BMS_IstModus 0 "HV_inaktiv" 1 "Fahren_HV_aktiv" 2 "stBalancing" 3 "externes_Laden" 4 "AC_Laden" 5 "Error_Batt" 6 "DC_Laden" 7 "Init";
VAL_ 1442 BMS_Fehlerstatus 0 "Komponente_IO" 1 "Eingeschr_KompFkt_Isofehler_I" 2 "Eingeschr_KompFkt_Isofehler_II" 3 "Eingeschr_KompFkt_Interlock" 4 "Eingeschr_KompFkt_SD" 5 "Eingeschr_KompFkt_Leistungsred" 6 "Keine_Komponentenfunktion" 7 "Init";
VAL_ 1442 BMS_Kapazitaet_02 2047 "Init";
VAL_ 1442 BMS_Soll_SOC_HiRes 2046 "Init" 2047 "Fehler";
VAL_ 1447 TM_Spiegel_Anklappen 0 "Init" 1 "Spiegel_anklappen";
VAL_ 1447 TM_Nur_Hupen 0 "inaktiv" 1 "aktiv";
VAL_ 1447 TM_Door_Lock 0 "Init" 1 "door_lock";
VAL_ 1447 TM_Door_Unlock 0 "Init" 1 "door_unlock";
VAL_ 1447 TM_Warnblinken 0 "Init" 1 "Warnblinken_on";
VAL_ 1447 TM_Panik_Alarm 0 "Init" 1 "panik_alarm_on";
VAL_ 1447 TM_ZV_Signatur 0 "Init";
VAL_ 1452 HVEM_IstStrom_HVVerbraucher 4094 "Init" 4095 "Fehler";
VAL_ 1452 HVEM_Energie_Klima_Vorgabe_HighR 6 "Init" 7 "Fehler";
VAL_ 1452 HVEM_IstLeistungNA 510 "Init" 511 "Fehler";
VAL_ 1452 HVEM_Leistung_Klima_Vorgabe 254 "Init" 255 "Fehler";
VAL_ 1452 HVEM_Nutzbare_Energie 2045 "Max" 2046 "Init" 2047 "Fehler";
VAL_ 1452 HVEM_Energie_Klima_Vorgabe 254 "Init" 255 "Fehler";
VAL_ 1452 HVEM_MO_MaxLeistungIgnoriert 0 "Max_Leistung_nicht_ignoriert" 1 "Max_Leistung_ignoriert";
VAL_ 1485 DC_Fehlerstatus 0 "Komponente_IO" 1 "Eingeschr_KompFkt_Entlad_defekt" 3 "Eingeschr_KompFkt_Interlock" 6 "Keine_Komponentenfunktion" 7 "Init";
VAL_ 1485 DC_Peakstrom_verfuegbar 0 "Peakstrom_nicht_verfuegbar" 1 "Peakstrom_verfuegbar";
VAL_ 1485 DC_Abregelung_Temperatur 0 "keine_Abregelung" 1 "Abregelung_Temp";
VAL_ 1485 DC_IstModus_02 0 "Standby" 1 "HV_On_Vorladen" 2 "Tiefsetzen" 3 "Hochsetzen" 4 "Pruefimpuls_12V" 5 "Fehler" 7 "Initialisierung";
VAL_ 1485 DC_HV_EKK_IstModus 0 "Standby" 2 "Tiefsetzen" 3 "Hochsetzen" 5 "Fehler" 7 "Initialisierung";
VAL_ 1485 DC_Status_Spgfreiheit_HV 0 "Init" 1 "HV_Komponente_spannungsfrei" 2 "HV_Komp_nicht_spannungsfrei" 3 "Fehler_nicht_spannungsfrei";
VAL_ 1485 DC_IstSpannung_EKK_HV 255 "Init";
VAL_ 1485 DC_Temperatur 254 "Init" 255 "Fehler";
VAL_ 1505 BCM1_Aussen_Temp_ungef 253 "nicht_verbaut" 254 "Initwert" 255 "Fehler";
VAL_ 1505 BCM_Heizungsabsperrventil_Status 0 "HAV_offen" 1 "HAV_geschlossen" 2 "Init_oder_nicht_verbaut" 3 "Fehler";
VAL_ 1505 BCM_Heizungspumpe_Status 0 "Pumpe_aus" 1 "Pumpe_aktiv_und_Stauts_iO" 2 "Init_oder_nicht_verbaut" 3 "Fehler";
VAL_ 1505 BCM_Kompressorkupplung_Status 0 "Kupplung_offen" 1 "Kupplung_geschlossen" 2 "Init_oder_nicht_verbaut" 3 "Fehler";
VAL_ 1505 BCM1_PTC_stufig_Status 0 "Aus" 1 "Stufe_1_aktiv" 2 "Stufe_2_aktiv" 3 "Stufe_3_aktiv" 6 "Init_oder_nicht_verbaut" 7 "Fehler";
VAL_ 1505 BCM1_FStatus_Aussentemp_ungef 0 "iO" 1 "niO";
VAL_ 1505 BCM1_Kompressorstrom_ist 254 "Init, bzw. nicht verfuegbar" 255 "Fehler";
VAL_ 1505 BCM1_OBD_FStatus_ATemp 0 "kein Fehler / Init / nicht verbaut" 1 "KS- (Kurzschluss nach minus)" 2 "KS+ (Kurzschluss nach plus)" 3 "OC (Leitungsunterbrechung)" 4 "OOR+ (Signal zu gross)" 5 "OOR- (Signal zu klein)" 6 "RC+ (Signal unplausibel zu gross)" 7 "RC- (Signal unplausibel zu klein)" 8 "KS+/OC (Kurzschluss nach plus/Unterbrechung)" 9 "KS-/OC  (Kurzschluss nach minus/Unterbrechung)" 10 "KS-/KS+  (Kurzschluss nach minus/plus)" 11 "KS-/KS+/OC (Kurzschluss nach minus/plus/Unterbrechung)" 12 "frei" 13 "frei" 14 "frei" 15 "frei";
VAL_ 1513 DS_Kaeltemittel_P 2046 "Init" 2047 "Fehler";
VAL_ 1513 DS_Status 0 "i.O." 1 "t.b.d." 2 "Init bzw. nicht verfügbar" 3 "Fehler";
VAL_ 1513 ION_Status 0 "Hochspannung_ausgeschaltet" 1 "Hochspannung_eingeschaltet" 2 "Init";
VAL_ 1513 ION_Status_LED 0 "Aus" 1 "Ein";
VAL_ 1513 AAU_Geblaese 126 "Init" 127 "Fehler";
VAL_ 1513 ION_Status_Taster 0 "nicht_betaetigt" 1 "betaetigt";
VAL_ 1520 DI_KL_58xd 254 "Init" 255 "Fehler";
VAL_ 1520 DI_KL_58xs 126 "Init" 127 "Fehler";
VAL_ 1520 DI_KL_58xt 126 "Init" 127 "Fehler";
VAL_ 1524 IL_Bel_FS_Ausstieg 0 "inaktiv" 1 "aktiv";
VAL_ 1524 IL_Bel_BFS_Ausstieg 0 "inaktiv" 1 "aktiv";
VAL_ 1524 IL_Bel_HFS_Ausstieg 0 "inaktiv" 1 "aktiv";
VAL_ 1524 IL_Bel_HBFS_Ausstieg 0 "inaktiv" 1 "aktiv";
VAL_ 1524 BCM1_Innenlicht_gedimmt_V 0 "100% Innenlicht" 1 "gedimmtes Innenlicht";
VAL_ 1524 BCM1_Innenlicht_gedimmt_H 0 "100% Innenlicht" 1 "gedimmtes Innenlicht";
VAL_ 1524 IL_Innenlicht_aktiv 0 "Innenlicht inaktiv" 1 "Innenlicht aktiv";
VAL_ 1524 IL_Klemme_30G_aktiv 0 "Kl_30G_abgeschaltet" 1 "eingeschaltet";
VAL_ 1524 BCM1_DI_Rampe_Innenlicht 0 "Dimmrampe 0" 1 "Dimmrampe 1";
VAL_ 1524 BCM1_DI_Rampe_Leselicht 0 "Dimmrampe 0" 1 "Dimmrampe 1";
VAL_ 1524 BCM1_Innenlicht_H 0 "Aus" 1 "Ein";
VAL_ 1524 BCM1_Innenlicht_V 0 "Aus" 1 "Ein";
VAL_ 1524 BCM1_Leselicht_Anf_hl 0 "Aus" 1 "Ein";
VAL_ 1524 BCM1_Leselicht_Anf_hr 0 "Aus" 1 "Ein";
VAL_ 1524 BCM1_Leselicht_Anf_vl 0 "Aus" 1 "Ein";
VAL_ 1524 BCM1_Leselicht_Anf_vr 0 "Aus" 1 "Ein";
VAL_ 1524 BCM1_Leuchten_Aus 0 "keine Aenderung" 1 "Aus";
VAL_ 1524 AMB_Charisma_FahrPr 0 "keine_Funktion" 1 "Programm_1" 2 "Programm_2" 3 "Programm_3" 4 "Programm_4" 5 "Programm_5" 6 "Programm_6" 7 "Programm_7" 8 "Programm_8" 9 "Programm_9" 10 "Programm_10" 11 "Programm_11" 12 "Programm_12" 13 "Programm_13" 14 "Programm_14" 15 "Programm_15";
VAL_ 1524 AMB_Charisma_Status 0 "Init" 1 "verfuegbar" 2 "nicht_verfuegbar" 3 "asynchron_durch_Fahrerwunsch";
VAL_ 1600 MO_QBit_Ansaugluft_Temp 0 "gueltiger_Wert" 1 "Ersatz_Init_oder_Fehlerwert";
VAL_ 1600 MO_QBit_Oel_Temp 0 "gueltiger_Wert" 1 "Ersatz_Init_oder_Fehlerwert";
VAL_ 1600 MO_QBit_Kuehlmittel_Temp 0 "gueltiger_Wert" 1 "Ersatz_Init_oder_Fehlerwert";
VAL_ 1600 MO_HYB_Fehler_HV_Netz 0 "i_O" 1 "kein_generatorischer_Betrieb_moeglich";
VAL_ 1600 MO_aktives_Getriebeheizen 0 "kein_Ventil_ansteuern" 1 "Ventil_muss_angesteuert_werden";
VAL_ 1600 MO_Absperrventil_oeffnen 0 "nicht_verfuegbar" 1 "Ansteuerung_Ventil_zulaessig" 2 "Ventil_oeffnen_oder_geoeffnet" 3 "Ventil_schliessen_oder_geschlossen";
VAL_ 1600 MO_Ansaugluft_Temp 254 "Init" 255 "Fehler";
VAL_ 1600 MO_Oel_Temp 253 "nicht_verbaut" 254 "Init" 255 "Fehler";
VAL_ 1600 MO_Kuehlmittel_Temp 254 "Init" 255 "Fehler";
VAL_ 1600 MO_Hoeheninfo 255 "Fehler";
VAL_ 1600 MO_Kennfeldk 0 "keine Kennfeldkühlung vorhanden" 1 "Kennfeldkühlung vorhanden";
VAL_ 1600 MO_Getriebe_kuehlen 0 "nicht_kuehlen" 1 "kuehlen";
VAL_ 1600 MO_Heizungspumpenansteuerung 13 "Fehler" 14 "Init" 15 "nicht_verbaut";
VAL_ 1600 MO_SpannungsAnf 0 "keine_Anforderung" 1 "Anforderung";
VAL_ 1601 MO_Faktor_Momente_02 0 "nicht_belegt";
VAL_ 1601 MO_Hybridfahrzeug 0 "kein_Hybridfahrzeug" 1 "Mild_Hybrid" 2 "Full_Hybrid" 3 "PlugIn_Hybrid";
VAL_ 1601 MO_Getriebe_Code 0 "Init" 2 "DL501" 3 "DL800" 4 "VL381" 5 "DL382_Front" 6 "DL382_Allrad" 7 "DL702" 8 "AL552_Allrad" 9 "AL552_Front" 10 "AL651" 11 "AL551__AL951__AL1000_8A" 12 "PDK_PAG" 13 "AL551_Hybrid" 15 "Handschalter_konventionell" 16 "AQ250_160" 17 "AQ450" 18 "DQ200" 19 "DQ250" 20 "DQ500" 21 "SQ100" 22 "SQ200" 23 "DQ400E" 24 "DQ381" 25 "AL550" 26 "AQ300" 31 "DL800E" 32 "Single_Gear__ohne_GSG_WH_am_MSG" 33 "EQ550_2P";
VAL_ 1601 MO_StartStopp_Codiert 0 "Start_Stopp_nicht_verbaut" 1 "Start_Stopp_verbaut";
VAL_ 1601 MO_Anzahl_Zyl 0 "kein_Zylinder" 1 "1_Zylinder" 2 "2_Zylinder" 3 "3_Zylinder" 4 "4_Zylinder" 5 "5_Zylinder" 6 "6_Zylinder" 7 "7_Zylinder" 8 "8_Zylinder" 9 "9_Zylinder" 10 "10_Zylinder" 11 "11_Zylinder" 12 "12_Zylinder" 13 "15_Zylinder" 14 "16_Zylinder" 15 "18_Zylinder";
VAL_ 1601 MO_Kraftstoffart 0 "Diesel" 1 "Benzin_inkl_E25_E85" 2 "CNG" 3 "LPG" 4 "Wasserstoff" 5 "E100_Ethanol" 15 "kein_Verbrennungskraftstoff";
VAL_ 1601 MO_Ansaugsystem 0 "Turbo" 1 "Sauger";
VAL_ 1601 MO_DPF_verbaut 0 "kein_DPF_verbaut" 1 "DPF_verbaut";
VAL_ 1601 TSK_Codierung 0 "kein_Fahrgeschwindigkeitsregler" 1 "GRA" 2 "GRA_Plus" 3 "Basis_ACC" 4 "ACC_Follow_to_Stop" 5 "ACC_Stop_and_Go" 7 "Codierung_in_Plausibilisierungsphase";
VAL_ 1603 KBI_Einheit_Datum 0 "Tag/Monat/Jahr" 1 "Monat/Tag/Jahr" 2 "Jahr/Monat/Tag" 3 "reserviert";
VAL_ 1603 KBI_Einheit_Druck 0 "Druckangabe in bar" 1 "Druckangabe in psi" 2 "Druckangabe in kPa" 3 "tbd.";
VAL_ 1603 KBI_Einheit_Streckenanz 0 "Kilometer" 1 "Meilen";
VAL_ 1603 KBI_MFA_v_Einheit_02 0 "kmh" 1 "mph";
VAL_ 1603 KBI_Einheit_Temp 0 "Grad Celsius °C" 1 "Grad Fahrenheit °F";
VAL_ 1603 KBI_Einheit_Uhrzeit 0 "24h" 1 "12h AM/PM";
VAL_ 1603 KBI_Einheit_Verbrauch 0 "mpg UK" 1 "mpg USA" 2 "Liter/100km" 3 "km/Liter";
VAL_ 1603 KBI_Einheit_Volumen 0 "Liter" 1 "Gallonen UK" 2 "Gallonen USA" 3 "reserviert";
VAL_ 1603 KBI_Einheit_Verbrauch_elektr 0 "kWh_pro_100km" 1 "km_pro_kWh" 2 "kWh_pro_100mls" 3 "mls_pro_kWh" 4 "MPGe";
VAL_ 1603 KBI_Einheit_Verbrauch_Gas 0 "kg_per_100km" 1 "km_per_kg" 2 "m3_per_100km" 3 "km_per_m3" 4 "miles_per_lbs" 5 "miles_per_yard3" 6 "miles_per_kg" 7 "miles_per_m3" 8 "miles_per_gallon_equivalent_US";
VAL_ 1603 KBI_Einheit_Masse 0 "kg" 1 "lbs" 2 "reserviert";
VAL_ 1622 ELV_Anf_Klemme_S 0 "Aus" 1 "Ein";
VAL_ 1622 ELV_Anf_Klemme_15 0 "Aus" 1 "Ein";
VAL_ 1622 ELV_Anf_Klemme_50 0 "Aus" 1 "Ein";
VAL_ 1622 ELV_01_Sendestatus 0 "ELV_sendet_mit_1000ms" 1 "ELV_sendet_mit_50ms";
VAL_ 1622 ELV_Verriegelt 0 "nicht_verriegelt" 1 "verriegelt";
VAL_ 1622 ELV_Entriegelt 0 "ELV_nicht_entriegelt" 1 "ELV_entriegelt";
VAL_ 1622 ELV_ZAT_betaetigt 0 "nicht_betaetigt" 1 "betaetigt";
VAL_ 1622 ELV_Lebenszustand 0 "Lebenszustand_0" 1 "Lebenszustand_4";
VAL_ 1622 ELV_Anlernmodus 0 "Normalbetrieb" 1 "Anlernmodus";
VAL_ 1622 ELV_Klemmenfreigabe 0 "keine_Freigabe" 1 "Freigabe";
VAL_ 1622 ELV_Abbruch_Anf_Klemmenfreigabe 0 "kein_Abbruch" 1 "Abbruch";
VAL_ 1622 ELV_LED_Rot 0 "Aus" 1 "Ein";
VAL_ 1622 ELV_LED_Gelb 0 "Aus" 1 "Ein";
VAL_ 1622 ELV_Txt_Panikabschaltung 0 "Aus" 1 "Ein";
VAL_ 1622 ELV_Txt_Lkg_Bewegen 0 "Aus" 1 "Ein";
VAL_ 1622 ELV_Txt_Werkstatt 0 "Aus" 1 "Ein";
VAL_ 1622 ELV_Txt_Defekt 0 "Aus" 1 "Ein";
VAL_ 1622 ELV_Txt_P_Gang 0 "Aus" 1 "Ein";
VAL_ 1622 ELV_Txt_PN_Gang 0 "Aus" 1 "Ein";
VAL_ 1622 ELV_Txt_Kupplung 0 "Aus" 1 "Ein";
VAL_ 1622 ELV_Txt_Bremse 0 "Aus" 1 "Ein";
VAL_ 1622 ELV_P_verriegelt 0 "nicht_verriegelt" 1 "verriegelt";
VAL_ 1624 LV_Standlicht_Anzeige 0 "nicht aktiv" 1 "aktiv";
VAL_ 1624 LV_Abblendlicht_Anzeige 0 "inaktiv" 1 "aktiv";
VAL_ 1624 LV_Fernlicht_Anzeige 0 "nicht aktiv" 1 "aktiv";
VAL_ 1624 LV_Nebellicht_Anzeige 0 "nicht aktiv" 1 "aktiv";
VAL_ 1624 LV_Nebelschlusslicht_Anzeige 0 "nicht aktiv" 1 "aktiv";
VAL_ 1624 LV_Tagfahrlicht_Anzeige 0 "nicht aktiv" 1 "aktiv";
VAL_ 1624 LV_AFL_aktiv_Anzeige 0 "nicht aktiv" 1 "aktiv";
VAL_ 1624 LV_AFL_defekt 0 "OK" 1 "defekt";
VAL_ 1624 LV_Blinker_li_def 0 "OK" 1 "defekt";
VAL_ 1624 LV_Standlicht_li_def 0 "OK" 1 "defekt";
VAL_ 1624 LV_Abblendlicht_li_def 0 "OK" 1 "defekt";
VAL_ 1624 LV_Fernlicht_li_def 0 "OK" 1 "defekt";
VAL_ 1624 LV_Nebellicht_li_def 0 "OK" 1 "defekt";
VAL_ 1624 LV_Blk_li_Seite_def 0 "OK" 1 "defekt";
VAL_ 1624 LV_Tagfahrlicht_li_def 0 "OK" 1 "defekt";
VAL_ 1624 LV_FLA_aktiv_Anzeige 0 "aus" 1 "ein";
VAL_ 1624 LV_FLA_defekt 0 "i.O." 1 "FLA defekt";
VAL_ 1624 LV_FLA_Sensor_blockiert 0 "i.O." 1 "FLA-Sensor blockiert";
VAL_ 1624 LV_Blinker_re_def 0 "OK" 1 "defekt";
VAL_ 1624 LV_Standlicht_re_def 0 "OK" 1 "defekt";
VAL_ 1624 LV_Abblendlicht_re_def 0 "OK" 1 "defekt";
VAL_ 1624 LV_Fernlicht_re_def 0 "OK" 1 "defekt";
VAL_ 1624 LV_Nebellicht_re_def 0 "OK" 1 "defekt";
VAL_ 1624 LV_Blk_re_Seite_def 0 "OK" 1 "defekt";
VAL_ 1624 LV_Tagfahrlicht_re_def 0 "OK" 1 "defekt";
VAL_ 1624 LV_Aussenlicht_def 0 "OK" 1 "defekt";
VAL_ 1624 LV_Abblendlicht_TFL_li_def 0 "OK" 1 "defekt";
VAL_ 1624 LV_Nebellicht_TFL_li_def 0 "OK" 1 "defekt";
VAL_ 1624 LV_Standlicht_TFL_li_def 0 "OK" 1 "defekt";
VAL_ 1624 LV_Abblend_Fernlicht_li_def 0 "OK" 1 "defekt";
VAL_ 1624 LV_Abblendlicht_TFL_re_def 0 "OK" 1 "defekt";
VAL_ 1624 LV_Nebellicht_TFL_re_def 0 "OK" 1 "defekt";
VAL_ 1624 LV_Standlicht_TFL_re_def 0 "OK" 1 "defekt";
VAL_ 1624 LV_Abblend_Fernlicht_re_def 0 "OK" 1 "defekt";
VAL_ 1624 LV_Abbiegelicht_li_def 0 "OK" 1 "defekt";
VAL_ 1624 LV_Abbiegelicht_re_def 0 "OK" 1 "defekt";
VAL_ 1624 BCM1_Linksverkehr 0 "Rechtsverkehr" 1 "Linksverkehr";
VAL_ 1624 BCM1_Licht_Dunkelheit_aktiv 0 "inaktiv" 1 "aktiv";
VAL_ 1624 LV_LED_Scheinwerfer_li_def 0 "OK" 1 "defekt";
VAL_ 1624 LV_LED_Scheinwerfer_re_def 0 "OK" 1 "defekt";
VAL_ 1624 LV_Blinker_VL_aktiv 0 "inaktiv" 1 "aktiv";
VAL_ 1624 LV_Blinker_VR_aktiv 0 "inaktiv" 1 "aktiv";
VAL_ 1624 LV_MXB_Status_Anzeige 0 "MXB_aus" 1 "MXB_regelt" 2 "MXB_volles_Fernlicht" 3 "MXB_und_Laser_aktiv";
VAL_ 1629 BR_Systemart 0 "ABS" 1 "ABS_ASR" 2 "ESP" 3 "ESP_mit_integrierter_EPB";
VAL_ 1629 ESP_SpannungsAnf_02 0 "keine_Anforderung" 1 "Anforderung_Stufe1" 2 "Anforderung_Stufe2" 3 "Anforderung_Stufe3";
VAL_ 1629 ESP_Charisma_FahrPr 0 "keine_Funktion" 1 "Programm_1" 2 "Programm_2" 3 "Programm_3" 4 "Programm_4" 5 "Programm_5" 6 "Programm_6" 7 "Programm_7" 8 "Programm_8" 9 "Programm_9" 10 "Programm_10" 11 "Programm_11" 12 "Programm_12" 13 "Programm_13" 14 "Programm_14" 15 "Programm_15";
VAL_ 1629 ESP_Charisma_Status 0 "Init" 1 "verfuegbar" 2 "nicht_verfuegbar" 3 "asynchron_durch_Fahrerwunsch";
VAL_ 1629 ESP_Wiederstart_Anz_01 0 "keine_Anzeige" 1 "Rueckwaertsrollen";
VAL_ 1629 ESP_Wiederstart_Anz_02 0 "keine_Anzeige" 1 "Autohold_Rutschen";
VAL_ 1629 ESP_Wiederstart_Anz_03 0 "keine_Anzeige" 1 "Offroad_HDC";
VAL_ 1629 ESP_Wiederstart_Anz_04 0 "keine_Anzeige" 1 "ESC_Off";
VAL_ 1629 ESP_Stoppverbot_Anz_01 0 "keine_Anzeige" 1 "Notbremsung_aktiv";
VAL_ 1629 ESP_Stoppverbot_Anz_02 0 "keine_Anzeige" 1 "Autohold_AVH_Rutschen";
VAL_ 1629 ESP_Stoppverbot_Anz_03 0 "keine_Anzeige" 1 "Rueckwaertsrollen";
VAL_ 1629 ESP_Stoppverbot_Anz_04 0 "keine_Anzeige" 1 "ESP_Pumpenlauf";
VAL_ 1629 ESP_Stoppverbot_Anz_05 0 "keine_Anzeige" 1 "ESP_OFF";
VAL_ 1629 ESP_Stoppverbot_Anz_06 0 "keine_Anzeige" 1 "Offroad_HDC";
VAL_ 1629 ESP_Stoppverbot_Anz_07 0 "keine_Anzeige" 1 "ESP_Haltefunktion_nicht_verfuegbar";
VAL_ 1629 ESP_Stoppverbot_Anz_Std 0 "keine_Anzeige" 1 "Standard_Stoppvetogrund";
VAL_ 1629 ESP_Dachrelingsensor 0 "Sensor_nicht_verbaut" 1 "Quertraeger_montiert" 2 "Quertraeger_nicht_montiert" 3 "Fehler";
VAL_ 1629 ESP_Stoppverbot_Anz_08 0 "keine_Anzeige" 1 "Neigungsbegrenzung";
VAL_ 1629 HDC_Charisma_FahrPr 0 "keine_Funktion" 1 "Programm_1" 2 "Programm_2" 3 "Programm_3" 4 "Programm_4" 5 "Programm_5" 6 "Programm_6" 7 "Programm_7" 8 "Programm_8" 9 "Programm_9" 10 "Programm_10" 11 "Programm_11" 12 "Programm_12" 13 "Programm_13" 14 "Programm_14" 15 "Programm_15";
VAL_ 1629 HDC_Charisma_Status 0 "Init" 1 "verfuegbar" 2 "nicht_verfuegbar" 3 "asynchron_durch_Fahrerwunsch";
VAL_ 1629 BR_QBit_Reifenumfang 0 "gueltiger_Wert" 1 "Ersatz_Init_oder_Fehlerwert";
VAL_ 1631 TSK_QBit_Steigung 0 "gueltiger_Wert" 1 "Ersatz_Init_oder_Fehlerwert";
VAL_ 1631 TSK_QBit_Fahrzeugmasse 0 "gueltiger_Wert" 1 "Ersatz_Init_oder_Fehlerwert";
VAL_ 1631 MO_SpannungsAnf_02 0 "keine_Anforderung" 1 "Anforderung_Stufe_1" 2 "Anforderung_Stufe_2" 3 "Anforderung_Stufe_3";
VAL_ 1631 MO_DPF_reg 0 "DPF_regeneriert_nicht" 1 "DPF_regeneriert";
VAL_ 1631 MO_Heizstrom_EKAT 127 "Fehler";
VAL_ 1631 MO_Heizstrom_SCR 63 "Fehler";
VAL_ 1631 MO_Anzeige_Kaltleuchte 0 "Lampe_aus" 1 "Lampe_an";
VAL_ 1631 MO_P_Generator_ungefiltert_Anf 0 "nicht_angefordert" 1 "angefordert";
VAL_ 1631 TSK_Getriebeinfo 0 "Handschalter" 1 "AL_AQ_Getriebe" 2 "DL_DQ_Getriebe" 3 "CVT_Getriebe";
VAL_ 1631 MO_Energieinhalt_BMS 4094 "Init" 4095 "Fehler";
VAL_ 1631 TSK_Fahrzeugmasse_02 255 "Fehler";
VAL_ 1631 TSK_Steigung_02 0 "Init_oder_nicht_verbaut" 255 "Fehler";
VAL_ 1640 KL_LRH_Taster 0 "nicht_betaetigt" 1 "betaetigt";
VAL_ 1640 KL_LRH_Stufe 0 "Stufe_niedrig" 1 "Stufe_mittel" 2 "Stufe_hoch" 3 "AUS";
VAL_ 1640 HSH_Taster 0 "nicht_betaetigt" 1 "short_push" 2 "long_push" 3 "tbd";
VAL_ 1640 FSH_Taster 0 "nicht_betaetigt" 1 "betaetigt";
VAL_ 1640 KL_Zuheizer_Freigabe 0 "keine_Freigabe_Zuheizer" 1 "Zuheizerfreigabe";
VAL_ 1640 KL_Beschlagsgefahr 0 "keine_Beschlagsgefahr" 1 "Beschlagsgefahr";
VAL_ 1640 KRH_Soll_li 0 "aus" 1 "Stufe_1" 2 "Stufe_2" 3 "Stufe_3";
VAL_ 1640 KRH_Soll_re 0 "aus" 1 "Stufe_1" 2 "Stufe_2" 3 "Stufe_3";
VAL_ 1640 KL_Geblspng_Soll 0 "0V_Motorspannung" 252 "0V_sofort_Abschalten" 253 "0V_senken_mit_Rampe" 254 "reserviert" 255 "Fehler";
VAL_ 1640 KL_Geblspng_Fond_Soll 0 "0V_Motorspannung" 252 "0V_sofort_Abschalten" 253 "0V_senken_mit_Rampe" 254 "reserviert" 255 "Fehler";
VAL_ 1640 KL_I_Geblaese 255 "Fehler";
VAL_ 1640 KL_Kompressorstrom_soll 1022 "Init" 1023 "Fehler";
VAL_ 1640 KL_Umluftklappe_Status 0 "Frischluft" 1 "Teilumluft_10" 2 "Teilumluft_20" 3 "Teilumluft_30" 4 "Teilumluft_40" 5 "Teilumluft_50" 6 "Teilumluft_60" 7 "Teilumluft_70" 8 "Teilumluft_80" 9 "Teilumluft_90" 10 "Umluft" 14 "Init" 15 "Fehler";
VAL_ 1640 KL_PTC_Verbauinfo 0 "kein_PTC" 1 "600W_geschaltet" 2 "1000W_geschaltet" 3 "1400W_LIN";
VAL_ 1648 MO_ANC_Kennfeld_Anf 0 "Kennfeld_1" 1 "Uebergang_Kennfeld_2_nach_1" 2 "Uebergang_Kennfeld_1_nach_2" 3 "Kennfeld_2";
VAL_ 1648 MO_Bremslicht_Reku 0 "Aus" 1 "Ein";
VAL_ 1648 MO_StartStopp_PopUp 0 "Statuswechsel_ohne_Taster (Init)" 1 "StSt_per_Taster_deaktiviert" 2 "StSt_per_Taster_aktiviert" 3 "nicht verwendet";
VAL_ 1648 MO1_Sperr_Info_WFS 0 "nicht_gesperrt" 1 "gesperrt";
VAL_ 1648 MO1_Freigabe_Info_WFS 0 "ungueltig" 1 "gueltig";
VAL_ 1648 MO_EPCL 0 "EPCL_aus_kein_Text" 1 "EPCL_gelb_Stoerung" 2 "EPCL_gelb_Leistungsbeschraenkung" 3 "EPCL_rot_Fzg_sicher_abstellen";
VAL_ 1648 MO_Zylabsch_Texte_02 0 "ein_ZAS_generell_keine_ZAS_Anzeigen" 1 "ZAS_im_VMB" 2 "ZAS_im_ASB_1_Zyl_aktiv" 3 "ZAS_im_ASB_2_Zyl_aktiv" 4 "ZAS_im_ASB_3_Zyl_aktiv" 5 "ZAS_im_ASB_4_Zyl_aktiv" 6 "ZAS_im_ASB_5_Zyl_aktiv" 7 "ZAS_im_ASB_6_Zyl_aktiv" 8 "ZAS_im_ASB_8_Zyl_aktiv" 9 "ZAS_im_ASB_12_Zyl_aktiv" 13 "Uebergangsbetrieb" 14 "keine_ZAS_Anzeige_ggf_Stopp_Schub_Betrieb" 15 "ZAS_Stoerungs_Anzeige";
VAL_ 1648 MO_Fahrzeugtyp 0 "Verbrenner_Fahrzeug" 1 "Hybrid" 2 "E_Fahrzeug" 3 "E_Fahrzeug_mit_Range_Extender" 4 "Brennstoffzellenfahrzeug" 5 "tbd" 6 "tbd" 7 "tbd";
VAL_ 1648 MO_Abstellzeit 254 "Init" 255 "reserviert";
VAL_ 1648 MO_Abstellzeit_Status 0 "Abstellzeit_nicht_berechnet" 1 "Abstellzeit_berechnet" 2 "Abstellzeit_Minimalwert" 3 "Abstellzeit_ungueltig";
VAL_ 1648 MO1_Freigabe_Verfallsinfo_WFS 0 "verfaellt_nicht" 1 "verfaellt";
VAL_ 1648 MO_Hybrid_StartStopp_LED 0 "LED_aus_und_Blinken_aus" 1 "LED_ein_und_Blinken_aus" 2 "LED_ein_und_Blinken_ein_50_percent" 3 "reserviert";
VAL_ 1648 MO_Fehler_Zylabsch 0 "kein_Fehler" 1 "Notlauf_Vollmotorbetrieb" 2 "Notlauf_mindestens_einem_abgesch_Zylinder";
VAL_ 1648 MO_Anzahl_Abgesch_Zyl 0 "Vollmotorbetrieb" 1 "1_Zylinder_abgeschaltet" 2 "2_Zylinder_abgeschaltet" 3 "3_Zylinder_abgeschaltet" 4 "4_Zylinder_abgeschaltet" 5 "5_Zylinder_abgeschaltet" 6 "6_Zylinder_abgeschaltet" 7 "8_Zylinder_abgeschaltet";
VAL_ 1648 MO_Zylabsch_Texte 0 "keine_Texte" 1 "Zylinderabschaltung_deaktivieren" 2 "Zylinderabschaltung_aktivieren" 3 "Zylinderabschaltung_unruhig";
VAL_ 1648 MO_Ethanol_BS_Texte 0 "kein_Text" 1 "E85_Warm_Up" 2 "FlexFuel_Warnung_Stufe_3" 3 "Warmfahrempfehlung_MQB__FlexFuel_Warnung_Stufe_1" 4 "FlexFuel_Warnung_Stufe_2" 5 "FlexFuel_Warnung_Stufe_4" 6 "E25_Warm_Up";
VAL_ 1648 MO_Drehzahl_Warnung 0 "keinen_Warnhinweis_anzeigen" 1 "Warnhinweis_anzeigen";
VAL_ 1648 MO_obere_Drehzahlgrenze 0 "Init";
VAL_ 1710 SP_FT_oben 0 "nicht_betaetigt" 1 "betaetigt";
VAL_ 1710 SP_FT_unten 0 "nicht_betaetigt" 1 "betaetigt";
VAL_ 1710 SP_FT_links 0 "nicht_betaetigt" 1 "betaetigt";
VAL_ 1710 SP_FT_rechts 0 "nicht_betaetigt" 1 "betaetigt";
VAL_ 1710 SP_BT_oben 0 "nicht_betaetigt" 1 "betaetigt";
VAL_ 1710 SP_BT_unten 0 "nicht_betaetigt" 1 "betaetigt";
VAL_ 1710 SP_BT_links 0 "nicht_betaetigt" 1 "betaetigt";
VAL_ 1710 SP_BT_rechts 0 "nicht_betaetigt" 1 "betaetigt";
VAL_ 1710 SP_abklappen 0 "Spiegel_abklappen_nicht_aktiv" 1 "Spiegel_abklappen_aktiv";
VAL_ 1710 SP_anklappen 0 "Spiegle_anklappen_nicht_aktiv" 1 "Spiegel_anklappen_aktiv";
VAL_ 1710 SP_normieren 0 "Spiegel_nicht_normiert" 1 "Spiegel_normiert";
VAL_ 1710 SP_Hzg_Taster 0 "nicht_betaetigt" 1 "betaetigt";
VAL_ 1710 SP_S_oben 1 "Spiegelschalter in Stellung oben";
VAL_ 1710 SP_S_unten 1 "Spiegelschalter in Stellung unten";
VAL_ 1710 SP_S_links 1 "Spiegelschalter in Stellung links";
VAL_ 1710 SP_S_rechts 1 "Spiegelschalter in Stellung rechts";
VAL_ 1710 SP_Auswahl_li 1 "Spiegelschalter in Stellung Auswahl links";
VAL_ 1710 SP_Auswahl_re 1 "Spiegelschalter in Stellung Auswahl rechts";
VAL_ 1710 SP_ARA_Status 0 "TSG nicht im ARA-Modus" 1 "TSG im ARA-Modus";
VAL_ 1710 SP_S_Klappen 1 "Spiegelschalter in Stellung Klappen";
VAL_ 1710 SP_Verstellschalter_Fehler 0 "kein_Fehler" 1 "Fehler";
VAL_ 1711 RV_Video_on 0 "Kamerabild wird nicht angezeigt" 1 "Kamerabild wird angezeigt";
VAL_ 1711 RV_Dark_Screen 0 "Kamerabild nicht verdunkeln" 1 "Kamerabild verdunkeln";
VAL_ 1711 RV_HMI_Mode 0 "Parkluecke  (Modus 1)" 1 "Parallel zur Straߥ (Modus 2)" 2 "reserviert" 3 "Kalibrierung (nur Diagnose)";
VAL_ 1711 RV_GL_side 0 "Guidelines_abgeschaltet" 1 "Guidelines_Anzeige_rechte_Seite" 2 "Guiedelines_Anzeige_linke_Seite" 3 "Guiedelines_Anzeige_beide_Seiten";
VAL_ 1711 RV_System_aktiv 0 "System nicht betriebsbereit" 1 "System betriebsbereit";
VAL_ 1711 RV_Reinigung_Anf 0 "nicht_reinigen" 1 "reinigen";
VAL_ 1711 RV_Settings_enabled 0 "Menu 'Einstellungen' nicht aktiviert" 1 "Menu 'Einstellungen' aktiviert";
VAL_ 1711 RV_Menu_Item 0 "HMI Mode als ausgewaehlt markiert" 1 "Helligkeit als ausgewaehlt markiert" 2 "Kontrast als ausgewaehlt markiert" 3 "Farbsaettigung als ausgewaehlt markiert";
VAL_ 1711 SV_Video_on 0 "SideView_aus_/_nicht_verbaut" 1 "SideView_an";
VAL_ 1711 RV_Calib_Fehler 0 "Kalibrierung_i.O." 1 "RearView_nicht_kalibriert";
VAL_ 1711 RV_GL_Trailer_connect 0 "Guidelines_werden_angezeigt" 1 "Guidelines_wegen_angekoppeltem_Anh䮧er_deaktiviert";
VAL_ 1711 RV_GL_Trunk_open 0 "Guidelines_werden_angezeigt" 1 "Guidelines_wegen_geöffneter_Heckklappe_deaktiviert";
VAL_ 1711 RV_GL_LWS_Fehler 0 "Guidelines_werden_angezeigt" 1 "Guidelines_wegen_nicht_kalibriertem_Lenkwinkelsensor_deaktiviert";
VAL_ 1711 ZFAS_Umfeldbeleuchtung_Anf 0 "nicht_angefordert" 1 "angefordert";
VAL_ 1714 DGN_Verlernzaehler 255 "ungültiger Z䨬erstand oder kein gültiger Fahrzyklus";
VAL_ 1714 UH_Monat 0 "Init" 14 "Relatives_Datum" 15 "Fehler";
VAL_ 1714 UH_Tag 0 "Init";
VAL_ 1714 Kombi_02_alt 0 "aktuell" 1 "veraltet";
VAL_ 1714 Uhrzeit_01_alt 0 "aktuell" 1 "veraltet";
VAL_ 316495015 VZE_Anzeigemodus 0 "EU_RDW" 1 "USA" 2 "Canada" 3 "China";
VAL_ 316495015 VZE_Verkehrszeichen_Einheit 0 "mph" 1 "kmh";
VAL_ 316495015 VZE_Anzeigeunterdrueck_Zeichen_3 0 "anzeigerelevant" 1 "nicht_anzeigerelevant";
VAL_ 316495015 VZE_Anzeigeunterdrueck_Zeichen_2 0 "anzeigerelevant" 1 "nicht_anzeigerelevant";
VAL_ 316495015 VZE_Verkehrszeichen_1_Typ 0 "Geschwindigkeitszeichen" 1 "Kein Geschwindigkeitszeichen";
VAL_ 316495015 VZE_Verkehrszeichen_1 0 "kein_Verkehrszeichen" 520 "Unbegrenzt";
VAL_ 316495015 VZE_Verkehrszeichen_2_Typ 0 "Geschwindigkeitszeichen" 1 "Kein Geschwindigkeitszeichen";
VAL_ 316495015 VZE_Verkehrszeichen_2 0 "kein_Verkehrszeichen" 520 "Unbegrenzt";
VAL_ 316495015 VZE_Verkehrszeichen_3_Typ 0 "Geschwindigkeitszeichen" 1 "Kein Geschwindigkeitszeichen";
VAL_ 316495015 VZE_Verkehrszeichen_3 0 "kein_Verkehrszeichen" 520 "Unbegrenzt";
VAL_ 316495015 VZE_Warnung_Verkehrszeichen_1 0 "keine_Warnung_Initialwert_Fehlerwert" 1 "Warnung";
VAL_ 316495015 VZE_Warnung_Verkehrszeichen_2 0 "keine_Warnung_Initialwert_Fehlerwert" 1 "Warnung";
VAL_ 316495015 VZE_Warnung_Verkehrszeichen_3 0 "keine_Warnung_Initialwert_Fehlerwert" 1 "Warnung";
VAL_ 316495015 VZE_Zusatzschild_1 0 "keine_Zusatzschild_Initialwert_Fehlerwert";
VAL_ 316495015 VZE_Zusatzschild_2 0 "keine_Zusatzschild_Initialwert_Fehlerwert";
VAL_ 316495015 VZE_Zusatzschild_3 0 "keine_Zusatzschild_Initialwert_Fehlerwert";
VAL_ 316495015 VZE_Anzeigeunterdrueck_Zeichen_1 0 "anzeigerelevant" 1 "nicht_anzeigerelevant";
VAL_ 316495015 VZE_Zeichen_01_KameraWied 0 "inaktiv" 1 "aktiv";
VAL_ 316495015 VZE_Zeichen_02_KameraWied 0 "inaktiv" 1 "aktiv";
VAL_ 316495015 VZE_Zeichen_03_KameraWied 0 "inaktiv" 1 "aktiv";
VAL_ 316495015 VZE_Zeichen_01_Kamera 0 "nicht_erkannt" 1 "erkannt";
VAL_ 316495015 VZE_Zeichen_01_Karte 0 "inaktiv" 1 "aktiv";
VAL_ 316495015 VZE_Zeichen_01_Gesetz 0 "nicht_erkannt" 1 "erkannt";
VAL_ 316495015 VZE_Zeichen_02_Kamera 0 "nicht_erkannt" 1 "erkannt";
VAL_ 316495015 VZE_Zeichen_02_Karte 0 "inaktiv" 1 "aktiv";
VAL_ 316495015 VZE_Zeichen_02_Gesetz 0 "nicht_erkannt" 1 "erkannt";
VAL_ 316495015 VZE_Zeichen_03_Kamera 0 "nicht_erkannt" 1 "erkannt";
VAL_ 316495015 VZE_Zeichen_03_Karte 0 "inaktiv" 1 "aktiv";
VAL_ 316495015 VZE_Zeichen_03_Gesetz 0 "nicht_erkannt" 1 "erkannt";
VAL_ 316495015 VZE_Gong 0 "Gong_deaktiv" 1 "Gong_aktiv";
VAL_ 441800114 Temperature_Status_Charge 0 "init" 1 "temp under optimal" 2 "temp optimal" 3 "temp over optimal" 7 "fault";

BO_ 258 ESC_50: 48 XXX
 SG_ CHECKSUM : 0|8@1+ (1,0) [0|255] "" XXX
 SG_ COUNTER : 8|4@1+ (1,0) [0|15] "" XXX
 SG_ Lateral_Accel : 16|8@1+ (0.15,-18.9) [0|255] "Unit_MeterPerSquareSecond" XXX
 SG_ Longitudinal_Accel : 24|10@1+ (0.03125,-16) [0|255] "Unit_MeterPerSquareSecond" XXX
 SG_ Yaw_Rate : 40|14@1+ (0.01,0) [0|16383] "Unit_DegreePerSecond" XXX
 SG_ Yaw_Rate_Sign : 54|1@0+ (1,0) [0|1] "" XXX
 SG_ Brake_Power : 80|8@1+ (1,-100) [0|255] "" XXX
 SG_ Brake_01 : 90|1@0+ (1,0) [0|1] "" XXX
 SG_ Regen_Braking : 123|1@1+ (1,0) [0|7] "" XXX
 SG_ Brake_02 : 125|1@0+ (1,0) [0|1] "" XXX
 SG_ Motion_State : 171|2@0+ (1,0) [0|1] "" XXX
 SG_ NEW_SIGNAL_3 : 180|1@0+ (1,0) [0|1] "" XXX
 SG_ Longitudinal_Speed : 181|10@1+ (0.25,0) [0|255] "Unit_KilometerPerHour" XXX
 SG_ Brake_Power_02 : 226|8@1+ (1,-100) [0|63] "" XXX
 SG_ NEW_SIGNAL_2 : 236|9@1+ (1,0) [0|7] "" XXX
 SG_ NEW_SIGNAL_1 : 248|4@1+ (1,0) [0|15] "" XXX
 SG_ EPB_Status : 317|3@1+ (1,0) [0|7] "" XXX

BO_ 252 ESC_51: 48 XXX
 SG_ CHECKSUM : 0|8@1+ (1,0) [0|255] "" XXX
 SG_ COUNTER : 8|4@1+ (1,0) [0|15] "" XXX
 SG_ NEW_SIGNAL_2 : 14|6@1+ (1,0) [0|3] "" XXX
 SG_ AEB_Breaking_01 : 24|8@1+ (1,0) [0|255] "" XXX
 SG_ AEB_Breaking_02 : 32|8@1+ (1,0) [0|255] "" XXX
 SG_ Accelerator_Higher_Speed : 40|1@0+ (1,0) [0|1] "" XXX
 SG_ Brake_Pressure : 42|9@1+ (0.195,0) [0|100] "Unit_Percent" XXX
 SG_ NEW_SIGNAL_1 : 52|8@1+ (1,0) [0|15] "" XXX
 SG_ HL_Radgeschw : 64|16@1+ (0.0075,0) [0|491.5125] "Unit_KilometerPerHour" XXX
 SG_ HR_Radgeschw : 80|16@1+ (0.0075,0) [0|491.5125] "Unit_KilometerPerHour" XXX
 SG_ VL_Radgeschw : 96|16@1+ (0.0075,0) [0|491.5125] "Unit_KilometerPerHour" XXX
 SG_ VR_Radgeschw : 112|16@1+ (0.0075,0) [0|491.5125] "Unit_KilometerPerHour" XXX
 SG_ NEW_SIGNAL_3 : 128|4@1+ (1,0) [0|15] "" XXX
 SG_ HL_Brake_Pressure : 152|8@1+ (1,0) [0|100] "" XXX
 SG_ HR_Brake_Pressure : 160|8@1+ (1,0) [0|100] "" XXX
 SG_ VL_Brake_Pressure : 168|8@1+ (1,0) [0|100] "" XXX
 SG_ VR_Brake_Pressure : 176|8@1+ (1,0) [0|100] "" XXX
 SG_ Steering_Wheel_CW : 184|8@1+ (1.67,0) [0|255] "" XXX
 SG_ Steering_Wheel_CCW : 192|8@1+ (1.67,0) [0|255] "" XXX
 SG_ ESC_v_Signal : 328|13@1+ (0.052,-107.016) [0|63] "" XXX
 SG_ NEW_SIGNAL_4 : 342|13@1+ (1,0) [0|3] "" XXX

BO_ 219 AWV_03: 48 XXX
 SG_ CHECKSUM : 0|8@1+ (1,0) [0|255] "" XXX
 SG_ COUNTER : 8|4@1+ (1,0) [0|15] "" XXX
 SG_ Unknown_01 : 12|3@1+ (1,0) [0|3] "" XXX
 SG_ SET_ME_63 : 18|6@1+ (1,0) [0|63] "" XXX
 SG_ Unknown_02 : 25|2@1+ (1,0) [0|3] "" XXX
 SG_ SET_ME_30 : 27|5@1+ (1,0) [0|15] "" XXX
 SG_ SET_ME_127 : 33|7@1+ (1,0) [0|127] "" XXX
 SG_ Unknown_03 : 40|1@0+ (1,0) [0|1] "" XXX
 SG_ SET_ME_127_2 : 41|7@1+ (1,0) [0|127] "" XXX
 SG_ Pre_FCW : 64|1@0+ (1,0) [0|1] "" XXX
 SG_ SET_ME_63_2 : 66|6@1+ (1,0) [0|63] "" XXX
 SG_ SET_ME_15_1 : 72|4@1+ (1,0) [0|15] "" XXX
 SG_ FCW_Active : 76|1@0+ (1,0) [0|1] "" XXX
 SG_ SET_ME_255 : 80|8@1+ (1,0) [0|255] "" XXX
 SG_ SET_ME_1023 : 94|10@1+ (1,0) [0|3] "" XXX
 SG_ SET_ME_1 : 129|1@0+ (1,0) [0|1] "" XXX

BO_ 267 Motor_51: 32 XXX
 SG_ CHECKSUM : 0|8@1+ (1,0) [0|255] "" XXX
 SG_ COUNTER : 8|4@1+ (1,0) [0|15] "" XXX
 SG_ Accel_Pedal_Pressure : 12|9@1+ (0.4,0) [0|255] "" XXX
 SG_ Accel_Low_Pressed_Support : 21|1@1+ (1,0) [0|7] "" XXX
 SG_ TSK_Status : 88|3@1+ (1,0) [0|7] "" XXX
 SG_ TSK_Limiter_ausgewaehlt : 95|1@1+ (1,0) [0|3] "" XXX

BO_ 317 QFK_01: 32 XXX
 SG_ CHECKSUM : 0|8@1+ (1,0) [0|255] "" XXX
 SG_ COUNTER : 8|4@1+ (1,0) [0|15] "" XXX
 SG_ NEW_SIGNAL_5 : 12|1@0+ (1,0) [0|1] "" XXX
 SG_ HCA_No_Override : 14|1@0+ (1,0) [0|1] "" XXX
 SG_ NEW_SIGNAL_8 : 16|1@0+ (1,0) [0|1] "" XXX
 SG_ LatCon_HCA_Accept : 17|2@1+ (1,0) [0|3] "" XXX
 SG_ NEW_SIGNAL_2 : 19|1@0+ (1,0) [0|1] "" XXX
 SG_ LatCon_HCA_Status : 20|3@1+ (1,0) [0|15] "" XXX
 SG_ NEW_SIGNAL_1 : 23|1@0+ (1,0) [0|1] "" XXX
 SG_ NEW_SIGNAL_10 : 24|1@0+ (1,0) [0|1] "" XXX
 SG_ NEW_SIGNAL_6 : 30|3@0+ (1,0) [0|1] "" XXX
 SG_ NEW_SIGNAL_7 : 34|3@0+ (1,0) [0|1] "" XXX
 SG_ Steering_Angle_VZ : 36|1@0+ (1,0) [0|1] "" XXX
 SG_ Curvature : 40|15@1+ (6.7e-06,0) [0|65535] "" XXX
 SG_ Curvature_VZ : 55|1@0+ (1,0) [0|1] "" XXX
 SG_ NEW_SIGNAL_3 : 56|7@1+ (1,0) [0|63] "" XXX
 SG_ NEW_SIGNAL_4 : 63|1@0+ (1,0) [0|1] "" XXX
 SG_ Steering_Angle : 76|17@1+ (0.00906,0) [0|32767] "" XXX

BO_ 389241616 MEB_Camera_09: 8 XXX

BO_ 313 VMM_02: 32 XXX
 SG_ CHECKSUM : 0|8@1+ (1,0) [0|255] "" XXX
 SG_ COUNTER : 8|4@1+ (1,0) [0|15] "" XXX
 SG_ FCW_Reaction_1 : 12|1@0+ (1,0) [0|1] "" XXX
 SG_ Brake_Pressed_1 : 16|1@0+ (1,0) [0|1] "" XXX
 SG_ Brake_Pressed_2 : 27|1@0+ (1,0) [0|1] "" XXX
 SG_ AEB_Active : 31|1@0+ (1,0) [0|1] "" XXX
 SG_ ESP_Hold : 35|1@0+ (1,0) [0|1] "" XXX
 SG_ Brake_Pressed_3 : 48|1@0+ (1,0) [0|1] "" XXX
 SG_ FCW_Reaction_2 : 56|1@1+ (1,0) [0|1] "" XXX
 SG_ Brake_Pressure : 76|11@1+ (1,0) [0|100] "" XXX
 SG_ FCW_Reaction_3 : 88|5@1+ (1,0) [0|31] "" XXX

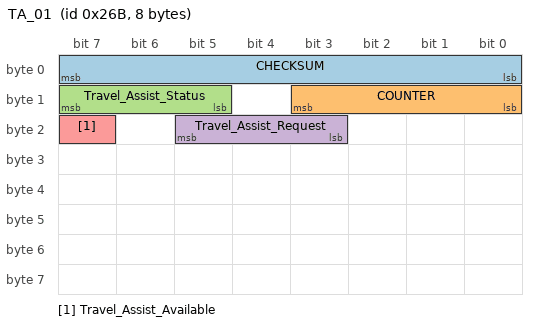
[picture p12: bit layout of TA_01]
BO_ 619 TA_01: 8 XXX
 SG_ CHECKSUM : 0|8@1+ (1,0) [0|255] "" XXX
 SG_ COUNTER : 8|4@1+ (1,0) [0|15] "" XXX
 SG_ Travel_Assist_Status : 13|3@1+ (1,0) [0|3] "" XXX
 SG_ Travel_Assist_Request : 19|3@1+ (1,0) [0|7] "" XXX
 SG_ Travel_Assist_Available : 23|1@1+ (1,0) [0|1] "" XXX

VAL_ 258 Motion_State 1 "Forwards" 2 "Reversing" 3 "Stopped";
VAL_ 258 EPB_Status 0 "offen" 1 "geschlossen_Parken" 2 "teilgespannt_Halten" 3 "im_Lauf_oeffnen" 4 "im_Lauf_schliessen" 5 "tbd" 6 "Init" 7 "unbekannt";
VAL_ 267 TSK_Status 0 "init" 1 "disabled" 2 "enabled" 3 "regulating" 4 "accel_pedal_override" 5 "brake_only" 6 "temp_fault" 7 "perm_fault";
VAL_ 317 LatCon_HCA_Status 0 "disabled" 1 "initializing" 2 "ready" 3 "fault" 4 "active" 5 "preempted" 6 "fault" 7 "rejected";
VAL_ 619 Travel_Assist_Status 4 "enabled" 0 "disabled" 2 "ready" 3 "pre_ready";
VAL_ 619 Travel_Assist_Request 4 "enable" 3 "disable" 0 "no_request" 1 "error";
VAL_ 619 Travel_Assist_Available 0 "not_available" 1 "available";
